VERSION "HNNBNNNYNNNNNNNNNNNNNNNNNNNNNNNNNNNNNNNNNN/4/%%%/4/'%**4NNN///"

NS_ :

BS_:

BU_: BAP_Tester BedienDisp_vo BedienSG_hi CGS DDA Gateway Gateway_PAG GurtMikrofon OTA_FC ZR_High ZR_LIMU ZR_MIB_TOP_ab_Gen3 ZR_Standard

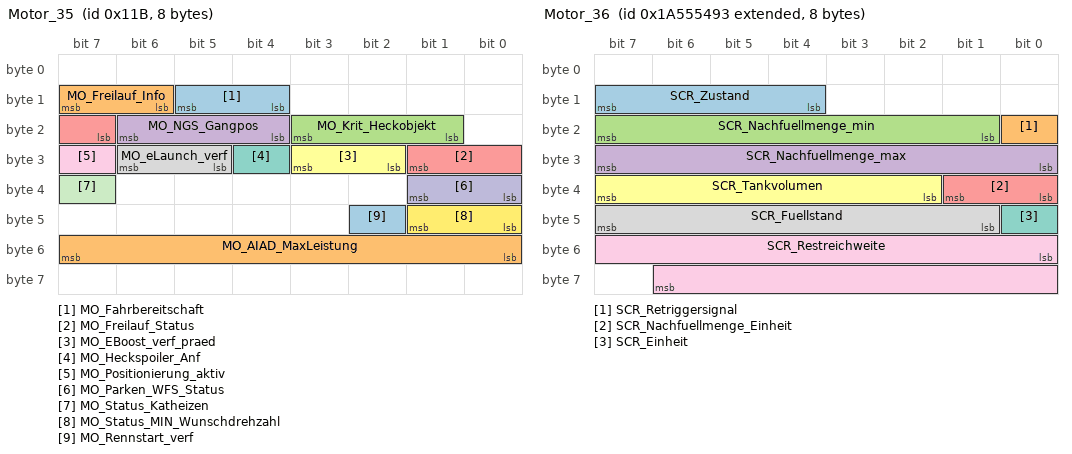
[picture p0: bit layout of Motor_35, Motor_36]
BO_ 283 Motor_35: 8 Gateway
 SG_ MO_Fahrbereitschaft : 12|2@1+ (1.0,0.0) [0.0|3] ""  DDA,OTA_FC
 SG_ MO_Freilauf_Info : 14|2@1+ (1.0,0.0) [0.0|3] ""  Vector__XXX
 SG_ MO_Krit_Heckobjekt : 17|3@1+ (1.0,0.0) [0.0|7] ""  ZR_High,ZR_LIMU,ZR_MIB_TOP_ab_Gen3
 SG_ MO_NGS_Gangpos : 20|3@1+ (1.0,0.0) [0.0|7] ""  Vector__XXX
 SG_ MO_Freilauf_Status : 23|3@1+ (1.0,0.0) [0.0|7] ""  Vector__XXX
 SG_ MO_EBoost_verf_praed : 26|2@1+ (1.0,0.0) [0.0|3] ""  Vector__XXX
 SG_ MO_Heckspoiler_Anf : 28|1@1+ (1.0,0.0) [0.0|1] ""  Vector__XXX
 SG_ MO_eLaunch_verf : 29|2@1+ (1.0,0.0) [0.0|3] ""  Vector__XXX
 SG_ MO_Positionierung_aktiv : 31|1@1+ (1.0,0.0) [0.0|1] ""  Vector__XXX
 SG_ MO_Parken_WFS_Status : 32|2@1+ (1.0,0.0) [0.0|3] ""  Vector__XXX
 SG_ MO_Status_Katheizen : 39|1@1+ (1.0,0.0) [0.0|1] ""  Vector__XXX
 SG_ MO_Status_MIN_Wunschdrehzahl : 40|2@1+ (1.0,0.0) [0.0|3] ""  Vector__XXX
 SG_ MO_Rennstart_verf : 42|1@1+ (1.0,0.0) [0.0|1] ""  Vector__XXX
 SG_ MO_AIAD_MaxLeistung : 48|8@1+ (100,0) [0|25400] "Unit_Watt"  Vector__XXX

BO_ 2589283475 Motor_36: 8 Gateway
 SG_ SCR_Zustand : 12|4@1+ (1.0,0.0) [0.0|15] ""  ZR_High,ZR_Standard
 SG_ SCR_Retriggersignal : 16|1@1+ (1.0,0.0) [0.0|1] ""  ZR_High,ZR_Standard
 SG_ SCR_Nachfuellmenge_min : 17|7@1+ (0.25,0) [0.00|31.50] ""  ZR_High,ZR_Standard
 SG_ SCR_Nachfuellmenge_max : 24|8@1+ (0.25,0) [0.00|63.50] ""  ZR_High,ZR_Standard
 SG_ SCR_Nachfuellmenge_Einheit : 32|2@1+ (1.0,0.0) [0.0|3] ""  ZR_High,ZR_Standard
 SG_ SCR_Tankvolumen : 34|6@1+ (1,0) [0|63] ""  ZR_High,ZR_Standard
 SG_ SCR_Einheit : 40|1@1+ (1.0,0.0) [0.0|1] ""  ZR_High,ZR_Standard
 SG_ SCR_Fuellstand : 41|7@1+ (1,0) [0|100] "Unit_PerCent"  ZR_High,ZR_Standard
 SG_ SCR_Restreichweite : 48|15@1+ (1,0) [0|32767] ""  ZR_High,ZR_Standard

BO_ 706 Motor_41: 8 Gateway
 SG_ MO_Anzeige_StSt_Text : 12|4@1+ (1.0,0.0) [0.0|15] ""  Vector__XXX
 SG_ MO_Anzeige_StSt_Symbol : 16|3@1+ (1.0,0.0) [0.0|7] ""  Vector__XXX
 SG_ MO_ADR_Status : 19|2@1+ (1.0,0.0) [0.0|3] ""  ZR_High
 SG_ MO_AGA_Sound_Texte : 21|2@1+ (1.0,0.0) [0.0|3] ""  Vector__XXX
 SG_ MO_Anzeige_FMAus_Text : 23|1@1+ (1.0,0.0) [0.0|1] ""  Vector__XXX
 SG_ MO_Fehler_MSpG : 24|1@1+ (1.0,0.0) [0.0|1] ""  Vector__XXX
 SG_ PEA_Texte : 25|3@1+ (1.0,0.0) [0.0|7] ""  Vector__XXX
 SG_ TSK_Ueberstimmt_vMax_FahrerInfo : 28|2@1+ (1.0,0.0) [0.0|3] ""  Vector__XXX
 SG_ MO_Avus_Motorschutz : 30|2@1+ (1.0,0.0) [0.0|3] ""  Vector__XXX
 SG_ MO_Rekuperationsstufe : 32|3@1+ (1.0,0.0) [0.0|7] ""  OTA_FC,ZR_MIB_TOP_ab_Gen3
 SG_ TSK_Einheit_vMax_FahrerInfo : 35|1@1+ (1.0,0.0) [0.0|1] ""  Vector__XXX
 SG_ TSK_Status_vMax_FahrerInfo : 36|2@1+ (1.0,0.0) [0.0|3] ""  Vector__XXX
 SG_ MO_Red_Fahrleistung : 38|3@1+ (1.0,0.0) [0.0|7] ""  Vector__XXX
 SG_ MO_Oel_Temp_Radsatz_Warn : 46|1@1+ (1.0,0.0) [0.0|1] ""  Vector__XXX
 SG_ MO_Anz_Kuehlerluefter : 47|3@1+ (1.0,0.0) [0.0|7] ""  Vector__XXX
 SG_ MO_im_Leerlauf : 50|1@1+ (1.0,0.0) [0.0|1] ""  Vector__XXX
 SG_ WIV_Enable_Oeldr_Motor : 51|1@1+ (1.0,0.0) [0.0|1] ""  Vector__XXX
 SG_ MO_OelMessung_Dauer : 52|4@1+ (15,15) [15|225] "Unit_Secon"  Vector__XXX
 SG_ TSK_vMax_FahrerInfo : 56|8@1+ (1,15) [16|270] ""  Vector__XXX

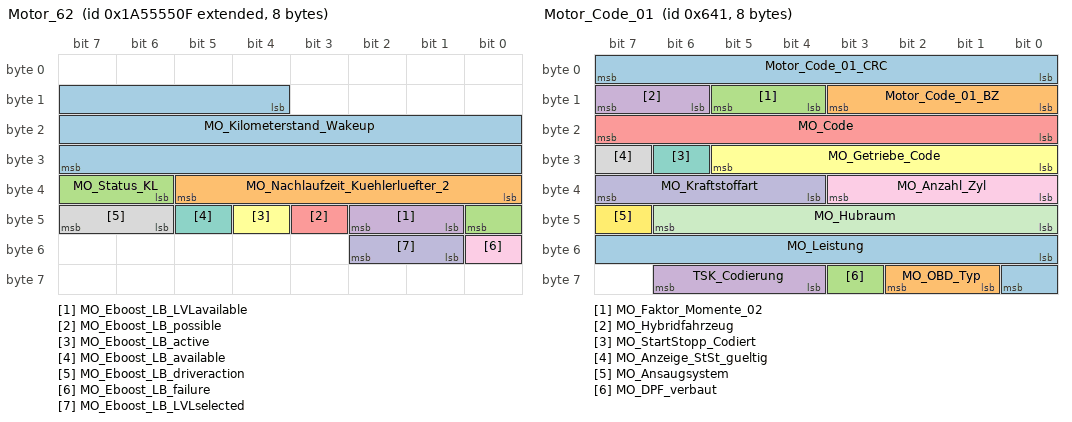
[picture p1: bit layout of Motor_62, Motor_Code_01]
BO_ 2589283599 Motor_62: 8 Gateway
 SG_ MO_Kilometerstand_Wakeup : 12|20@1+ (1,0) [0|1048573] "Unit_KiloMeter"  ZR_LIMU
 SG_ MO_Nachlaufzeit_Kuehlerluefter_2 : 32|6@1+ (15,0) [0|945] "Unit_Secon"  Vector__XXX
 SG_ MO_Status_KL : 38|3@1+ (1.0,0.0) [0.0|7] ""  Vector__XXX
 SG_ MO_Eboost_LB_LVLavailable : 41|2@1+ (1.0,0.0) [0.0|3] ""  Vector__XXX
 SG_ MO_Eboost_LB_possible : 43|1@1+ (1.0,0.0) [0.0|1] ""  Vector__XXX
 SG_ MO_Eboost_LB_active : 44|1@1+ (1.0,0.0) [0.0|1] ""  Vector__XXX
 SG_ MO_Eboost_LB_available : 45|1@1+ (1.0,0.0) [0.0|1] ""  Vector__XXX
 SG_ MO_Eboost_LB_driveraction : 46|2@1+ (1.0,0.0) [0.0|3] ""  Vector__XXX
 SG_ MO_Eboost_LB_failure : 48|1@1+ (1.0,0.0) [0.0|1] ""  Vector__XXX
 SG_ MO_Eboost_LB_LVLselected : 49|2@1+ (1.0,0.0) [0.0|3] ""  Vector__XXX

BO_ 1601 Motor_Code_01: 8 Gateway
 SG_ Motor_Code_01_CRC : 0|8@1+ (1,0) [0|255] ""  Vector__XXX
 SG_ Motor_Code_01_BZ : 8|4@1+ (1,0) [0|15] ""  Vector__XXX
 SG_ MO_Faktor_Momente_02 : 12|2@1+ (1,0) [1|3] "Unit_NewtoMeter"  ZR_High,ZR_LIMU,ZR_MIB_TOP_ab_Gen3,ZR_Standard
 SG_ MO_Hybridfahrzeug : 14|2@1+ (1.0,0.0) [0.0|3] ""  ZR_High
 SG_ MO_Code : 16|8@1+ (1,0) [0|255] ""  Vector__XXX
 SG_ MO_Getriebe_Code : 24|6@1+ (1.0,0.0) [0.0|63] ""  ZR_High,ZR_Standard
 SG_ MO_StartStopp_Codiert : 30|1@1+ (1.0,0.0) [0.0|1] ""  ZR_High
 SG_ MO_Anzeige_StSt_gueltig : 31|1@1+ (1.0,0.0) [0.0|1] ""  Vector__XXX
 SG_ MO_Anzahl_Zyl : 32|4@1+ (1.0,0.0) [0.0|15] ""  ZR_High
 SG_ MO_Kraftstoffart : 36|4@1+ (1.0,0.0) [0.0|15] ""  ZR_High,ZR_Standard
 SG_ MO_Hubraum : 40|7@1+ (0.1,0) [0.0|12.7] "Unit_Liter"  ZR_High
 SG_ MO_Ansaugsystem : 47|1@1+ (1.0,0.0) [0.0|1] ""  ZR_High
 SG_ MO_Leistung : 48|9@1+ (1,0) [0|511] "Unit_KiloWatt"  ZR_High
 SG_ MO_OBD_Typ : 57|2@1+ (1.0,0.0) [0.0|3] ""  ZR_High
 SG_ MO_DPF_verbaut : 59|1@1+ (1.0,0.0) [0.0|1] ""  ZR_High
 SG_ TSK_Codierung : 60|3@1+ (1.0,0.0) [0.0|7] ""  Vector__XXX

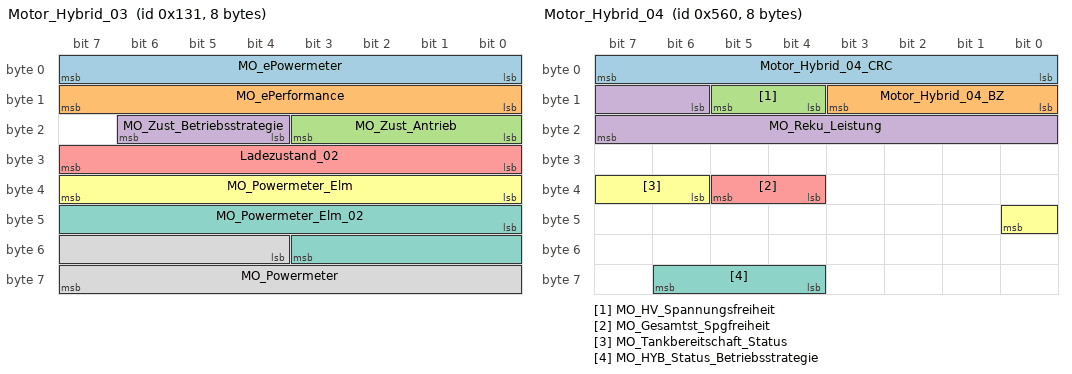
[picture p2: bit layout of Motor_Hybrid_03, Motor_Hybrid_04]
BO_ 305 Motor_Hybrid_03: 8 Gateway
 SG_ MO_ePowermeter : 0|8@1+ (0.4,-0.4) [0.0|100.8] "Unit_PerCent"  ZR_MIB_TOP_ab_Gen3
 SG_ MO_ePerformance : 8|8@1+ (0.4,-0.4) [0.0|100.8] "Unit_PerCent"  Vector__XXX
 SG_ MO_Zust_Antrieb : 16|4@1+ (1.0,0.0) [0.0|15] ""  OTA_FC
 SG_ MO_Zust_Betriebsstrategie : 20|3@1+ (1.0,0.0) [0.0|7] ""  Vector__XXX
 SG_ Ladezustand_02 : 24|8@1+ (0.5,0) [0.0|100.0] "Unit_PerCent"  ZR_High
 SG_ MO_Powermeter_Elm : 32|8@1+ (1,-128) [-100|100] "Unit_PerCent"  Vector__XXX
 SG_ MO_Powermeter_Elm_02 : 40|12@1+ (0.05,-102.4) [-100.00|100.00] "Unit_PerCent"  Vector__XXX
 SG_ MO_Powermeter : 52|12@1+ (1,0) [0|4092] ""  ZR_High,ZR_LIMU,ZR_MIB_TOP_ab_Gen3,ZR_Standard

BO_ 1376 Motor_Hybrid_04: 8 Gateway
 SG_ Motor_Hybrid_04_CRC : 0|8@1+ (1,0) [0|255] ""  Vector__XXX
 SG_ Motor_Hybrid_04_BZ : 8|4@1+ (1,0) [0|15] ""  Vector__XXX
 SG_ MO_HV_Spannungsfreiheit : 12|2@1+ (1.0,0.0) [0.0|3] ""  Vector__XXX
 SG_ MO_Reku_Leistung : 14|10@1+ (10,0) [0|10230] "Unit_Watt"  Vector__XXX
 SG_ MO_Gesamtst_Spgfreiheit : 36|2@1+ (1.0,0.0) [0.0|3] ""  Vector__XXX
 SG_ MO_Tankbereitschaft_Status : 38|3@1+ (1.0,0.0) [0.0|7] ""  ZR_High
 SG_ MO_HYB_Status_Betriebsstrategie : 60|3@1+ (1.0,0.0) [0.0|7] ""  Vector__XXX

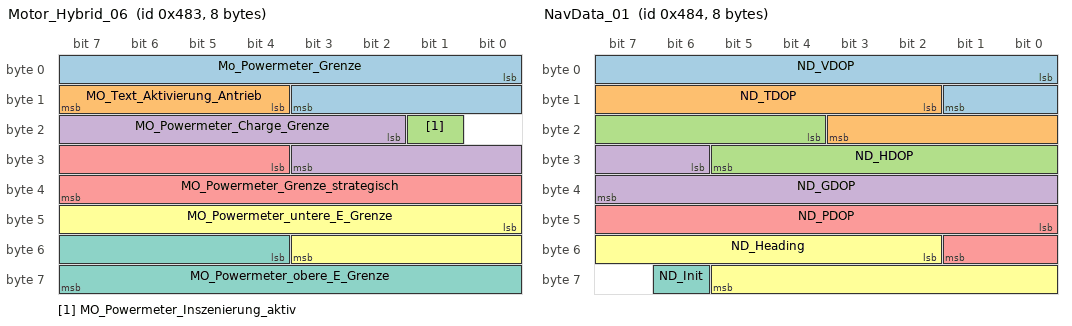
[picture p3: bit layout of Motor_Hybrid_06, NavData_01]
BO_ 1155 Motor_Hybrid_06: 8 Gateway
 SG_ Mo_Powermeter_Grenze : 0|12@1+ (1,0) [0|4092] ""  ZR_High,ZR_LIMU,ZR_MIB_TOP_ab_Gen3
 SG_ MO_Text_Aktivierung_Antrieb : 12|4@1+ (1.0,0.0) [0.0|15] ""  Vector__XXX
 SG_ MO_Powermeter_Inszenierung_aktiv : 17|1@1+ (1.0,0.0) [0.0|1] ""  Vector__XXX
 SG_ MO_Powermeter_Charge_Grenze : 18|10@1+ (1,0) [0|1021] "Unit_None"  ZR_MIB_TOP_ab_Gen3
 SG_ MO_Powermeter_Grenze_strategisch : 28|12@1+ (1,0) [0|4093] "Unit_None"  Vector__XXX
 SG_ MO_Powermeter_untere_E_Grenze : 40|12@1+ (1,0) [0|4093] "Unit_None"  Vector__XXX
 SG_ MO_Powermeter_obere_E_Grenze : 52|12@1+ (1,0) [0|4093] "Unit_None"  Vector__XXX

BO_ 1156 NavData_01: 8 ZR_High
 SG_ ND_VDOP : 0|10@1+ (0.025,0) [0.000|25.000] ""  BedienSG_hi,Gateway,Gateway_PAG
 SG_ ND_TDOP : 10|10@1+ (0.025,0) [0.000|25.000] ""  BedienSG_hi,Gateway,Gateway_PAG
 SG_ ND_HDOP : 20|10@1+ (0.025,0) [0.000|25.000] ""  BedienSG_hi,Gateway,Gateway_PAG,OTA_FC
 SG_ ND_GDOP : 30|10@1+ (0.025,0) [0.000|25.000] ""  BedienSG_hi,Gateway,Gateway_PAG
 SG_ ND_PDOP : 40|10@1+ (0.025,0) [0.000|25.000] ""  BedienSG_hi,Gateway,Gateway_PAG
 SG_ ND_Heading : 50|12@1+ (0.1,0) [0.0|359.9] "Unit_DegreOfArc"  BedienSG_hi,Gateway,Gateway_PAG,OTA_FC
 SG_ ND_Init : 62|1@1+ (1.0,0.0) [0.0|1] ""  Gateway,Gateway_PAG,OTA_FC

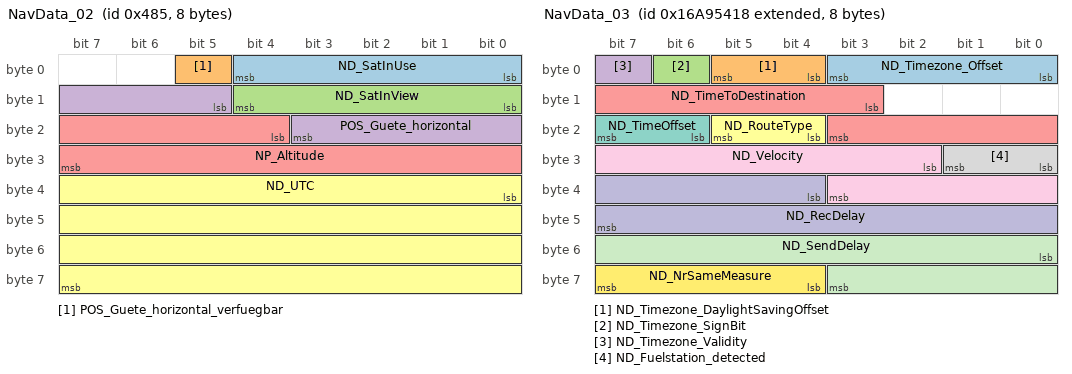
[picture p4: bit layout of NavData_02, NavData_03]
BO_ 1157 NavData_02: 8 ZR_High
 SG_ ND_SatInUse : 0|5@1+ (1,0) [0|29] ""  BedienSG_hi,Gateway,Gateway_PAG
 SG_ POS_Guete_horizontal_verfuegbar : 5|1@1+ (1.0,0.0) [0.0|1] ""  Gateway,Gateway_PAG
 SG_ ND_SatInView : 8|5@1+ (1,0) [0|29] ""  BedienSG_hi,Gateway,Gateway_PAG
 SG_ POS_Guete_horizontal : 13|7@1+ (2,0) [0|246] "Unit_Meter"  Gateway,Gateway_PAG
 SG_ NP_Altitude : 20|12@1+ (2,-500) [-500|7686] "Unit_Meter"  BedienSG_hi,Gateway,Gateway_PAG,OTA_FC
 SG_ ND_UTC : 32|32@1+ (1,0) [0|4294967293] "Unit_Secon"  BedienSG_hi,Gateway,Gateway_PAG

BO_ 2527679512 NavData_03: 8 ZR_High
 SG_ ND_Timezone_Offset : 0|4@1+ (1,0) [0|12] "Unit_Hours"  Gateway,Gateway_PAG
 SG_ ND_Timezone_DaylightSavingOffset : 4|2@1+ (30,0) [0|60] "Unit_Minut"  Gateway,Gateway_PAG
 SG_ ND_Timezone_SignBit : 6|1@1+ (1.0,0.0) [0.0|1] ""  Gateway,Gateway_PAG
 SG_ ND_Timezone_Validity : 7|1@1+ (1.0,0.0) [0.0|1] ""  Gateway,Gateway_PAG
 SG_ ND_TimeToDestination : 11|9@1+ (1,0) [0|509] "Unit_Minut"  Gateway,Gateway_PAG
 SG_ ND_RouteType : 20|2@1+ (1.0,0.0) [0.0|3] ""  Gateway,Gateway_PAG
 SG_ ND_TimeOffset : 22|2@1+ (1.0,0.0) [0.0|3] ""  Gateway,Gateway_PAG
 SG_ ND_Fuelstation_detected : 24|2@1+ (1.0,0.0) [0.0|3] ""  Gateway,Gateway_PAG
 SG_ ND_Velocity : 26|10@1+ (0.1,0) [0.0|102.1] "Unit_MeterPerSecon"  BedienSG_hi,Gateway,Gateway_PAG
 SG_ ND_RecDelay : 36|12@1+ (1,0) [0|4093] "Unit_MilliSecon"  BedienSG_hi,Gateway,Gateway_PAG
 SG_ ND_SendDelay : 48|12@1+ (1,0) [0|4093] "Unit_MilliSecon"  BedienSG_hi,Gateway,Gateway_PAG
 SG_ ND_NrSameMeasure : 60|4@1+ (1,0) [0|8] ""  BedienSG_hi,Gateway,Gateway_PAG

BO_ 2527679665 NavData_04: 8 ZR_High
 SG_ ND_Avrg_Speed_RangeData : 56|8@1+ (1,0) [0|253] "Unit_KiloMeterPerHour"  Gateway,Gateway_PAG

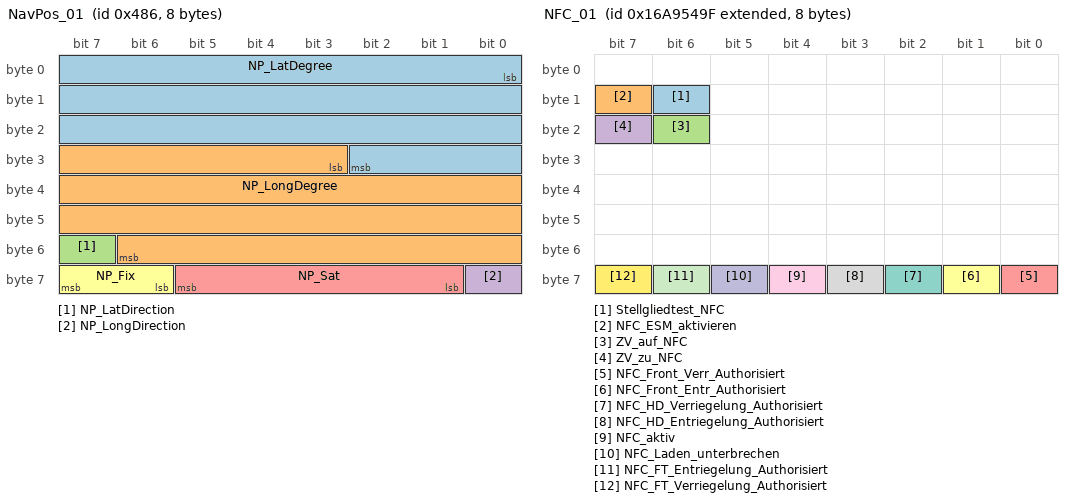
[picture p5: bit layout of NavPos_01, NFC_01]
BO_ 1158 NavPos_01: 8 ZR_High
 SG_ NP_LatDegree : 0|27@1+ (0.000001,0) [0.000000|90.000000] "Unit_DegreOfArc"  BedienSG_hi,Gateway,Gateway_PAG,OTA_FC
 SG_ NP_LongDegree : 27|28@1+ (0.000001,0) [0.000000|180.000000] "Unit_DegreOfArc"  BedienSG_hi,Gateway,Gateway_PAG,OTA_FC
 SG_ NP_LatDirection : 55|1@1+ (1.0,0.0) [0.0|1] ""  BedienSG_hi,Gateway,Gateway_PAG,OTA_FC
 SG_ NP_LongDirection : 56|1@1+ (1.0,0.0) [0.0|1] ""  BedienSG_hi,Gateway,Gateway_PAG,OTA_FC
 SG_ NP_Sat : 57|5@1+ (1,0) [0|29] ""  BedienSG_hi,Gateway,Gateway_PAG,OTA_FC
 SG_ NP_Fix : 62|2@1+ (1.0,0.0) [0.0|3] ""  BedienSG_hi,Gateway,Gateway_PAG,OTA_FC

BO_ 2589283496 NavPos_02_Map_Matched: 8 ZR_High
 SG_ POS_MUX M  : 0|2@1+ (1.0,0.0) [0.0|3] ""  Gateway,Gateway_PAG,OTA_FC
 SG_ POS_ODD_EVEN : 2|1@1+ (1.0,0.0) [0.0|1] ""  Gateway,Gateway_PAG,OTA_FC
 SG_ POS_PosStati m0  : 3|4@1+ (1.0,0.0) [0.0|15] ""  Gateway,Gateway_PAG,OTA_FC
 SG_ POS_Heading m1  : 4|12@1+ (0.1,0) [0.0|409.5] "Unit_DegreOfArc"  Gateway,Gateway_PAG,OTA_FC
 SG_ POS_LatDirection m0  : 7|1@1+ (1.0,0.0) [0.0|1] ""  Gateway,Gateway_PAG,OTA_FC
 SG_ POS_LatDegree m0  : 8|27@1+ (0.000001,0) [0.000000|90.000000] "Unit_DegreOfArc"  Gateway,Gateway_PAG,OTA_FC
 SG_ POS_Last_GPS_Sync m1  : 16|14@1+ (1,0) [0|16383] "Unit_Secon"  Gateway,Gateway_PAG,OTA_FC
 SG_ POS_Heading_Trust m1  : 30|2@1+ (1.0,0.0) [0.0|3] ""  Gateway,Gateway_PAG,OTA_FC
 SG_ POS_UTC_REF m1  : 32|32@1+ (1,0) [0|4294967295] "Unit_Secon"  Gateway,Gateway_PAG,OTA_FC
 SG_ POS_LongDirection m0  : 35|1@1+ (1.0,0.0) [0.0|1] ""  Gateway,Gateway_PAG,OTA_FC
 SG_ POS_LongDegree m0  : 36|28@1+ (0.000001,0) [0.000000|180.000000] "Unit_DegreOfArc"  Gateway,Gateway_PAG,OTA_FC

BO_ 2527679647 NFC_01: 8 Gateway
 SG_ Stellgliedtest_NFC : 14|1@1+ (1.0,0.0) [0.0|1] ""  ZR_High,ZR_LIMU,ZR_MIB_TOP_ab_Gen3,ZR_Standard
 SG_ NFC_ESM_aktivieren : 15|1@1+ (1.0,0.0) [0.0|1] ""  ZR_High,ZR_LIMU,ZR_MIB_TOP_ab_Gen3,ZR_Standard
 SG_ ZV_auf_NFC : 22|1@1+ (1.0,0.0) [0.0|1] ""  ZR_High,ZR_LIMU,ZR_MIB_TOP_ab_Gen3,ZR_Standard
 SG_ ZV_zu_NFC : 23|1@1+ (1.0,0.0) [0.0|1] ""  ZR_High,ZR_LIMU,ZR_MIB_TOP_ab_Gen3,ZR_Standard
 SG_ NFC_Front_Verr_Authorisiert : 56|1@1+ (1.0,0.0) [0.0|1] ""  ZR_High,ZR_LIMU,ZR_MIB_TOP_ab_Gen3,ZR_Standard
 SG_ NFC_Front_Entr_Authorisiert : 57|1@1+ (1.0,0.0) [0.0|1] ""  ZR_High,ZR_LIMU,ZR_MIB_TOP_ab_Gen3,ZR_Standard
 SG_ NFC_HD_Verriegelung_Authorisiert : 58|1@1+ (1.0,0.0) [0.0|1] ""  ZR_High,ZR_LIMU,ZR_MIB_TOP_ab_Gen3,ZR_Standard
 SG_ NFC_HD_Entriegelung_Authorisiert : 59|1@1+ (1.0,0.0) [0.0|1] ""  ZR_High,ZR_LIMU,ZR_MIB_TOP_ab_Gen3,ZR_Standard
 SG_ NFC_aktiv : 60|1@1+ (1.0,0.0) [0.0|1] ""  ZR_High,ZR_LIMU,ZR_MIB_TOP_ab_Gen3,ZR_Standard
 SG_ NFC_Laden_unterbrechen : 61|1@1+ (1.0,0.0) [0.0|1] ""  ZR_High,ZR_LIMU,ZR_MIB_TOP_ab_Gen3,ZR_Standard
 SG_ NFC_FT_Entriegelung_Authorisiert : 62|1@1+ (1.0,0.0) [0.0|1] ""  ZR_High,ZR_LIMU,ZR_MIB_TOP_ab_Gen3,ZR_Standard
 SG_ NFC_FT_Verriegelung_Authorisiert : 63|1@1+ (1.0,0.0) [0.0|1] ""  ZR_High,ZR_LIMU,ZR_MIB_TOP_ab_Gen3,ZR_Standard

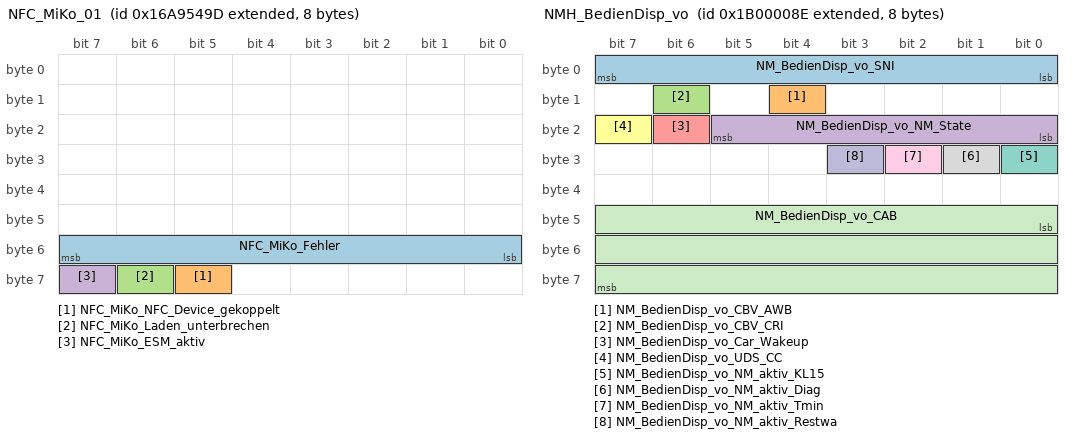
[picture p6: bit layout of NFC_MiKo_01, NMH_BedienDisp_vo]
BO_ 2527679645 NFC_MiKo_01: 8 Gateway
 SG_ NFC_MiKo_Fehler : 48|8@1+ (1.0,0.0) [0.0|255] ""  ZR_LIMU,ZR_MIB_TOP_ab_Gen3
 SG_ NFC_MiKo_NFC_Device_gekoppelt : 61|1@1+ (1.0,0.0) [0.0|1] ""  ZR_LIMU,ZR_MIB_TOP_ab_Gen3
 SG_ NFC_MiKo_Laden_unterbrechen : 62|1@1+ (1.0,0.0) [0.0|1] ""  ZR_LIMU,ZR_MIB_TOP_ab_Gen3
 SG_ NFC_MiKo_ESM_aktiv : 63|1@1+ (1.0,0.0) [0.0|1] ""  ZR_LIMU,ZR_MIB_TOP_ab_Gen3

BO_ 1696 NightVision_01: 8 Gateway
 SG_ NV_aktiv : 12|1@1+ (1.0,0.0) [0.0|1] ""  ZR_High
 SG_ NV_Texte : 13|3@1+ (1.0,0.0) [0.0|7] ""  ZR_High
 SG_ NV_Gong : 16|2@1+ (1.0,0.0) [0.0|3] ""  ZR_High
 SG_ NV_Symbol : 18|1@1+ (1.0,0.0) [0.0|1] ""  ZR_High
 SG_ NV_Hinweise : 19|2@1+ (1.0,0.0) [0.0|3] ""  ZR_High
 SG_ NV_Piktogramm_aktiv : 21|1@1+ (1.0,0.0) [0.0|1] ""  ZR_High
 SG_ NV_Akustik_deaktiviert_Icon : 22|1@1+ (1.0,0.0) [0.0|1] ""  ZR_High
 SG_ NV_FGM_deaktiviert_Icon : 23|1@1+ (1.0,0.0) [0.0|1] ""  ZR_High
 SG_ NV_Markierungslicht_links : 24|1@1+ (1.0,0.0) [0.0|1] ""  ZR_High
 SG_ NV_Markierungslicht_rechts : 25|1@1+ (1.0,0.0) [0.0|1] ""  ZR_High
 SG_ NV_Symbol_Tierwarnung : 26|1@1+ (1.0,0.0) [0.0|1] ""  ZR_High
 SG_ NV_Anf_Prefill : 27|1@1+ (1.0,0.0) [0.0|1] ""  ZR_High
 SG_ NV_HBA_Parameter : 28|2@1+ (1.0,0.0) [0.0|3] ""  Vector__XXX
 SG_ NV_LED_Leiste : 30|2@1+ (1.0,0.0) [0.0|3] ""  ZR_High
 SG_ NV_PreSense_Status : 32|2@1+ (1.0,0.0) [0.0|3] ""  Vector__XXX
 SG_ NV_PreSense_Modus_System : 34|1@1+ (1.0,0.0) [0.0|1] ""  Vector__XXX
 SG_ NV_PreSense_Modus_Warnung : 35|3@1+ (1.0,0.0) [0.0|7] ""  Vector__XXX
 SG_ NV_FAS_Fkt_Status : 38|2@1+ (1.0,0.0) [0.0|3] ""  Vector__XXX
 SG_ NV_Akt_Status_MMI : 40|2@1+ (1.0,0.0) [0.0|3] ""  Vector__XXX
 SG_ NV_AnforderungBildaufschaltung : 42|1@1+ (1.0,0.0) [0.0|1] ""  Vector__XXX

BO_ 2600468622 NMH_BedienDisp_vo: 8 BedienDisp_vo
 SG_ NM_BedienDisp_vo_SNI : 0|8@1+ (1.0,0.0) [0.0|255] ""  BedienDisp_vo,BedienSG_hi,DDA,Gateway,Gateway_PAG,OTA_FC,ZR_High,ZR_LIMU,ZR_MIB_TOP_ab_Gen3,ZR_Standard
 SG_ NM_BedienDisp_vo_CBV_AWB : 12|1@1+ (1.0,0.0) [0.0|1] ""  Gateway,Gateway_PAG
 SG_ NM_BedienDisp_vo_CBV_CRI : 14|1@1+ (1.0,0.0) [0.0|1] ""  BedienDisp_vo,BedienSG_hi,DDA,Gateway,Gateway_PAG,OTA_FC,ZR_High,ZR_LIMU,ZR_MIB_TOP_ab_Gen3,ZR_Standard
 SG_ NM_BedienDisp_vo_NM_State : 16|6@1+ (1.0,0.0) [0.0|63] ""  Vector__XXX
 SG_ NM_BedienDisp_vo_Car_Wakeup : 22|1@1+ (1.0,0.0) [0.0|1] ""  Gateway,Gateway_PAG
 SG_ NM_BedienDisp_vo_UDS_CC : 23|1@1+ (1.0,0.0) [0.0|1] ""  Vector__XXX
 SG_ NM_BedienDisp_vo_NM_aktiv_KL15 : 24|1@1+ (1.0,0.0) [0.0|1] ""  Vector__XXX
 SG_ NM_BedienDisp_vo_NM_aktiv_Diag : 25|1@1+ (1.0,0.0) [0.0|1] ""  Vector__XXX
 SG_ NM_BedienDisp_vo_NM_aktiv_Tmin : 26|1@1+ (1.0,0.0) [0.0|1] ""  Vector__XXX
 SG_ NM_BedienDisp_vo_NM_aktiv_Restwa : 27|1@1+ (1.0,0.0) [0.0|1] ""  Vector__XXX
 SG_ NM_BedienDisp_vo_CAB : 40|24@1+ (1.0,0.0) [0.0|16777215] ""  BedienDisp_vo,BedienSG_hi,DDA,Gateway,Gateway_PAG,OTA_FC,ZR_High,ZR_LIMU,ZR_MIB_TOP_ab_Gen3,ZR_Standard

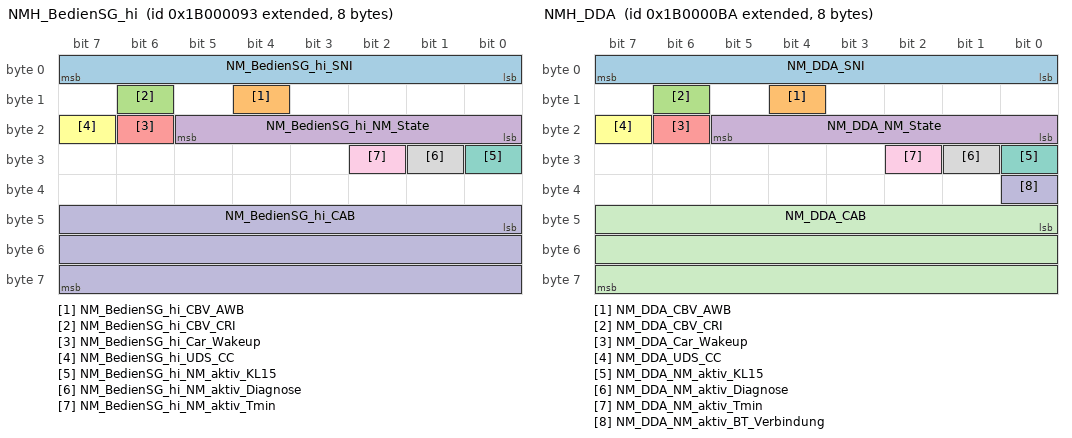
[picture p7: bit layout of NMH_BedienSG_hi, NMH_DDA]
BO_ 2600468627 NMH_BedienSG_hi: 8 BedienSG_hi
 SG_ NM_BedienSG_hi_SNI : 0|8@1+ (1.0,0.0) [0.0|255] ""  BedienDisp_vo,BedienSG_hi,DDA,Gateway,Gateway_PAG,OTA_FC,ZR_High,ZR_LIMU,ZR_MIB_TOP_ab_Gen3,ZR_Standard
 SG_ NM_BedienSG_hi_CBV_AWB : 12|1@1+ (1.0,0.0) [0.0|1] ""  Gateway,Gateway_PAG
 SG_ NM_BedienSG_hi_CBV_CRI : 14|1@1+ (1.0,0.0) [0.0|1] ""  BedienDisp_vo,BedienSG_hi,DDA,Gateway,Gateway_PAG,OTA_FC,ZR_High,ZR_LIMU,ZR_MIB_TOP_ab_Gen3,ZR_Standard
 SG_ NM_BedienSG_hi_NM_State : 16|6@1+ (1.0,0.0) [0.0|63] ""  Vector__XXX
 SG_ NM_BedienSG_hi_Car_Wakeup : 22|1@1+ (1.0,0.0) [0.0|1] ""  Gateway,Gateway_PAG
 SG_ NM_BedienSG_hi_UDS_CC : 23|1@1+ (1.0,0.0) [0.0|1] ""  Vector__XXX
 SG_ NM_BedienSG_hi_NM_aktiv_KL15 : 24|1@1+ (1.0,0.0) [0.0|1] ""  Vector__XXX
 SG_ NM_BedienSG_hi_NM_aktiv_Diagnose : 25|1@1+ (1.0,0.0) [0.0|1] ""  Vector__XXX
 SG_ NM_BedienSG_hi_NM_aktiv_Tmin : 26|1@1+ (1.0,0.0) [0.0|1] ""  Vector__XXX
 SG_ NM_BedienSG_hi_CAB : 40|24@1+ (1.0,0.0) [0.0|16777215] ""  BedienDisp_vo,BedienSG_hi,DDA,Gateway,Gateway_PAG,OTA_FC,ZR_High,ZR_LIMU,ZR_MIB_TOP_ab_Gen3,ZR_Standard

BO_ 2600468666 NMH_DDA: 8 DDA
 SG_ NM_DDA_SNI : 0|8@1+ (1.0,0.0) [0.0|255] ""  BedienDisp_vo,BedienSG_hi,Gateway,Gateway_PAG,OTA_FC,ZR_High,ZR_LIMU,ZR_MIB_TOP_ab_Gen3,ZR_Standard
 SG_ NM_DDA_CBV_AWB : 12|1@1+ (1.0,0.0) [0.0|1] ""  Vector__XXX
 SG_ NM_DDA_CBV_CRI : 14|1@1+ (1.0,0.0) [0.0|1] ""  BedienDisp_vo,BedienSG_hi,Gateway,Gateway_PAG,OTA_FC,ZR_High,ZR_LIMU,ZR_MIB_TOP_ab_Gen3,ZR_Standard
 SG_ NM_DDA_NM_State : 16|6@1+ (1.0,0.0) [0.0|63] ""  Vector__XXX
 SG_ NM_DDA_Car_Wakeup : 22|1@1+ (1.0,0.0) [0.0|1] ""  Gateway,Gateway_PAG
 SG_ NM_DDA_UDS_CC : 23|1@1+ (1.0,0.0) [0.0|1] ""  Vector__XXX
 SG_ NM_DDA_NM_aktiv_KL15 : 24|1@1+ (1.0,0.0) [0.0|1] ""  Vector__XXX
 SG_ NM_DDA_NM_aktiv_Diagnose : 25|1@1+ (1.0,0.0) [0.0|1] ""  Vector__XXX
 SG_ NM_DDA_NM_aktiv_Tmin : 26|1@1+ (1.0,0.0) [0.0|1] ""  Vector__XXX
 SG_ NM_DDA_NM_aktiv_BT_Verbindung : 32|1@1+ (1.0,0.0) [0.0|1] ""  Vector__XXX
 SG_ NM_DDA_CAB : 40|24@1+ (1.0,0.0) [0.0|16777215] ""  BedienDisp_vo,BedienSG_hi,Gateway,Gateway_PAG,OTA_FC,ZR_High,ZR_LIMU,ZR_MIB_TOP_ab_Gen3,ZR_Standard

BO_ 2600468496 NMH_Gateway: 8 Gateway
 SG_ NM_Gateway_SNI : 0|8@1+ (1.0,0.0) [0.0|255] ""  BedienDisp_vo,BedienSG_hi,DDA,OTA_FC,ZR_High,ZR_LIMU,ZR_MIB_TOP_ab_Gen3,ZR_Standard
 SG_ NM_Gateway_CBV_AWB : 12|1@1+ (1.0,0.0) [0.0|1] ""  Vector__XXX
 SG_ NM_Gateway_CBV_CRI : 14|1@1+ (1.0,0.0) [0.0|1] ""  BedienDisp_vo,BedienSG_hi,DDA,OTA_FC,ZR_High,ZR_LIMU,ZR_MIB_TOP_ab_Gen3,ZR_Standard
 SG_ NM_Gateway_NM_State : 16|6@1+ (1.0,0.0) [0.0|63] ""  Vector__XXX
 SG_ NM_Gateway_Car_Wakeup : 22|1@1+ (1.0,0.0) [0.0|1] ""  Vector__XXX
 SG_ NM_Gateway_UDS_CC : 23|1@1+ (1.0,0.0) [0.0|1] ""  Vector__XXX
 SG_ NM_Gateway_NM_aktiv_KL15 : 24|1@1+ (1.0,0.0) [0.0|1] ""  Vector__XXX
 SG_ NM_Gateway_NM_aktiv_Diagnose : 25|1@1+ (1.0,0.0) [0.0|1] ""  Vector__XXX
 SG_ NM_Gateway_NM_aktiv_Tmin : 26|1@1+ (1.0,0.0) [0.0|1] ""  Vector__XXX
 SG_ NM_Gateway_NM_aktiv_CWU : 27|1@1+ (1.0,0.0) [0.0|1] ""  Vector__XXX
 SG_ NM_Gateway_NM_aktiv_FC : 28|1@1+ (1.0,0.0) [0.0|1] ""  Vector__XXX
 SG_ NM_Gateway_NM_aktiv_Connect : 29|1@1+ (1.0,0.0) [0.0|1] ""  Vector__XXX
 SG_ NM_Gateway_NM_aktiv_EM : 30|1@1+ (1.0,0.0) [0.0|1] ""  Vector__XXX
 SG_ NM_Gateway_NM_aktiv_OBDC : 31|1@1+ (1.0,0.0) [0.0|1] ""  Vector__XXX
 SG_ NM_Gateway_NM_aktiv_Buskopplung : 32|1@1+ (1.0,0.0) [0.0|1] ""  Vector__XXX
 SG_ NM_Gateway_NM_aktiv_LIN2 : 33|1@1+ (1.0,0.0) [0.0|1] ""  Vector__XXX
 SG_ NM_Gateway_CAB : 40|24@1+ (1.0,0.0) [0.0|16777215] ""  BedienDisp_vo,BedienSG_hi,DDA,OTA_FC,ZR_High,ZR_LIMU,ZR_MIB_TOP_ab_Gen3,ZR_Standard

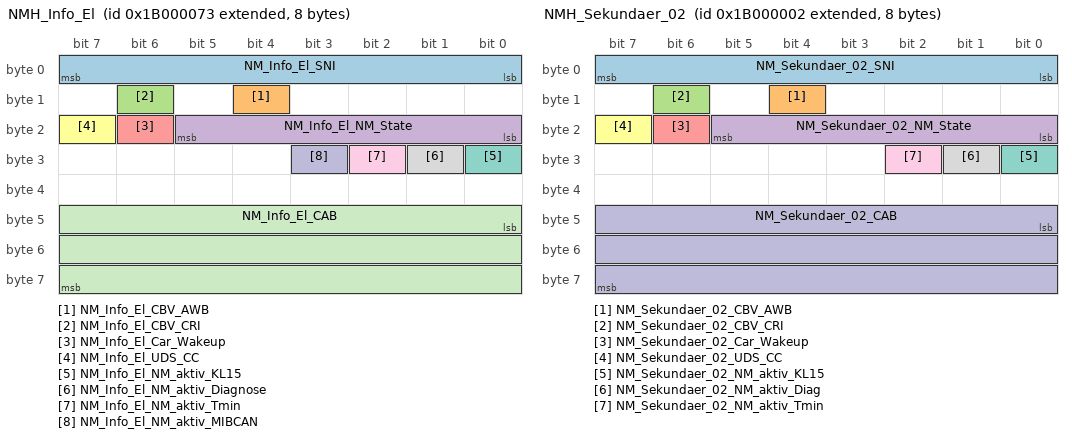
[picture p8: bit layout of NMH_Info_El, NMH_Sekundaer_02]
BO_ 2600468595 NMH_Info_El: 8 ZR_High
 SG_ NM_Info_El_SNI : 0|8@1+ (1.0,0.0) [0.0|255] ""  BedienDisp_vo,BedienSG_hi,DDA,Gateway,Gateway_PAG,OTA_FC,ZR_High,ZR_LIMU,ZR_MIB_TOP_ab_Gen3,ZR_Standard
 SG_ NM_Info_El_CBV_AWB : 12|1@1+ (1.0,0.0) [0.0|1] ""  Gateway,Gateway_PAG
 SG_ NM_Info_El_CBV_CRI : 14|1@1+ (1.0,0.0) [0.0|1] ""  BedienDisp_vo,BedienSG_hi,DDA,Gateway,Gateway_PAG,OTA_FC,ZR_High,ZR_LIMU,ZR_MIB_TOP_ab_Gen3,ZR_Standard
 SG_ NM_Info_El_NM_State : 16|6@1+ (1.0,0.0) [0.0|63] ""  Vector__XXX
 SG_ NM_Info_El_Car_Wakeup : 22|1@1+ (1.0,0.0) [0.0|1] ""  Gateway,Gateway_PAG
 SG_ NM_Info_El_UDS_CC : 23|1@1+ (1.0,0.0) [0.0|1] ""  Vector__XXX
 SG_ NM_Info_El_NM_aktiv_KL15 : 24|1@1+ (1.0,0.0) [0.0|1] ""  Vector__XXX
 SG_ NM_Info_El_NM_aktiv_Diagnose : 25|1@1+ (1.0,0.0) [0.0|1] ""  Vector__XXX
 SG_ NM_Info_El_NM_aktiv_Tmin : 26|1@1+ (1.0,0.0) [0.0|1] ""  Vector__XXX
 SG_ NM_Info_El_NM_aktiv_MIBCAN : 27|1@1+ (1.0,0.0) [0.0|1] ""  Vector__XXX
 SG_ NM_Info_El_CAB : 40|24@1+ (1.0,0.0) [0.0|16777215] ""  BedienDisp_vo,BedienSG_hi,DDA,Gateway,Gateway_PAG,OTA_FC,ZR_High,ZR_LIMU,ZR_MIB_TOP_ab_Gen3,ZR_Standard

BO_ 2600468482 NMH_Sekundaer_02: 8 OTA_FC
 SG_ NM_Sekundaer_02_SNI : 0|8@1+ (1.0,0.0) [0.0|255] ""  Gateway,Gateway_PAG
 SG_ NM_Sekundaer_02_CBV_AWB : 12|1@1+ (1.0,0.0) [0.0|1] ""  Gateway,Gateway_PAG
 SG_ NM_Sekundaer_02_CBV_CRI : 14|1@1+ (1.0,0.0) [0.0|1] ""  Gateway_PAG
 SG_ NM_Sekundaer_02_NM_State : 16|6@1+ (1.0,0.0) [0.0|63] ""  Vector__XXX
 SG_ NM_Sekundaer_02_Car_Wakeup : 22|1@1+ (1.0,0.0) [0.0|1] ""  Gateway,Gateway_PAG
 SG_ NM_Sekundaer_02_UDS_CC : 23|1@1+ (1.0,0.0) [0.0|1] ""  Vector__XXX
 SG_ NM_Sekundaer_02_NM_aktiv_KL15 : 24|1@1+ (1.0,0.0) [0.0|1] ""  Vector__XXX
 SG_ NM_Sekundaer_02_NM_aktiv_Diag : 25|1@1+ (1.0,0.0) [0.0|1] ""  Vector__XXX
 SG_ NM_Sekundaer_02_NM_aktiv_Tmin : 26|1@1+ (1.0,0.0) [0.0|1] ""  Vector__XXX
 SG_ NM_Sekundaer_02_CAB : 40|24@1+ (1.0,0.0) [0.0|16777215] ""  Gateway,Gateway_PAG

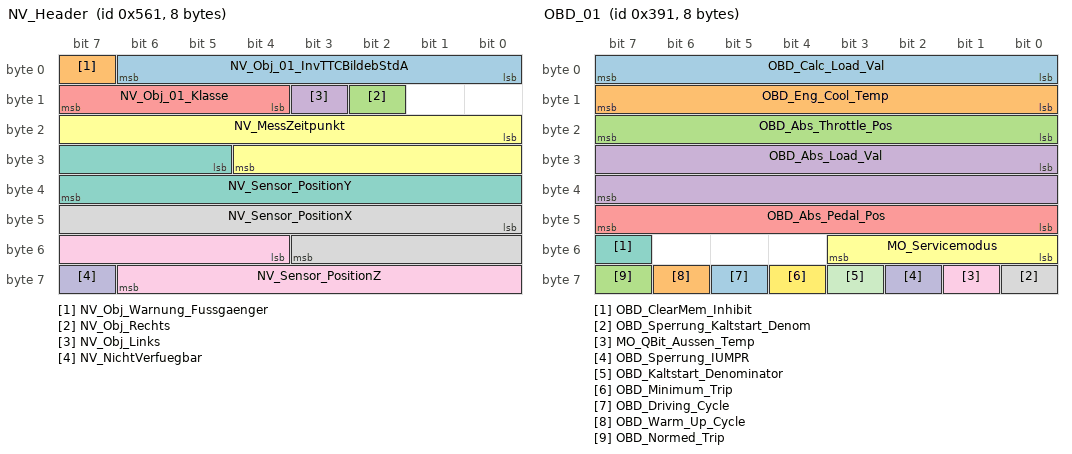
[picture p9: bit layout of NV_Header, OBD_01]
BO_ 1377 NV_Header: 8 Gateway
 SG_ NV_Obj_01_InvTTCBildebStdA : 0|7@1+ (0.0625,0) [0.0000|7.8750] "Unit_Hertz"  Vector__XXX
 SG_ NV_Obj_Warnung_Fussgaenger : 7|1@1+ (1.0,0.0) [0.0|1] ""  ZR_High
 SG_ NV_Obj_Rechts : 10|1@1+ (1.0,0.0) [0.0|1] ""  Vector__XXX
 SG_ NV_Obj_Links : 11|1@1+ (1.0,0.0) [0.0|1] ""  Vector__XXX
 SG_ NV_Obj_01_Klasse : 12|4@1+ (1.0,0.0) [0.0|15] ""  Vector__XXX
 SG_ NV_MessZeitpunkt : 16|13@1+ (0.001,0) [0.000|8.190] "Unit_Secon"  Vector__XXX
 SG_ NV_Sensor_PositionY : 29|11@1+ (0.001,-1) [-1.000|1.046] "Unit_Meter"  Vector__XXX
 SG_ NV_Sensor_PositionX : 40|12@1+ (0.001,1) [1.000|5.094] "Unit_Meter"  Vector__XXX
 SG_ NV_Sensor_PositionZ : 52|11@1+ (0.001,0) [0.000|2.046] "Unit_Meter"  Vector__XXX
 SG_ NV_NichtVerfuegbar : 63|1@1+ (1.0,0.0) [0.0|1] ""  Vector__XXX

BO_ 1635 NVEM_02: 8 Gateway
 SG_ BEM_02_Abschaltstufen : 0|3@1+ (1.0,0.0) [0.0|7] ""  BedienDisp_vo,BedienSG_hi,DDA,OTA_FC,ZR_High,ZR_LIMU,ZR_MIB_TOP_ab_Gen3,ZR_Standard
 SG_ BEM_STH_Zielzeit : 3|4@1+ (5,0) [0|60] "Unit_Minut"  ZR_High,ZR_LIMU,ZR_MIB_TOP_ab_Gen3,ZR_Standard
 SG_ BEM_MMI_Vorwarnung : 7|1@1+ (1.0,0.0) [0.0|1] ""  ZR_High,ZR_LIMU,ZR_MIB_TOP_ab_Gen3,ZR_Standard
 SG_ NVEM_Anf_SD_schalten : 15|1@1+ (1.0,0.0) [0.0|1] ""  ZR_High,ZR_LIMU,ZR_MIB_TOP_ab_Gen3,ZR_Standard
 SG_ BEM_Generatordiagnose : 16|2@1+ (1.0,0.0) [0.0|3] ""  ZR_High,ZR_LIMU,ZR_MIB_TOP_ab_Gen3,ZR_Standard
 SG_ BEM_Red_Innengeblaese : 18|2@1+ (1.0,0.0) [0.0|3] ""  ZR_High,ZR_LIMU,ZR_MIB_TOP_ab_Gen3,ZR_Standard
 SG_ BEM_STH_Einschaltverbot : 20|1@1+ (1.0,0.0) [0.0|1] ""  ZR_High,ZR_LIMU,ZR_MIB_TOP_ab_Gen3,ZR_Standard
 SG_ BEM_HL_Regelung_Status : 21|3@1+ (1.0,0.0) [0.0|7] ""  ZR_High,ZR_LIMU,ZR_MIB_TOP_ab_Gen3,ZR_Standard
 SG_ BEM_Ladezustand : 24|4@1+ (10,0) [0|100] "Unit_PerCent"  OTA_FC,ZR_High,ZR_LIMU,ZR_MIB_TOP_ab_Gen3,ZR_Standard
 SG_ BEM_Batteriediagnose : 28|3@1+ (1.0,0.0) [0.0|7] ""  ZR_High,ZR_LIMU,ZR_MIB_TOP_ab_Gen3,ZR_Standard
 SG_ MIB_Stromsparmodus : 31|1@1+ (1.0,0.0) [0.0|1] ""  ZR_High,ZR_LIMU,ZR_MIB_TOP_ab_Gen3,ZR_Standard
 SG_ BEM_REK_aktiv : 37|1@1+ (1.0,0.0) [0.0|1] ""  ZR_High,ZR_LIMU,ZR_MIB_TOP_ab_Gen3,ZR_Standard
 SG_ NVEM_Last_Anf : 38|2@1+ (1.0,0.0) [0.0|3] ""  ZR_High,ZR_LIMU,ZR_MIB_TOP_ab_Gen3,ZR_Standard
 SG_ BEM_UBDM : 40|8@1+ (0.05,5) [5.05|17.70] "Unit_Volt"  ZR_High,ZR_LIMU,ZR_MIB_TOP_ab_Gen3,ZR_Standard
 SG_ BEM_UGenSoll : 48|6@1+ (0.1,10.6) [10.6|16.0] "Unit_Volt"  ZR_High,ZR_LIMU,ZR_MIB_TOP_ab_Gen3,ZR_Standard
 SG_ BEM_Anf_KL15_schalten : 54|2@1+ (1.0,0.0) [0.0|3] ""  ZR_High,ZR_LIMU,ZR_MIB_TOP_ab_Gen3,ZR_Standard
 SG_ NVEM_Batterie_Service : 56|2@1+ (1.0,0.0) [0.0|3] ""  ZR_High,ZR_LIMU,ZR_MIB_TOP_ab_Gen3,ZR_Standard
 SG_ NVEM_Freigabe_OnlineUpdate : 58|1@1+ (1.0,0.0) [0.0|1] ""  ZR_High,ZR_LIMU,ZR_MIB_TOP_ab_Gen3,ZR_Standard
 SG_ NVEM_Freigabe_ORU4 : 59|2@1+ (1.0,0.0) [0.0|3] ""  OTA_FC,ZR_High,ZR_LIMU,ZR_MIB_TOP_ab_Gen3,ZR_Standard

BO_ 913 OBD_01: 8 Gateway
 SG_ OBD_Calc_Load_Val : 0|8@1+ (0.39215686274509803,0) [0E-17|99.99999999999999765] "Unit_PerCent"  Vector__XXX
 SG_ OBD_Eng_Cool_Temp : 8|8@1+ (1,-40) [-40|215] "Unit_DegreCelsi"  ZR_High
 SG_ OBD_Abs_Throttle_Pos : 16|8@1+ (0.39215686274509803,0) [0E-17|99.99999999999999765] "Unit_PerCent"  ZR_High
 SG_ OBD_Abs_Load_Val : 24|16@1+ (0.39215686274509803,0) [0E-17|25699.99999999999939605] "Unit_PerCent"  Vector__XXX
 SG_ OBD_Abs_Pedal_Pos : 40|8@1+ (0.39215686274509803,0) [0E-17|99.99999999999999765] "Unit_PerCent"  ZR_High
 SG_ MO_Servicemodus : 48|4@1+ (1.0,0.0) [0.0|15] ""  Vector__XXX
 SG_ OBD_ClearMem_Inhibit : 55|1@1+ (1.0,0.0) [0.0|1] ""  Vector__XXX
 SG_ OBD_Sperrung_Kaltstart_Denom : 56|1@1+ (1.0,0.0) [0.0|1] ""  Vector__XXX
 SG_ MO_QBit_Aussen_Temp : 57|1@1+ (1.0,0.0) [0.0|1] ""  ZR_High
 SG_ OBD_Sperrung_IUMPR : 58|1@1+ (1.0,0.0) [0.0|1] ""  Vector__XXX
 SG_ OBD_Kaltstart_Denominator : 59|1@1+ (1.0,0.0) [0.0|1] ""  Vector__XXX
 SG_ OBD_Minimum_Trip : 60|1@1+ (1.0,0.0) [0.0|1] ""  Vector__XXX
 SG_ OBD_Driving_Cycle : 61|1@1+ (1.0,0.0) [0.0|1] ""  ZR_MIB_TOP_ab_Gen3
 SG_ OBD_Warm_Up_Cycle : 62|1@1+ (1.0,0.0) [0.0|1] ""  Vector__XXX
 SG_ OBD_Normed_Trip : 63|1@1+ (1.0,0.0) [0.0|1] ""  Vector__XXX

BO_ 2549875311 OBDC_AMP_Req: 8 Gateway
 SG_ OBDC_AMP_Req_Data : 0|64@1+ (1.0,0.0) [0.0|18446744073709551615] ""  ZR_High,ZR_MIB_TOP_ab_Gen3,ZR_Standard

BO_ 2550006383 OBDC_AMP_Resp: 8 ZR_High
 SG_ OBDC_AMP_Resp_Data : 0|64@1+ (1.0,0.0) [0.0|18446744073709551615] ""  Gateway,Gateway_PAG

BO_ 2549875342 OBDC_BedienDisp_vo_Req: 8 Gateway
 SG_ OBDC_BedienDisp_vo_Req_Data : 0|64@1+ (1.0,0.0) [0.0|18446744073709551615] ""  BedienDisp_vo

BO_ 2550006414 OBDC_BedienDisp_vo_Resp: 8 BedienDisp_vo
 SG_ OBDC_BedienDisp_vo_Resp_Data : 0|64@1+ (1.0,0.0) [0.0|18446744073709551615] ""  Gateway,Gateway_PAG

BO_ 2549875347 OBDC_BedienSG_hi_Req: 8 Gateway
 SG_ OBDC_BedienSG_hi_Req_Data : 0|64@1+ (1.0,0.0) [0.0|18446744073709551615] ""  BedienSG_hi

BO_ 2550006419 OBDC_BedienSG_hi_Resp: 8 BedienSG_hi
 SG_ OBDC_BedienSG_hi_Resp_Data : 0|64@1+ (1.0,0.0) [0.0|18446744073709551615] ""  Gateway,Gateway_PAG

BO_ 2549875386 OBDC_DDA_Req: 8 Gateway
 SG_ OBDC_DDA_Req_Data : 0|64@1+ (1.0,0.0) [0.0|18446744073709551615] ""  DDA

BO_ 2550006458 OBDC_DDA_Resp: 8 DDA
 SG_ OBDC_DDA_Resp_Data : 0|64@1+ (1.0,0.0) [0.0|18446744073709551615] ""  Gateway,Gateway_PAG

BO_ 2549940736 OBDC_Funktionaler_Req_All: 8 Gateway
 SG_ OBDC_Funktionaler_Req_All_Data : 0|64@1+ (1.0,0.0) [0.0|18446744073709551615] ""  BedienDisp_vo,BedienSG_hi,DDA,ZR_High,ZR_MIB_TOP_ab_Gen3,ZR_Standard

BO_ 2549875299 OBDC_Gurtmikro_Req: 8 Gateway
 SG_ OBDC_Gurtmikro_Req_Data : 0|64@1+ (1.0,0.0) [0.0|18446744073709551615] ""  GurtMikrofon

BO_ 2550006371 OBDC_Gurtmikro_Resp: 8 GurtMikrofon
 SG_ OBDC_Gurtmikro_Resp_Data : 0|64@1+ (1.0,0.0) [0.0|18446744073709551615] ""  Gateway

BO_ 2549875315 OBDC_Info_El_Req: 8 Gateway
 SG_ OBDC_Info_El_Req_Data : 0|64@1+ (1.0,0.0) [0.0|18446744073709551615] ""  ZR_High,ZR_LIMU,ZR_MIB_TOP_ab_Gen3,ZR_Standard

BO_ 2550006387 OBDC_Info_El_Resp: 8 ZR_High
 SG_ OBDC_Info_El_Resp_Data : 0|64@1+ (1.0,0.0) [0.0|18446744073709551615] ""  Gateway,Gateway_PAG

BO_ 2549875312 OBDC_Laufwerke_Req: 8 Gateway
 SG_ OBDC_Laufwerke_Req_Data : 0|64@1+ (1.0,0.0) [0.0|18446744073709551615] ""  ZR_High,ZR_MIB_TOP_ab_Gen3,ZR_Standard

BO_ 2550006384 OBDC_Laufwerke_Resp: 8 ZR_High
 SG_ OBDC_Laufwerke_Resp_Data : 0|64@1+ (1.0,0.0) [0.0|18446744073709551615] ""  Gateway,Gateway_PAG

BO_ 2549875370 OBDC_SCC1_Req: 8 Gateway
 SG_ OBDC_SCC1_Req_Data : 0|64@1+ (1.0,0.0) [0.0|18446744073709551615] ""  ZR_High,ZR_MIB_TOP_ab_Gen3

BO_ 2550006442 OBDC_SCC1_Resp: 8 ZR_High
 SG_ OBDC_SCC1_Resp_Data : 0|64@1+ (1.0,0.0) [0.0|18446744073709551615] ""  Gateway,Gateway_PAG

BO_ 2549875371 OBDC_SCC2_Req: 8 Gateway
 SG_ OBDC_SCC2_Req_Data : 0|64@1+ (1.0,0.0) [0.0|18446744073709551615] ""  ZR_High,ZR_MIB_TOP_ab_Gen3

BO_ 2550006443 OBDC_SCC2_Resp: 8 ZR_High
 SG_ OBDC_SCC2_Resp_Data : 0|64@1+ (1.0,0.0) [0.0|18446744073709551615] ""  Gateway,Gateway_PAG

BO_ 2549875367 OBDC_SDC1_Req: 8 Gateway
 SG_ OBDC_SDC1_Req_Data : 0|64@1+ (1,0) [0|18446744073709551615] "Unit_None"  ZR_High,ZR_MIB_TOP_ab_Gen3

BO_ 2550006439 OBDC_SDC1_Resp: 8 ZR_High
 SG_ OBDC_SDC1_Resp_Data : 0|64@1+ (1,0) [0|18446744073709551615] "Unit_None"  Gateway,Gateway_PAG

BO_ 2549875368 OBDC_SDC2_Req: 8 Gateway
 SG_ OBDC_SDC2_Req_Data : 0|64@1+ (1,0) [0|18446744073709551615] "Unit_None"  ZR_High,ZR_MIB_TOP_ab_Gen3

BO_ 2550006440 OBDC_SDC2_Resp: 8 ZR_High
 SG_ OBDC_SDC2_Resp_Data : 0|64@1+ (1,0) [0|18446744073709551615] "Unit_None"  Gateway,Gateway_PAG

BO_ 2549875309 OBDC_TV_Tuner_Req: 8 Gateway
 SG_ OBDC_TV_Tuner_Req_Data : 0|64@1+ (1.0,0.0) [0.0|18446744073709551615] ""  ZR_High,ZR_MIB_TOP_ab_Gen3,ZR_Standard

BO_ 2550006381 OBDC_TV_Tuner_Resp: 8 ZR_High
 SG_ OBDC_TV_Tuner_Resp_Data : 0|64@1+ (1.0,0.0) [0.0|18446744073709551615] ""  Gateway,Gateway_PAG

BO_ 2549875365 OBDC_WLC1_Req: 8 Gateway
 SG_ OBDC_WLC1_Req_Data : 0|64@1+ (1,0) [0|18446744073709551615] "Unit_None"  ZR_High,ZR_MIB_TOP_ab_Gen3

BO_ 2550006437 OBDC_WLC1_Resp: 8 ZR_High
 SG_ OBDC_WLC1_Resp_Data : 0|64@1+ (1,0) [0|18446744073709551615] "Unit_None"  Gateway,Gateway_PAG

BO_ 2549875366 OBDC_WLC2_Req: 8 Gateway
 SG_ OBDC_WLC2_Req_Data : 0|64@1+ (1,0) [0|18446744073709551615] "Unit_None"  ZR_High,ZR_MIB_TOP_ab_Gen3

BO_ 2550006438 OBDC_WLC2_Resp: 8 ZR_High
 SG_ OBDC_WLC2_Resp_Data : 0|64@1+ (1,0) [0|18446744073709551615] "Unit_None"  Gateway,Gateway_PAG

BO_ 2589283656 ORU_01: 8 Gateway
 SG_ ORU_Warnung : 58|2@1+ (1.0,0.0) [0.0|3] ""  Vector__XXX
 SG_ ORU_Status : 61|3@1+ (1.0,0.0) [0.0|7] ""  ZR_High,ZR_LIMU,ZR_MIB_TOP_ab_Gen3

BO_TX_BU_ 283 :Gateway,Gateway_PAG;
BO_TX_BU_ 2589283475 :Gateway,Gateway_PAG;
BO_TX_BU_ 706 :Gateway,Gateway_PAG;
BO_TX_BU_ 1601 :Gateway,Gateway_PAG;
BO_TX_BU_ 305 :Gateway,Gateway_PAG;
BO_TX_BU_ 1376 :Gateway,Gateway_PAG;
BO_TX_BU_ 1155 :Gateway,Gateway_PAG;
BO_TX_BU_ 1156 :ZR_High,ZR_LIMU,ZR_MIB_TOP_ab_Gen3,ZR_Standard;
BO_TX_BU_ 1157 :ZR_High,ZR_LIMU,ZR_MIB_TOP_ab_Gen3,ZR_Standard;
BO_TX_BU_ 2527679512 :ZR_High,ZR_LIMU,ZR_MIB_TOP_ab_Gen3,ZR_Standard;
BO_TX_BU_ 2527679665 :ZR_High,ZR_LIMU,ZR_MIB_TOP_ab_Gen3;
BO_TX_BU_ 1158 :ZR_High,ZR_LIMU,ZR_MIB_TOP_ab_Gen3,ZR_Standard;
BO_TX_BU_ 2589283496 :ZR_High,ZR_LIMU,ZR_MIB_TOP_ab_Gen3,ZR_Standard;
BO_TX_BU_ 2527679647 :Gateway,Gateway_PAG;
BO_TX_BU_ 2527679645 :Gateway,Gateway_PAG;
BO_TX_BU_ 1696 :Gateway,Gateway_PAG;
BO_TX_BU_ 2600468496 :Gateway,Gateway_PAG;
BO_TX_BU_ 2600468595 :ZR_High,ZR_LIMU,ZR_MIB_TOP_ab_Gen3,ZR_Standard;
BO_TX_BU_ 1377 :Gateway,Gateway_PAG;
BO_TX_BU_ 1635 :Gateway,Gateway_PAG;
BO_TX_BU_ 913 :Gateway,Gateway_PAG;
BO_TX_BU_ 2549875311 :Gateway,Gateway_PAG;
BO_TX_BU_ 2550006383 :ZR_High,ZR_MIB_TOP_ab_Gen3,ZR_Standard;
BO_TX_BU_ 2549875342 :Gateway,Gateway_PAG;
BO_TX_BU_ 2549875347 :Gateway,Gateway_PAG;
BO_TX_BU_ 2549875386 :Gateway,Gateway_PAG;
BO_TX_BU_ 2549940736 :Gateway,Gateway_PAG;
BO_TX_BU_ 2549875315 :Gateway,Gateway_PAG;
BO_TX_BU_ 2550006387 :ZR_High,ZR_LIMU,ZR_MIB_TOP_ab_Gen3,ZR_Standard;
BO_TX_BU_ 2549875312 :Gateway,Gateway_PAG;
BO_TX_BU_ 2550006384 :ZR_High,ZR_MIB_TOP_ab_Gen3,ZR_Standard;
BO_TX_BU_ 2549875370 :Gateway,Gateway_PAG;
BO_TX_BU_ 2550006442 :ZR_High,ZR_MIB_TOP_ab_Gen3;
BO_TX_BU_ 2549875371 :Gateway,Gateway_PAG;
BO_TX_BU_ 2550006443 :ZR_High,ZR_MIB_TOP_ab_Gen3;
BO_TX_BU_ 2549875367 :Gateway,Gateway_PAG;
BO_TX_BU_ 2550006439 :ZR_High,ZR_MIB_TOP_ab_Gen3;
BO_TX_BU_ 2549875368 :Gateway,Gateway_PAG;
BO_TX_BU_ 2550006440 :ZR_High,ZR_MIB_TOP_ab_Gen3;
BO_TX_BU_ 2549875309 :Gateway,Gateway_PAG;
BO_TX_BU_ 2550006381 :ZR_High,ZR_MIB_TOP_ab_Gen3,ZR_Standard;
BO_TX_BU_ 2549875365 :Gateway,Gateway_PAG;
BO_TX_BU_ 2550006437 :ZR_High,ZR_MIB_TOP_ab_Gen3;
BO_TX_BU_ 2549875366 :Gateway,Gateway_PAG;
BO_TX_BU_ 2550006438 :ZR_High,ZR_MIB_TOP_ab_Gen3;
BO_TX_BU_ 2589283656 :Gateway,Gateway_PAG;
CM_ BO_ 1601 "ab MQB mit CRC-8";
CM_ BO_ 1696 "MLBevo ohne KD-Bit";
CM_ BO_ 1635 "DLC=8 ab D4 gültig";
CM_ BO_ 2549940736 "VDC funktionaler Request auf CANHS";

CM_ SG_ 283 MO_AIAD_MaxLeistung "Maximal zulässige Leistung, die das PDCC einzustellen hat.";
CM_ SG_ 283 MO_EBoost_verf_praed "Zeigt an, ob für eine im Projekt definierte Zeit (max. 10s) E-Boost in Höhe von EM1_maxPred_Moment verfügbar sein wird.

0 - Init_oder_nicht_verfügbar
1 - EBoost_kurzzeit_verfügbar (~3Sek.)
2 - EBoost_langzeit_verfügbar (~10Sek)";
CM_ SG_ 283 MO_eLaunch_verf "Zeigt an, ob aus Antriebssicht E-Launch verfügbar ist.";
CM_ SG_ 283 MO_Fahrbereitschaft "Das Signal MO_Fahrbereitschaft zeigt in mehreren Stufen an, ob der Motor in einem anfahrbereiten Zustand ist.";
CM_ SG_ 283 MO_Freilauf_Info "Freilauf Informationssignal vom Motorsteuergerät zum Getriebesteuergerät. Das Motorsteuergerät kann über dieses Signal den Freilauf freigeben, verhindern bzw. explizit anfordern.";
CM_ SG_ 283 MO_Freilauf_Status "Freilauf-Status-Signal vom Frailauf-Master an aktive Freilauf-Teilnehmer. In diesem Signal zeigt der Freilauf-Master an, welchen aktuellen Status die Freilauf-Betriebsstrategie hat.";
CM_ SG_ 283 MO_Heckspoiler_Anf "Anforderung den Heckspoiler zur Ladeluft- bzw. Motorraumkühlung auszufahren.";
CM_ SG_ 283 MO_Krit_Heckobjekt "Beschreibt die Kritikalität des hinter einem in der Spur fahrenden Fahrzeuges";
CM_ SG_ 283 MO_NGS_Gangpos "Gang- bzw. Neutralinformation des erweiterten Neutralgangsensors. Bedingt durch den eingeschränkten Erfassungssbereich des Sensors sind die Ganginformationen als eingelegt bzw. fast eingelegt/vorausgewählt zu interpretieren (nur Handschalter)";
CM_ SG_ 283 MO_Parken_WFS_Status "Gesammelte Rückmeldung des Limitierungsstatus aller EM in einem vom ZFAS angeforderten Parkvorgang.";
CM_ SG_ 283 MO_Positionierung_aktiv "Zeigt an, dass die Motorpositionierung mit Hilfe des Riemenstartergenerator momentan aktiv ist.";
CM_ SG_ 283 MO_Rennstart_verf "Zeigt an, ob aus Antriebssicht ein Rennstart verfügbar ist.";
CM_ SG_ 283 MO_Status_Katheizen "Status des Katheizen.

0 = Katheizen nicht aktiv
1 = Katheizen aktiv";
CM_ SG_ 283 MO_Status_MIN_Wunschdrehzahl "In 2.0 TFSI Motorprojekten EA888 Gen3 und EA888 EVO4 im MLBevo (AU536 und AU49x, in allen anderen Projekten ist das Signal nicht zu implementieren) wird das Bus Signal MO_MIN_Wunschdrehzahl verwendet, um durch eine damit angepasste Gangwahl des Getriebes ";

CM_ SG_ 2589283475 SCR_Einheit "Länderspezifische Einheit der Restreichweite (km oder mi)";
CM_ SG_ 2589283475 SCR_Fuellstand "Füllstand des SCR-Tanks in % bezogen auf das tatsächliche Tankvolumen";
CM_ SG_ 2589283475 SCR_Nachfuellmenge_Einheit "Länderspezifische Einheit der min/max Nachfüllmenge (Liter/Gallone US/Gallone UK)";
CM_ SG_ 2589283475 SCR_Nachfuellmenge_max "Maximales Volumen, mit dem der SCR Tank nachbefüllt werden kann.";
CM_ SG_ 2589283475 SCR_Nachfuellmenge_min "Minimal erforderliche Nachfüllmenge, damit eine Betankung erkannt wird";
CM_ SG_ 2589283475 SCR_Restreichweite "Verbleibende Restreichweite mit aktuellem SCR-Tankinhalt (ohne Dimension)";
CM_ SG_ 2589283475 SCR_Retriggersignal "Trigger zur Erneuerung der SCR Kombibotschaft";
CM_ SG_ 2589283475 SCR_Tankvolumen "Volumen des verbauten SCR Tanks. Dimension abhängig von Signal SCR_Nachfüllmenge_Einheit.";
CM_ SG_ 2589283475 SCR_Zustand "Zustand des SCR Systems, der an das Kombi/MMI übermittelt wird";

CM_ SG_ 706 MO_ADR_Status "Status der Arbeitsdrehzahlregelung";
CM_ SG_ 706 MO_AGA_Sound_Texte "Textausgabe des aktuellen Sound-Zustandes der Abgasklappensteuerung";
CM_ SG_ 706 MO_Anz_Kuehlerluefter "Signal bei aktivem Kühlerlüfternachlauf (Motor aus) im Allgemeinen für die Anzeige im Kombi-Instument zur Information des Kunden über diesen Lüfterlauf";
CM_ SG_ 706 MO_Anzeige_FMAus_Text "Fehlerstatus des FMAus-Systems (z.B. Fehler im Zusatzspeicher)";
CM_ SG_ 706 MO_Anzeige_StSt_Symbol "Steuert die Anzeige der StSt-Symbolik im Kombi";
CM_ SG_ 706 MO_Anzeige_StSt_Text "Steuert die Anzeige der StSt-Texte im Kombi";
CM_ SG_ 706 MO_Avus_Motorschutz "Warntexten zum Kombi für den Fall des Avus-Notlauf. Priowarnung, kann parallel mit anderen Warnungen 
im Mitteldisplay angezeigt werden.";
CM_ SG_ 706 MO_Fehler_MSpG "Wenn das Motorraumspülgebläse defekt ist, oder die Motorraumtemperatur zu hoch sendet die DME Info ans Kombiinstrument. Dieses gibt Textmeldung aus. Und blinkende Heissleuchte.";
CM_ SG_ 706 MO_im_Leerlauf "Motor ist im Leerlauf";
CM_ SG_ 706 MO_Oel_Temp_Radsatz_Warn "Öltemperatur im Getriebe Radsatz Warnung";
CM_ SG_ 706 MO_OelMessung_Dauer "Ölstandsmessung deaktiv/ Restdauer der Messung";
CM_ SG_ 706 MO_Red_Fahrleistung "Signal zur Anzeige von den verschiedenen Leistungsreduzierungsstufen.";
CM_ SG_ 706 MO_Rekuperationsstufe "In Projekten mit variablen oder anwählbaren Rekuperationsstufen soll dem Fahrer die aktuell ausgewählte Stufe über ein Icon in den Anzeigeinstrumenten visualisiert werden können. Dies dient der Nachvollziehbarkeit für den Kunden in Bezug auf eine zukünfti";
CM_ SG_ 706 PEA_Texte "Status der Funktion PEA";
CM_ SG_ 706 TSK_Einheit_vMax_FahrerInfo "Einheit zu TSK_vMax_FahrerInfo. Das MSG spiegelt hier KBI_MFA_v_Einheit und stellt den Anzeigewert in dieser Einheit zur Verfügung (kein zyklisches Mux)";
CM_ SG_ 706 TSK_Status_vMax_FahrerInfo "Status der TSK_vMax_FahrerInfo zur Steuerung von PopUps, Fahrzeugstatus und ggf. einer LED. Bei Wert 0 in TSK_vMax_Fahrerinfo soll auf eine unspezifische Begrenzung hingewiesen werden (z.B. wegen Momentenbegrenzung), bei allen anderen Werten soll dieser a";
CM_ SG_ 706 TSK_Ueberstimmt_vMax_FahrerInfo "Information ueber den Zustand wann die vMax-Limitierung vom Fahrer ueberstimmt wird.";
CM_ SG_ 706 TSK_vMax_FahrerInfo "anzuzeigende Begrenzungsgeschwindigkeit bei aktiver HGB";
CM_ SG_ 706 WIV_Enable_Oeldr_Motor "Schaltet die interne Öldruckauswertung im Kombiinstrument ab und aktiviert die Auswertung des Bits 'WIV_Oeldr_Warn_Motor'";

CM_ SG_ 2589283599 MO_Eboost_LB_active "LB eboost activation status";
CM_ SG_ 2589283599 MO_Eboost_LB_available "LB eboost is available in the actual DM/PS";
CM_ SG_ 2589283599 MO_Eboost_LB_driveraction "LB eboost driver advice";
CM_ SG_ 2589283599 MO_Eboost_LB_failure "LB eboost functionality failure";
CM_ SG_ 2589283599 MO_Eboost_LB_LVLavailable "LB eboost levels available";
CM_ SG_ 2589283599 MO_Eboost_LB_LVLselected "LB eboost level selected";
CM_ SG_ 2589283599 MO_Eboost_LB_possible "LB eboost is avaialbe in the actual DM/PS and possible based on system status";
CM_ SG_ 2589283599 MO_Kilometerstand_Wakeup "Odometer value sent at wake-up";
CM_ SG_ 2589283599 MO_Nachlaufzeit_Kuehlerluefter_2 "Nachlaufzeit Kühlerlüfter 2 MSG für Verwendung im TME SG";
CM_ SG_ 2589283599 MO_Status_KL "Diagnose_nicht_durchgefuehrt
Lüfter_iO
Diagnose_laeuft
Lüfter_iO_Diagnose_laeuft
Lüfter_Notlauf
Lüfter_Fehler";

CM_ SG_ 1601 MO_Ansaugsystem "Art des Ansaugsystems des Verbrennungsmotors";
CM_ SG_ 1601 MO_Anzahl_Zyl "Zylinderzahl des Verbrennungsmotors";
CM_ SG_ 1601 MO_Anzeige_StSt_gueltig "Zeigt die Gültigkeit der neuen StSt-Anzeigesignale an, MO_Anzeige_StSt_Text und  MO_Anzeige_Symbol. Mo_Text_Motorstart 1..5 sind zu ignorieren.";
CM_ SG_ 1601 MO_Code "Motorcodierinformation Version 16 (Details siehe Anhang)";
CM_ SG_ 1601 MO_DPF_verbaut "Verbauinformation Diesel-Partikel-Filter
";
CM_ SG_ 1601 MO_Faktor_Momente_02 "Dieses Signal schaltet den Wertebereich aller Momente vom Motor, Getriebe, TSK, Bremse ... um! Die Momente besitzen somit einen variablen Wertebereich, weil sich durch den Faktor die Momente sowohl in Auflösung als auch Maximalwerten ändert.

0x0 nicht ";
CM_ SG_ 1601 MO_Getriebe_Code "Getriebecodierung des Motors";
CM_ SG_ 1601 MO_Hubraum "Hubraum des Verbrennungsmotors";
CM_ SG_ 1601 MO_Hybridfahrzeug "Anhand dieses Signals plausibilisiert die Lenkhilfe das Bit Fahrbereitschaft.

Im Projekt Cayenne PHEV (und ggf. auch VW526 PHEV) ist aus Gründen der Abwärtskompatibilität der Wert '2' zu senden.";
CM_ SG_ 1601 MO_Kraftstoffart "Primärkraftstoff zum Antrieb des Fahrzeugs";
CM_ SG_ 1601 MO_Leistung "Nennleistung des Verbrennungsmotors

Im reinen E-Fahrzeug (BEV): Ausgabe der elektrischen Systemleistung";
CM_ SG_ 1601 MO_OBD_Typ "Abgastyp OBD
Hinweis: In Fahrzeugen mit dem Zielmarkt China und einer Zertifizierung ab China 6 muss auf dem Signal 'MO_OBD_Typ' der Wert 'US_OBD' gesendet werden.";
CM_ SG_ 1601 MO_StartStopp_Codiert "Funktion StartStopp im aktuellen Klemmenzyklus verbaut";
CM_ SG_ 1601 Motor_Code_01_CRC "Für MLB:
'Berechnung siehe Lastenheft 'Kommunikationsabsicherung für FlexRay und CAN''

Ab MQB und MLBevo:
'Berechnung siehe Lastenheft 'End-to-End Kommunikationsabsicherung''

Endwerte siehe Begleitdokument 'S-PDU Kennungsfolgen'";
CM_ SG_ 1601 TSK_Codierung "Information über den plausibilisierten Codierungszustand des Triebstrangskoordinators auf ACC oder GRA.";

CM_ SG_ 305 Ladezustand_02 "Aktueller relativer Ladezustand der HV-Batterie
";
CM_ SG_ 305 MO_ePerformance "Zeigt die elektrische Leistungreserve bei BEV und PHEV Projekten an.
Bei Init und Fehler soll keine Anzeige erfolgen. ";
CM_ SG_ 305 MO_ePowermeter "Anzeige ePowermeter (Fahrreserve elektrisch bis Start Verbrennungsmotor (Verbrenner startet bei 100%))";
CM_ SG_ 305 MO_Powermeter "Anzeigewerte im Kombi
0       = Unteres Ende Bremsen/grau;
340   = Unteres Ende CHARGE;
1020 = READY;
1870 = Oberes Ende EFFICIENCY;
3400 = 100%;
4080 = MAX;";
CM_ SG_ 305 MO_Powermeter_Elm "Die Prozentwerte ergeben sich aus dem momentanen Moment der E-Maschine bezogen auf das im aktuellen Arbeitspunkt maximal mögliche Moment der E-Maschine (generatorisch = negativ / motorisch = positiv )";
CM_ SG_ 305 MO_Powermeter_Elm_02 "relatives Moment / relative Leistung der elektrischen Maschine";
CM_ SG_ 305 MO_Zust_Antrieb "Signalisiert die Zuordnung der Antriebsverbräuche zu den Antriebsmaschinen für die Restreichweitenberechnung, nicht gleichbedeutend mit Motorlauf EM oder VM bzw. Brennstoffzelle";
CM_ SG_ 305 MO_Zust_Betriebsstrategie "Signalisiert den aktuellen Zustand der Betriebsstrategie";

CM_ SG_ 1376 MO_Gesamtst_Spgfreiheit "0x0 (00)   Funktion Init (ohne Funktion)
0x1 (01)   HV-System spannungsfrei 
0x2 (10)   HV-System nicht spannungsfrei 
0x3 (11)   Fehler";
CM_ SG_ 1376 MO_HV_Spannungsfreiheit "Anzeige der Spannungsfreiheit des HV-Systems im Kombi (Service und Produktion). 

Abhängigkeiten zu anderen Signalen:
BMS_Status_Spannungsfreiheit und EM_Status_Spannungsfreiheit und BMS_Status_ServiceDisconnect";
CM_ SG_ 1376 MO_HYB_Status_Betriebsstrategie "Zustände der Betriebsstrategie im MSG";
CM_ SG_ 1376 MO_Reku_Leistung "Durchschnittliche Rekuperationsleistung zur Umrechnung im Kombi";
CM_ SG_ 1376 MO_Tankbereitschaft_Status "Meldung der Tankbereitschaft";
CM_ SG_ 1376 Motor_Hybrid_04_BZ "4bit-Botschaftszaehler, wird in jeder Sendebotschaft inkrementiert";
CM_ SG_ 1376 Motor_Hybrid_04_CRC "'Berechnung siehe Lastenheft 'End-to-End Kommunikationsabsicherung'

Endwerte siehe Begleitdokument 'S-PDU Kennungsfolgen'";

CM_ SG_ 1155 MO_Powermeter_Charge_Grenze "Zeigt eine Einschränkung der Rekuperationsleistung an
";
CM_ SG_ 1155 Mo_Powermeter_Grenze "Anzeige des verfügbaren Powermeterstands im Kombi. Bei EV Unterscheidung zwischen Boost- und Dauerbereich, bei HEV für die Zustartgrenze nutzber";
CM_ SG_ 1155 MO_Powermeter_Grenze_strategisch "Zeigt eine strategische Leistungsbeschränkung des Antriebs, 
zum Beispiel kein Boost im Efficiency Modus";
CM_ SG_ 1155 MO_Powermeter_Inszenierung_aktiv "Mit Hilfe des Signals kann eine Dynamikabfahrt für den Kunden inszeniert werden. Die Inszenierung wird im Powermeter des Kombi-Instruments verortet.";
CM_ SG_ 1155 MO_Powermeter_obere_E_Grenze "Zeigt die obere Grenze für das elektrische Fahren an";
CM_ SG_ 1155 MO_Powermeter_untere_E_Grenze "Zeigt die untere Grenze für das elektrische Fahren an";
CM_ SG_ 1155 MO_Text_Aktivierung_Antrieb "Fahrerinformation zur Antriebsstrangaktivierung.";

CM_ SG_ 1156 ND_GDOP "geometric dilution of precision (Gesamtgenauigkeit, 3D und Zeit) 
";
CM_ SG_ 1156 ND_HDOP "horizontal dilution of precision (Horizontalrichtung, 2D)
";
CM_ SG_ 1156 ND_Heading "Fahrtrichtung";
CM_ SG_ 1156 ND_Init "Initialisierung";
CM_ SG_ 1156 ND_PDOP "positional dilution of precision (Positionsgenauigkeit, 3D) 
";
CM_ SG_ 1156 ND_TDOP "time dilution of precision (Zeitgenauigkeit)
";
CM_ SG_ 1156 ND_VDOP "vertical dilution of precision (Vertikalrichtung, 1D)
";

CM_ SG_ 1157 ND_SatInUse "Anzahl der zur Berechnung verwendeten Satelliten";
CM_ SG_ 1157 ND_SatInView "Anzahl der sichtbaren Satelliten";
CM_ SG_ 1157 ND_UTC "UTC-Zeit, verstrichene Sekunden seit 01.01.1970 00:00
0xFFFFFFFE = Init
0xFFFFFFFF = Fehler bei Berechnung der UTC-Time";
CM_ SG_ 1157 NP_Altitude "Hoehe ueber NN
0xFFF = Fehler bei der Berechnung der Höhe über NN";
CM_ SG_ 1157 POS_Guete_horizontal "Horizontale Genauigkeit der Position in der Botschaft NavPos_02_MapMatched (Signale
POS_LatDegree, POS_LongDegree)

Abhängig vom Signal
POS_Guete_horizontal_verfuegbar";
CM_ SG_ 1157 POS_Guete_horizontal_verfuegbar "Bei gesetztem Bit wird das Signal POS_Guete_horizontal befüllt und ist verfügbar.";

CM_ SG_ 2527679512 ND_Fuelstation_detected "Signal gibt an ob eine Tankstelle erkannt wurde";
CM_ SG_ 2527679512 ND_NrSameMeasure "GPS Anzahl der gleichen Messungen";
CM_ SG_ 2527679512 ND_RecDelay "Für MLBevo:
Zeit in ms zwischen zwei Interruptauslösungen des GPS Receiver.

Für MLBevoGen2:
Zeit in ms zwischen UTC-Sekunde und Messzeitpunkt des GPS Receiver.";
CM_ SG_ 2527679512 ND_RouteType "Routentyp.";
CM_ SG_ 2527679512 ND_SendDelay "Zeit in ms zwischen Interruptauslösung GPS Receiver (Beginn der Messung) und Senden auf den CAN Bus.";
CM_ SG_ 2527679512 ND_TimeOffset "Offset zu ND_TimeToDestination.";
CM_ SG_ 2527679512 ND_TimeToDestination "Zeit in min bis zum Erreichen des Ziel. Wird ausgegeben bei aktiver Routenführung oder bei gelernter Route (MPR).";
CM_ SG_ 2527679512 ND_Timezone_DaylightSavingOffset "Offest der Sommerzeit/Winterzeit
 
0 = kein Offset ; 
1 = 0,5h;  
2 = 1h";
CM_ SG_ 2527679512 ND_Timezone_Offset "Aktuelle Zeitzonen-Offset des Fahrzeugs.
Vorzeichen und Gültigkeit beachten";
CM_ SG_ 2527679512 ND_Timezone_SignBit "Vorzeichen des Zeitzonenoffsets.";
CM_ SG_ 2527679512 ND_Timezone_Validity "Gültigkeit des Zeitzonensignals.";
CM_ SG_ 2527679512 ND_Velocity "GPS Geschwindigkeit";

CM_ SG_ 2527679665 ND_Avrg_Speed_RangeData "Durchschnittsgeschwindigkeit der aktuell befahrenen Strassenkante (Ist-Position Fahrzeug) fuer die Berechnung der routenbasierenden Reichweite.";

CM_ SG_ 1158 NP_LatDegree "Latitude (Nord-Süd Wert)";
CM_ SG_ 1158 NP_LatDirection "Hemisphäre Nord/Süd";
CM_ SG_ 1158 NP_LongDegree "Longitude (Ost-West Wert)";
CM_ SG_ 1158 NP_LongDirection "Hemisphäre Ost/West";
CM_ SG_ 1158 NP_Sat "Nummer der verwendeten Sateliten beim letzten Fix";

CM_ SG_ 2589283496 POS_Heading "Heading of current position
MUX(1)";
CM_ SG_ 2589283496 POS_Heading_Trust "Vertrauenswert Heading 
MUX(1) ";
CM_ SG_ 2589283496 POS_Last_GPS_Sync "Letztes bekannte GPS Sync in [s]
MUX(1)";
CM_ SG_ 2589283496 POS_LatDegree "latitude - position data of navigation
MUX(0)";
CM_ SG_ 2589283496 POS_LatDirection "latitude direction nav position
MUX(0)";
CM_ SG_ 2589283496 POS_LongDegree "long - position data of navigation
MUX(0)";
CM_ SG_ 2589283496 POS_LongDirection "longitude direction nav position
MUX(0)";
CM_ SG_ 2589283496 POS_MUX "Multiplex-Signal zum schalten des Signals der Positionen von der Navigation.
MUX(0/1)";
CM_ SG_ 2589283496 POS_ODD_EVEN "Synchronisation der MUX Pos Signale
MUX(0/1)";
CM_ SG_ 2589283496 POS_PosStati "Aktueller Status der Navgation:
MUX(0)
0   init
1   no nav available (ready_4_nav)
2   no map available (sd_removed, not_enabled)
3   nav booting
4   nav error
5   nav calibrating
6   nav no gps resync since 1h
7   nav offroad  parkgarage ramp of";
CM_ SG_ 2589283496 POS_UTC_REF "Zeitstempel der Nav
MUX(1)

UTC-Zeit, verstrichene Sekunden seit 01.01.1970 00:00
0xFFFFFFFE = Init
0xFFFFFFFF = Fehler bei Berechnung der UTC-Time

Signal wird nur bei aktiver Navigation-Funktion zyklisch gesendet.";

CM_ SG_ 2527679647 NFC_aktiv "NFC-Gerät erkannt";
CM_ SG_ 2527679647 NFC_ESM_aktivieren "Energiesparmodus aktivieren, da z.B. Batterie kritisch";
CM_ SG_ 2527679647 NFC_Front_Entr_Authorisiert "Erkennung / Authorisierung NFC-Handy Front";
CM_ SG_ 2527679647 NFC_Front_Verr_Authorisiert "Erkennung / Authorisierung NFC-Handy Front";
CM_ SG_ 2527679647 NFC_FT_Entriegelung_Authorisiert "Erkennung / Authorisierung NFC-Handy FT";
CM_ SG_ 2527679647 NFC_FT_Verriegelung_Authorisiert "Authorisierung Verriegelungssensor NFC-Handy FT";
CM_ SG_ 2527679647 NFC_HD_Entriegelung_Authorisiert "Erkennung / Authorisierung NFC-Handy Heck";
CM_ SG_ 2527679647 NFC_HD_Verriegelung_Authorisiert "Autorisierung der Schließanforderung über NFC-Handy";
CM_ SG_ 2527679647 NFC_Laden_unterbrechen "Kommunikation zur Phonebox, das Laden zu unterbrechen";
CM_ SG_ 2527679647 Stellgliedtest_NFC "Applikationssignal um NFC Stellgliedtest abzubilden";
CM_ SG_ 2527679647 ZV_auf_NFC "ZV Schliessstelle";
CM_ SG_ 2527679647 ZV_zu_NFC "ZV Schliessstelle";

CM_ SG_ 2527679645 NFC_MiKo_ESM_aktiv "Energiesparmodus ist aktiv, z.B. nach 72h Fahrzeugstillstand";
CM_ SG_ 2527679645 NFC_MiKo_Fehler "Das Steuergeraet hat einen Fehler und ist nicht komplett einsatzfaehig.";
CM_ SG_ 2527679645 NFC_MiKo_Laden_unterbrechen "Anforderung seitens Mittelkonsolen-STG das Laden in der Phonebox zu unterbrechen";
CM_ SG_ 2527679645 NFC_MiKo_NFC_Device_gekoppelt "Ein NFC-Device ist im Empfangsbereich und der NFC-Reader hat eine aktive Verbindung aufgebaut.";

CM_ SG_ 1696 NV_Akt_Status_MMI "Zustand des Nightvison Systems im MMI: Warnalgo & NV-Reiter Ein/Aus

";
CM_ SG_ 1696 NV_aktiv "Nightvision aktiviert (liefert Bild)";
CM_ SG_ 1696 NV_Akustik_deaktiviert_Icon "Ansteuerungssignal für das  Akustik-deaktiviert-Icon";
CM_ SG_ 1696 NV_Anf_Prefill "Anforderung an ESP, dass die Prefill-Funktion aktiviert werden soll.";
CM_ SG_ 1696 NV_AnforderungBildaufschaltung "Automatische Bildaufschaltung im Warnfall";
CM_ SG_ 1696 NV_FAS_Fkt_Status "Signal für FAS Profile-Master";
CM_ SG_ 1696 NV_FGM_deaktiviert_Icon "Ansteuerungssignal für das  Fussgängermarkierung-deaktiviert-Icon";
CM_ SG_ 1696 NV_Gong "Das Signal löst einen Gong des NightVision-Systems im Kombidisplay aus";
CM_ SG_ 1696 NV_HBA_Parameter "Anforderung an ESP, welcher HBA-Parametersatz verwendet werden soll. Die Festlegung der Empfindlichkeitsschwellen der verschiedenen Parametersätze erfolgt mit der Applikation des Gesamtsystems ESP/ACC bzw. des HBA.
Nur Audi B8: Umsetzung der Anforderung ";
CM_ SG_ 1696 NV_Hinweise "Das Signal dient dazu Hinweistexte in das NightVision Bild im Kombiinstrument einzublenden.Die Anzeigedauer der Hinweistexte ist Signalgesteuert. D.h., sie werden angezeigt bis das CAN-Signal s_NV_Texte seinen Wert ändert.";
CM_ SG_ 1696 NV_LED_Leiste "Ansteuerung_LED_Warnleiste";
CM_ SG_ 1696 NV_Markierungslicht_links "Das Signal steuert die Aktivierung des Markierungslicht links bei Fußgängerwarnung";
CM_ SG_ 1696 NV_Markierungslicht_rechts "Das Signal steuert die Aktivierung des Markierungslicht rechts bei Fußgängerwarnung";
CM_ SG_ 1696 NV_Piktogramm_aktiv "Signal sagt, dass das Piktogramm im NightVision-Reiter geändert werden soll";
CM_ SG_ 1696 NV_PreSense_Modus_System "Signal zur Realisierung der BAP-Kommunikation für PreSense";
CM_ SG_ 1696 NV_PreSense_Modus_Warnung "Signal zur Realisierung der BAP-Kommunikation für PreSense";
CM_ SG_ 1696 NV_PreSense_Status "Signal zur Realisierung der BAP-Kommunikation für PreSense";
CM_ SG_ 1696 NV_Symbol "Wenn das NV-System einen Fußgänger findet, fordert es mit dem Signal das HUD auf, ein Symbol zu zeigen";
CM_ SG_ 1696 NV_Symbol_Tierwarnung "Signal zur Anforderung einer Symbolanzeige für Tierwarnung.";
CM_ SG_ 1696 NV_Texte "Angeforderte Textmeldung";

CM_ SG_ 2600468622 NM_BedienDisp_vo_CAB "CAB = Clusteraktivbits";
CM_ SG_ 2600468622 NM_BedienDisp_vo_Car_Wakeup "Car Wakeup (Gateway wertet aus)";
CM_ SG_ 2600468622 NM_BedienDisp_vo_CBV_AWB "Das Signal ist zu setzen, wenn das SG aktiv den Bus geweckt hat";
CM_ SG_ 2600468622 NM_BedienDisp_vo_CBV_CRI "Das Signal ist dauerhaft gesetzt, wenn das NM-Layout dem neuen NM-Layout für Teilnetzbetrieb entspricht";
CM_ SG_ 2600468622 NM_BedienDisp_vo_NM_aktiv_Diag "Diagnose befindet sich nach VW80124 in einer NonDefaultDiagnostic-Session, z.B. ExtendedDiagnostic-Session";
CM_ SG_ 2600468622 NM_BedienDisp_vo_NM_aktiv_KL15 "Steuergerät hat KL15-EIN erkannt";
CM_ SG_ 2600468622 NM_BedienDisp_vo_NM_aktiv_Restwa "Anforderung Restwärme";
CM_ SG_ 2600468622 NM_BedienDisp_vo_NM_aktiv_Tmin "Mindestaktivzeit ist noch nicht abgelaufen (bei jedem Weckereignis wird die Mindestaktivzeit neu gestartet)";
CM_ SG_ 2600468622 NM_BedienDisp_vo_NM_State "1 = Zustand Repeat Message (<-- Bus-Sleep Mode)
2 = Zustand Repeat Message (<-- Prepare Bus-Sleep Mode)
4 = Zustand Normal Operation (<-- Repeat Message)
8 = Zustand Normal Operation (<-- Ready Sleep)";
CM_ SG_ 2600468622 NM_BedienDisp_vo_SNI "Source Node-Identifier (SNI) identifiziert den Sender der NM-Botschaft (Knotenadresse) eindeutig im Fahrzeug";
CM_ SG_ 2600468622 NM_BedienDisp_vo_UDS_CC "Funktionseinschränkung aufgrund aktivem UDS-Communication Control; siehe VW80124";

CM_ SG_ 2600468627 NM_BedienSG_hi_CAB "CAB = Clusteraktivbits";
CM_ SG_ 2600468627 NM_BedienSG_hi_Car_Wakeup "Car Wakeup (Gateway wertet aus)";
CM_ SG_ 2600468627 NM_BedienSG_hi_CBV_AWB "Das Signal ist zu setzen, wenn das SG aktiv den Bus geweckt hat";
CM_ SG_ 2600468627 NM_BedienSG_hi_CBV_CRI "Das Signal ist dauerhaft gesetzt, wenn das NM-Layout dem neuen NM-Layout für Teilnetzbetrieb entspricht";
CM_ SG_ 2600468627 NM_BedienSG_hi_NM_aktiv_Diagnose "Diagnose befindet sich nach VW80124 in einer NonDefaultDiagnostic-Session, z.B. ExtendedDiagnostic-Session";
CM_ SG_ 2600468627 NM_BedienSG_hi_NM_aktiv_KL15 "Steuergerät hat KL15-EIN erkannt";
CM_ SG_ 2600468627 NM_BedienSG_hi_NM_aktiv_Tmin "Mindestaktivzeit ist noch nicht abgelaufen (bei jedem Weckereignis wird die Mindestaktivzeit neu gestartet)";
CM_ SG_ 2600468627 NM_BedienSG_hi_NM_State "1 = Zustand Repeat Message (<-- Bus-Sleep Mode)
2 = Zustand Repeat Message (<-- Prepare Bus-Sleep Mode)
4 = Zustand Normal Operation (<-- Repeat Message)
8 = Zustand Normal Operation (<-- Ready Sleep)";
CM_ SG_ 2600468627 NM_BedienSG_hi_SNI "Source Node-Identifier (SNI) identifiziert den Sender der NM-Botschaft (Knotenadresse) eindeutig im Fahrzeug";
CM_ SG_ 2600468627 NM_BedienSG_hi_UDS_CC "Funktionseinschränkung aufgrund aktivem UDS-Communication Control; siehe VW80124";

CM_ SG_ 2600468666 NM_DDA_CAB "CAB = Clusteraktivbits";
CM_ SG_ 2600468666 NM_DDA_Car_Wakeup "Car Wakeup (Gateway wertet aus)";
CM_ SG_ 2600468666 NM_DDA_CBV_AWB "Das Signal ist zu setzen, wenn das SG aktiv den Bus geweckt hat";
CM_ SG_ 2600468666 NM_DDA_CBV_CRI "Das Signal ist dauerhaft gesetzt, wenn das NM-Layout dem neuen NM-Layout für Teilnetzbetrieb entspricht";
CM_ SG_ 2600468666 NM_DDA_NM_aktiv_BT_Verbindung "Für die Dauer einer aktiven Bluetooth-Verbindung wird der Bus wach gehalten";
CM_ SG_ 2600468666 NM_DDA_NM_aktiv_Diagnose "Diagnose befindet sich nach VW80124 in einer NonDefaultDiagnostic-Session, z.B. ExtendedDiagnostic-Session";
CM_ SG_ 2600468666 NM_DDA_NM_aktiv_KL15 "Steuergerät hat KL15-EIN erkannt";
CM_ SG_ 2600468666 NM_DDA_NM_aktiv_Tmin "Mindestaktivzeit ist noch nicht abgelaufen (bei jedem Weckereignis wird die Mindestaktivzeit neu gestartet)";
CM_ SG_ 2600468666 NM_DDA_NM_State "1 = Zustand Repeat Message (<-- Bus-Sleep Mode)
2 = Zustand Repeat Message (<-- Prepare Bus-Sleep Mode)
4 = Zustand Normal Operation (<-- Repeat Message)
8 = Zustand Normal Operation (<-- Ready Sleep)";
CM_ SG_ 2600468666 NM_DDA_SNI "Source Node-Identifier (SNI) identifiziert den Sender der NM-Botschaft (Knotenadresse) eindeutig im Fahrzeug";
CM_ SG_ 2600468666 NM_DDA_UDS_CC "Funktionseinschränkung aufgrund aktivem UDS-Communication Control; siehe VW80124";

CM_ SG_ 2600468496 NM_Gateway_CAB "CAB = Clusteraktivbits";
CM_ SG_ 2600468496 NM_Gateway_Car_Wakeup "Car Wakeup (Subbusmaster wertet aus)

MQB: 
-Diagnose- oder Komponentenschutzmaster-Funktion weckt den schlafenden Subbus (z.B. MOST)

E3_Volumen:
- Diagnose aktiv -aktive Diagnosekommunikation am OBD-Stecker

MQBw_Baseline:
- Diagnose aktiv -akt";
CM_ SG_ 2600468496 NM_Gateway_CBV_AWB "Das Signal ist zu setzen, wenn das SG aktiv den Bus geweckt hat
0 = Passiver_WakeUp = SG hat das Netzwerk nicht aktiv geweckt
1 = Akitiver_WakeUp = SG hat das Netzwerk aktiv geweckt";
CM_ SG_ 2600468496 NM_Gateway_CBV_CRI "Das Signal ist dauerhaft gesetzt, wenn das NM-Layout Cluster- Anforderungen enthält";
CM_ SG_ 2600468496 NM_Gateway_NM_aktiv_Buskopplung "Nachlauf aufgrund Kopplung zweier Busse. z.B. K-CAN und K2-CAN";
CM_ SG_ 2600468496 NM_Gateway_NM_aktiv_Connect "Nachlauf aufgrund Connect";
CM_ SG_ 2600468496 NM_Gateway_NM_aktiv_CWU "Nachlauf aufgrund CWU Anforderung";
CM_ SG_ 2600468496 NM_Gateway_NM_aktiv_Diagnose "Diagnose befindet sich nach VW80124 in einer NonDefaultDiagnostic-Session, z.B. ExtendedDiagnostic-Session";
CM_ SG_ 2600468496 NM_Gateway_NM_aktiv_EM "Nachlauf aufgrund Energiemanagement";
CM_ SG_ 2600468496 NM_Gateway_NM_aktiv_FC "Nachlauf aufgrund Funktionscluster Anforderung";
CM_ SG_ 2600468496 NM_Gateway_NM_aktiv_KL15 "Steuergerät hat KL15-EIN erkannt";
CM_ SG_ 2600468496 NM_Gateway_NM_aktiv_LIN2 "Bus aktiv aufgrund aktivem LIN2 (Hupe betätigt)";
CM_ SG_ 2600468496 NM_Gateway_NM_aktiv_OBDC "Nachlauf aufgrund OBDC";
CM_ SG_ 2600468496 NM_Gateway_NM_aktiv_Tmin "Mindestaktivzeit ist noch nicht abgelaufen (bei jedem Weckereignis wird die Mindestaktivzeit neu gestartet)";
CM_ SG_ 2600468496 NM_Gateway_NM_State "1 = Zustand Repeat Message (<-- Bus-Sleep Mode)
2 = Zustand Repeat Message (<-- Prepare Bus-Sleep Mode)
4 = Zustand Normal Operation (<-- Repeat Message)
8 = Zustand Normal Operation (<-- Ready Sleep)";
CM_ SG_ 2600468496 NM_Gateway_SNI "Source Node-Identifier (SNI) identifiziert den Sender der NM-Botschaft (Knotenadresse) eindeutig im Fahrzeug";
CM_ SG_ 2600468496 NM_Gateway_UDS_CC "Funktionseinschränkung aufgrund aktivem UDS-Communication Control, siehe VW80124";

CM_ SG_ 2600468595 NM_Info_El_CAB "CAB = Clusteraktivbits";
CM_ SG_ 2600468595 NM_Info_El_Car_Wakeup "Car Wakeup (Gateway wertet aus)

MLBevo:
- Remote Lock/Unlock
- Remote STH

MQB (MIB ab Gen3):
- OCU Download";
CM_ SG_ 2600468595 NM_Info_El_CBV_AWB "Das Signal ist zu setzen, wenn das SG aktiv den Bus geweckt hat
0 = Passiver_WakeUp = SG hat das Netzwerk nicht aktiv geweckt
1 = Akitiver_WakeUp = SG hat das Netzwerk aktiv geweckt";
CM_ SG_ 2600468595 NM_Info_El_CBV_CRI "Das Signal ist dauerhaft gesetzt, wenn das NM-Layout Cluster- Anforderungen enthält";
CM_ SG_ 2600468595 NM_Info_El_NM_aktiv_Diagnose "Diagnose befindet sich nach VW80124 in einer NonDefaultDiagnostic-Session, z.B. ExtendedDiagnostic-Session";
CM_ SG_ 2600468595 NM_Info_El_NM_aktiv_KL15 "Steuergerät hat KL15-EIN erkannt";
CM_ SG_ 2600468595 NM_Info_El_NM_aktiv_MIBCAN "MIB-CAN länger als Mindestaktivzeit aktiv für: SWDL, TEL, Radio_On/Hour_Mode, Mute_Mode
TT3: ICAN länger als Mindestaktivzeit aktiv für MFL-Bedienung";
CM_ SG_ 2600468595 NM_Info_El_NM_aktiv_Tmin "Mindestaktivzeit ist noch nicht abgelaufen (bei jedem Weckereignis wird die Mindestaktivzeit neu gestartet)";
CM_ SG_ 2600468595 NM_Info_El_NM_State "1 = Zustand Repeat Message (<-- Bus-Sleep Mode)
2 = Zustand Repeat Message (<-- Prepare Bus-Sleep Mode)
4 = Zustand Normal Operation (<-- Repeat Message)
8 = Zustand Normal Operation (<-- Ready Sleep)";
CM_ SG_ 2600468595 NM_Info_El_SNI "Source Node-Identifier (SNI) identifiziert den Sender der NM-Botschaft (Knotenadresse) eindeutig im Fahrzeug";
CM_ SG_ 2600468595 NM_Info_El_UDS_CC "Funktionseinschränkung aufgrund aktivem UDS-Communication Control, siehe VW80124";

CM_ SG_ 2600468482 NM_Sekundaer_02_CAB "CAB = Clusteraktivbits";
CM_ SG_ 2600468482 NM_Sekundaer_02_Car_Wakeup "Car Wakeup (Gateway wertet aus)";
CM_ SG_ 2600468482 NM_Sekundaer_02_CBV_AWB "Das Signal ist zu setzen, wenn das SG aktiv den Bus geweckt hat";
CM_ SG_ 2600468482 NM_Sekundaer_02_CBV_CRI "Das Signal ist dauerhaft gesetzt, wenn das NM-Layout dem neuen NM-Layout für Teilnetzbetrieb entspricht";
CM_ SG_ 2600468482 NM_Sekundaer_02_NM_aktiv_Diag "Diagnose befindet sich nach VW80124 in einer NonDefaultDiagnostic-Session, z.B. ExtendedDiagnostic-Session";
CM_ SG_ 2600468482 NM_Sekundaer_02_NM_aktiv_KL15 "Steuergerät hat KL15-EIN erkannt";
CM_ SG_ 2600468482 NM_Sekundaer_02_NM_aktiv_Tmin "Mindestaktivzeit ist noch nicht abgelaufen (bei jedem Weckereignis wird die Mindestaktivzeit neu gestartet)";
CM_ SG_ 2600468482 NM_Sekundaer_02_NM_State "1 = Zustand Repeat Message (<-- Bus-Sleep Mode)
2 = Zustand Repeat Message (<-- Prepare Bus-Sleep Mode)
4 = Zustand Normal Operation (<-- Repeat Message)
8 = Zustand Normal Operation (<-- Ready Sleep)";
CM_ SG_ 2600468482 NM_Sekundaer_02_SNI "Das Signal beinhaltet den Source Node Identifier (Knotenadresse, die auch in der Abbildungsvorschrift zur CAN-ID für die NM-High Botschaft verwendet wird).";
CM_ SG_ 2600468482 NM_Sekundaer_02_UDS_CC "Funktionseinschränkung aufgrund aktivem UDS-Communication Control; siehe VW80124";

CM_ SG_ 1377 NV_MessZeitpunkt "Messzeitpunkt der Objekte und der Ergebnisse anderer Wahrnehmungsmodule
Bei Nightvision: Aufnahmezeitpunkt des zugehörigen Bildes";
CM_ SG_ 1377 NV_NichtVerfuegbar "Verfuegbarkeit Nightvision";
CM_ SG_ 1377 NV_Obj_01_InvTTCBildebStdA "Standardabweichung zu NV_Obj_01_InvTTCBildeb";
CM_ SG_ 1377 NV_Obj_01_Klasse "Klasse des Objekts";
CM_ SG_ 1377 NV_Obj_Links "Objekt für Markierungslicht in Fahrtrichtung links";
CM_ SG_ 1377 NV_Obj_Rechts "Objekt für Markierungslicht in Fahrtrichtung rechts";
CM_ SG_ 1377 NV_Obj_Warnung_Fussgaenger "Warnung auf NV_Obj_01 im Fahrzeug signalisiert";
CM_ SG_ 1377 NV_Sensor_PositionX "Position der Kamera in USK-Koordinaten
x-Koordinate des Fokussierpunktes der Kamera-Optik";
CM_ SG_ 1377 NV_Sensor_PositionY "Position der Kamera in USK-Koordinaten
y-Koordinate des Fokussierpunktes der Kamera-Optik";
CM_ SG_ 1377 NV_Sensor_PositionZ "Position der Kamera in USK-Koordinaten
z-Koordinate des Fokussierpunktes der Kamera-Optik";

CM_ SG_ 1635 BEM_02_Abschaltstufen "Abschaltstufen des Ruhestrommanagements (Initialisierungswert aus EEprom)

Stufe 0 (keine Einschraenkungen)
Stufe 1 (Abschaltung Hochstromverbraucher)
Stufe 2 (Infotainmentabschaltung)
Stufe 3 (Wake-Up-Sperre)

Für den Transport- und Ruhestrommessm";
CM_ SG_ 1635 BEM_Anf_KL15_schalten "Abschaltempfehlung bzw. Verhinderung der automatischen Abschaltung Kl15 durch das BCM";
CM_ SG_ 1635 BEM_Batteriediagnose "Anzeige von Textwarnungen";
CM_ SG_ 1635 BEM_Generatordiagnose "Ansteuerung Generatorwarnleuchte im Kombi
";
CM_ SG_ 1635 BEM_HL_Regelung_Status "Status Regelung Heizleistung
";
CM_ SG_ 1635 BEM_Ladezustand "Ladezustand der Niedervoltbatterie
";
CM_ SG_ 1635 BEM_MMI_Vorwarnung "Anzeige Vorwarnung MMI-Abschaltung (Initialisierungswert aus EEprom)
";
CM_ SG_ 1635 BEM_Red_Innengeblaese "Reduzierung Innengebläse
";
CM_ SG_ 1635 BEM_REK_aktiv "Rekuperationsfreigabe vom Energiemanagement
0x0 = keine Rekuperationsfreigabe
0x1 = Rekuperationsfreigabe";
CM_ SG_ 1635 BEM_STH_Einschaltverbot "Einschränkung Standheizung/-lüftung durch BEM: Setzt der BEM das Bit, dann darf die Standheizung nicht mehr einschalten
(Die Standheizung muss aber nicht abschalten, sondern darf weiterbrennen)
(Initialisierungswert aus EEprom)
";
CM_ SG_ 1635 BEM_STH_Zielzeit "Maximal mögliche Zeit für den Standheizungsbetrieb, um die Startfähigkeit nicht zu gefährden";
CM_ SG_ 1635 BEM_UBDM "Batteriespannung, gemessen vom Batteriedatenmodul";
CM_ SG_ 1635 BEM_UGenSoll "Sollspannungsvorgabe an den Generator, beinhaltet temperaturoptimierte Batterieladung und Rekuperation";
CM_ SG_ 1635 MIB_Stromsparmodus "Signal beschreibt die Aktivierung für den Stromsparmodus beim MIB.
Bei AUS (= 0) gibt es keine weitere Anforderung an die MIB-Komponenten.
Bei EIN (= 1) werden alle MIB Komponenten in einen Stromsparmodus versetzt.";
CM_ SG_ 1635 NVEM_Anf_SD_schalten "Anforderung Nachlauf für den Steckdosenbetrieb
Initialisierungswert aus EEprom";
CM_ SG_ 1635 NVEM_Batterie_Service "Anforderung einer Batterie-Service - Anzeige / Anforderung an die Werkstatt über MOD";
CM_ SG_ 1635 NVEM_Freigabe_OnlineUpdate "Freigabe für Online-Update durch Energiemanagement";
CM_ SG_ 1635 NVEM_Freigabe_ORU4 "Bestätigung oder Ablehnung eines konkreten, angefragten Online Updates durch das Energiemanagements";
CM_ SG_ 1635 NVEM_Last_Anf "Das NVEM fordert für die Batteriediagnose einen Lastimpuls vom Fahrzeug an, der durch kontrollierte Verbraucherzuschaltungen (z. B. Aktivierung Heckscheibenheizung) generiert wird";

CM_ SG_ 913 MO_QBit_Aussen_Temp "QBit der Aussentemperatur. Gesetzt bei Ersatzwert, Init oder Fehler.";
CM_ SG_ 913 MO_Servicemodus "Ausgabe aktiver Service-Mode";
CM_ SG_ 913 OBD_Abs_Load_Val "Absolute Load Value

Übertragung von Meßgrößen an das Getriebesteuergerät für Freeze Frame Abspeicherung bei Getriebefehlern

PID $43 Absolute Load Value; 0 .. 25700%  mit 100/255 %/bit";
CM_ SG_ 913 OBD_Abs_Pedal_Pos "Absolute Pedal Position

Übertragung von Meßgrößen an das Getriebesteuergerät für Freeze Frame Abspeicherung bei Getriebefehlern

PID $49 Accelerator Pedal Position D; 0 .. 100% mit 100/255 %/bit";
CM_ SG_ 913 OBD_Abs_Throttle_Pos "Absolute Throttle Position

Übertragung von Meßgrößen an das Getriebesteuergerät für Freeze Frame Abspeicherung bei Getriebefehlern

PID $11 Absolute Throttle Position; 0 .. 100% mit 100/255 %/bit";
CM_ SG_ 913 OBD_Calc_Load_Val "Calculated Load Value

Übertragung von Meßgrößen an das Getriebesteuergerät für Freeze Frame Abspeicherung bei Getriebefehlern

PID $04 Calculated Load Value; 0 .. 100% mit 100/255 % per bit
";
CM_ SG_ 913 OBD_ClearMem_Inhibit "Bei FSP_Loeschen_zulässig müssen alle OBD-ECUs im Gesamtfahrzeug einen Service 04hex Request (Ereignisspeicher löschen) korrekt ausführen. 

In MLB-, MLBevo-, MQB-Fahrzeugkonzepten muss der MIL-Master/Motorsteuergerät bei Kl.15 ein, projektabhängig, kon";
CM_ SG_ 913 OBD_Eng_Cool_Temp "Engine Coolant Temperature

Übertragung von Meßgrößen an das Getriebesteuergerät für Freeze Frame Abspeicherung bei Getriebefehlern

PID $05 Engine Coolant Temperature; -40 .. +215°C mit 1°C/bit und 40°C Offset";
CM_ SG_ 913 OBD_Kaltstart_Denominator "Bestimmte Diagnosen werden nur unter Kaltstartbedingungen durchgeführt, der entsprechende Denominator bei IUMPR-pflichtigen Systemen wird anhand dieses vom MSG gebildeten Signals inkrementiert. (Entspricht EVAP-Denominator)";
CM_ SG_ 913 OBD_Minimum_Trip "Grundlage OBD-Gesetz CCR 1968.2 (d)(4.3) Denominator Specifications
Bildung des General Denominator 'Normed Trip':
 600 sec. (kumulativ) Zeit nach Motorstart
 300 sec. (kumulativ) mit Fahrzeuggeschwindigkeit > 25 mph (40 km/h)
 30 sec. (kontinuierlich";
CM_ SG_ 913 OBD_Normed_Trip "Gesetzlich definierte 'Normed Condition' erfüllt, 'General Denominator' darf erhöht werden";
CM_ SG_ 913 OBD_Sperrung_IUMPR "Wenn der General Denominator auf Grund eines Fehlers in den Eingangsgrößen gesperrt wird, wird diese Information über Bussystem als OBD-Statusinformation OBD_Sperrung_IUMPR für andere OBD-Steuergeräte bereitgestellt. 

Das MSG (MIL-Master) setzt dieses ";
CM_ SG_ 913 OBD_Sperrung_Kaltstart_Denom "Information vom MIL Master, dass die Bildung des EVAP Denominators  im Motor nicht möglich ist und damit der noECM-Denominator gesperrt werden darf.";
CM_ SG_ 913 OBD_Warm_Up_Cycle "Mit dem Warm-Up-Cycle wird der zentrale Verlernzähler vom Gateway inkrementiert";

CM_ SG_ 2549875386 OBDC_DDA_Req_Data "TP-Kanal für den Onboard Datensammler";

CM_ SG_ 2550006458 OBDC_DDA_Resp_Data "TP-Kanal für den Onboard Datensammler";

CM_ SG_ 2549940736 OBDC_Funktionaler_Req_All_Data "VDC funktionaler Request auf CANHS";

CM_ SG_ 2549875367 OBDC_SDC1_Req_Data "OBDC Strecke für SDC1 - Req Kanal";

CM_ SG_ 2550006439 OBDC_SDC1_Resp_Data "OBDC Kanal SDC1";

CM_ SG_ 2549875368 OBDC_SDC2_Req_Data "OBDC Kanal SDC2";

CM_ SG_ 2550006440 OBDC_SDC2_Resp_Data "OBDC Kanal SD2";

CM_ SG_ 2549875365 OBDC_WLC1_Req_Data "OBDC Strecke für WLC1 - Req Kanal";

CM_ SG_ 2550006437 OBDC_WLC1_Resp_Data "OBDC Strecke für WLC1 - Resp Kanal";

CM_ SG_ 2549875366 OBDC_WLC2_Req_Data "OBDC Strecke für WLC2 - Req Kanal";

CM_ SG_ 2550006438 OBDC_WLC2_Resp_Data "OBDC Strecke für WLC2 - Resp Kanal";

CM_ SG_ 2589283656 ORU_Status "Verteilung des internen ORU Zustandes";
CM_ SG_ 2589283656 ORU_Warnung "Wenn durch Störungen der Funktion Online Remote Update nicht sichergestellt ist, dass vor Kunde keine Funktionseinschränkungen auftreten, muss der Benutzer des Fahrzeugs entsprechend gewarnt werden.";
BA_DEF_REL_ BU_SG_REL_  "GenSigTimeoutTime" INT 0 65535;
BA_DEF_ BO_  "DiagRequest" ENUM "No", "Yes";
BA_DEF_ BO_  "DiagResponse" ENUM "No", "Yes";
BA_DEF_ BO_  "DiagState" ENUM "No", "Yes";
BA_DEF_ BO_  "GenMsgChkConstant" HEX 0 4095;
BA_DEF_ BO_  "GenMsgCycleTime" INT 0 65535;
BA_DEF_ BO_  "GenMsgCycleTimeFast" INT 0 65535;
BA_DEF_ BO_  "GenMsgDelayTime" INT 0 100000;
BA_DEF_ BO_  "GenMsgILSupport" ENUM "No", "Yes";
BA_DEF_ BO_  "GenMsgNrOfRepetition" INT 0 100;
BA_DEF_ BO_  "GenMsgPDUConstants" STRING;
BA_DEF_ BO_  "GenMsgSendType" ENUM "Cyclic", "not_used", "not_used", "not_used", "not_used", "not_used", "not_used", "IfActive", "NoMsgSendType";
BA_DEF_ BO_  "GenMsgStartDelayTime" INT 0 100000;
BA_DEF_ BO_  "NmMessage" ENUM "No", "Yes";
BA_DEF_ BO_  "NmhMessage" ENUM "No", "Yes";
BA_DEF_ BO_  "MsgType" ENUM "Application", "NM ", "NMH", "TP2.0", "ISO-TP ", "BAP", "EID", "KS", "XCP_PRE_CONFIGURED", "XCP_RUNTIME_CONFIGURED";
BA_DEF_ BO_  "VAGTP20_API" HEX 0 255;
BA_DEF_ BO_  "VAGTP20_DynConnection" ENUM "No", "Yes";
BA_DEF_ BO_  "VAGTP20_DynSetup" ENUM "No", "Yes";
BA_DEF_ BO_  "VAGTP20_StatConnection" ENUM "No", "Yes";
BA_DEF_ SG_  "GenSigActiveRepetitions" INT -2147483648 2147483647;
BA_DEF_ SG_  "GenSigInactiveValue" INT -2147483648 2147483647;
BA_DEF_ SG_  "GenSigSendType" ENUM "Cyclic", "OnWrite", "OnWriteWithRepetition", "OnChange", "OnChangeWithRepetition", "IfActive", "IfActiveWithRepetition", "NoSigSendType", "OnChangeAndIfActive", "OnChangeAndIfActiveWithRepetition";
BA_DEF_ SG_  "GenSigStartValue" INT -2147483648 2147483647;
BA_DEF_ SG_  "NWM-WakeupAllowed" ENUM "No", "Yes";
BA_DEF_ SG_  "GenSigFuncType" ENUM "NoFunction", "MsgCounter", "CRC-8", "XOR", "XOR-2", "DatedBit", "SW-Kl15", "CHK", "Constant", "Protocol", "CRC-8-SAE_J1850", "CRC-32", "DataLength", "DataID", "MsgCounter16", "SOK-Signatur", "Cluster";
BA_DEF_ SG_  "GenSigSwitchedByIgnition" ENUM "No", "Yes";
BA_DEF_ SG_  "Fehlerwert" HEX 0 2147483647;
BA_DEF_ SG_  "GenSigMissingSourceValue" HEX 0 2147483647;
BA_DEF_DEF_REL_  "GenSigTimeoutTime" 0;
BA_DEF_DEF_  "DiagRequest" "No";
BA_DEF_DEF_  "DiagResponse" "No";
BA_DEF_DEF_  "DiagState" "No";
BA_DEF_DEF_  "GenMsgChkConstant" 0;
BA_DEF_DEF_  "GenMsgCycleTime" 0;
BA_DEF_DEF_  "GenMsgCycleTimeFast" 0;
BA_DEF_DEF_  "GenMsgDelayTime" 0;
BA_DEF_DEF_  "GenMsgILSupport" "No";
BA_DEF_DEF_  "GenMsgNrOfRepetition" 0;
BA_DEF_DEF_  "GenMsgPDUConstants" "";
BA_DEF_DEF_  "GenMsgSendType" "NoMsgSendType";
BA_DEF_DEF_  "GenMsgStartDelayTime" 0;
BA_DEF_DEF_  "NmMessage" "No";
BA_DEF_DEF_  "NmhMessage" "No";
BA_DEF_DEF_  "MsgType" "Application";
BA_DEF_DEF_  "VAGTP20_API" 0;
BA_DEF_DEF_  "VAGTP20_DynConnection" "No";
BA_DEF_DEF_  "VAGTP20_DynSetup" "No";
BA_DEF_DEF_  "VAGTP20_StatConnection" "No";
BA_DEF_DEF_  "GenSigActiveRepetitions" 0;
BA_DEF_DEF_  "GenSigInactiveValue" 0;
BA_DEF_DEF_  "GenSigSendType" "NoSigSendType";
BA_DEF_DEF_  "GenSigStartValue" 0;
BA_DEF_DEF_  "NWM-WakeupAllowed" "No";
BA_DEF_DEF_  "GenSigFuncType" "NoFunction";
BA_DEF_DEF_  "GenSigSwitchedByIgnition" "Yes";
BA_DEF_DEF_  "Fehlerwert" 0;
BA_DEF_DEF_  "GenSigMissingSourceValue" 0;
BA_ "GenMsgCycleTime" BO_ 283 500;
BA_ "GenMsgDelayTime" BO_ 283 10;
BA_ "GenMsgILSupport" BO_ 283 1;
BA_ "GenMsgSendType" BO_ 283 0;
BA_ "GenMsgCycleTime" BO_ 2589283475 960;
BA_ "GenMsgILSupport" BO_ 2589283475 1;
BA_ "GenMsgSendType" BO_ 2589283475 0;
BA_ "GenMsgCycleTime" BO_ 706 400;
BA_ "GenMsgDelayTime" BO_ 706 80;
BA_ "GenMsgILSupport" BO_ 706 1;
BA_ "GenMsgSendType" BO_ 706 0;
BA_ "GenMsgStartDelayTime" BO_ 706 80;
BA_ "GenMsgCycleTime" BO_ 2589283599 960;
BA_ "GenMsgDelayTime" BO_ 2589283599 160;
BA_ "GenMsgILSupport" BO_ 2589283599 1;
BA_ "GenMsgSendType" BO_ 2589283599 0;
BA_ "GenMsgChkConstant" BO_ 1601 71;
BA_ "GenMsgCycleTime" BO_ 1601 960;
BA_ "GenMsgILSupport" BO_ 1601 1;
BA_ "GenMsgPDUConstants" BO_ 1601 "0x47,0x47,0x47,0x47,0x47,0x47,0x47,0x47,0x47,0x47,0x47,0x47,0x47,0x47,0x47,0x47";
BA_ "GenMsgSendType" BO_ 1601 0;
BA_ "GenMsgCycleTime" BO_ 305 100;
BA_ "GenMsgILSupport" BO_ 305 1;
BA_ "GenMsgSendType" BO_ 305 0;
BA_ "GenMsgChkConstant" BO_ 1376 101;
BA_ "GenMsgCycleTime" BO_ 1376 160;
BA_ "GenMsgILSupport" BO_ 1376 1;
BA_ "GenMsgPDUConstants" BO_ 1376 "0x65,0x65,0x65,0x65,0x65,0x65,0x65,0x65,0x65,0x65,0x65,0x65,0x65,0x65,0x65,0x65";
BA_ "GenMsgSendType" BO_ 1376 0;
BA_ "GenMsgCycleTime" BO_ 1155 320;
BA_ "GenMsgDelayTime" BO_ 1155 40;
BA_ "GenMsgILSupport" BO_ 1155 1;
BA_ "GenMsgSendType" BO_ 1155 0;
BA_ "GenMsgCycleTime" BO_ 1156 200;
BA_ "GenMsgILSupport" BO_ 1156 1;
BA_ "GenMsgSendType" BO_ 1156 0;
BA_ "GenMsgStartDelayTime" BO_ 1156 20;
BA_ "GenMsgCycleTime" BO_ 1157 200;
BA_ "GenMsgILSupport" BO_ 1157 1;
BA_ "GenMsgSendType" BO_ 1157 0;
BA_ "GenMsgStartDelayTime" BO_ 1157 30;
BA_ "GenMsgCycleTime" BO_ 2527679512 200;
BA_ "GenMsgILSupport" BO_ 2527679512 1;
BA_ "GenMsgSendType" BO_ 2527679512 0;
BA_ "GenMsgStartDelayTime" BO_ 2527679512 60;
BA_ "GenMsgCycleTime" BO_ 2527679665 200;
BA_ "GenMsgILSupport" BO_ 2527679665 1;
BA_ "GenMsgSendType" BO_ 2527679665 0;
BA_ "GenMsgCycleTime" BO_ 1158 200;
BA_ "GenMsgILSupport" BO_ 1158 1;
BA_ "GenMsgSendType" BO_ 1158 0;
BA_ "GenMsgStartDelayTime" BO_ 1158 40;
BA_ "GenMsgCycleTime" BO_ 2589283496 500;
BA_ "GenMsgILSupport" BO_ 2589283496 1;
BA_ "GenMsgSendType" BO_ 2589283496 0;
BA_ "GenMsgCycleTime" BO_ 2527679647 200;
BA_ "GenMsgILSupport" BO_ 2527679647 1;
BA_ "GenMsgSendType" BO_ 2527679647 0;
BA_ "GenMsgCycleTime" BO_ 2527679645 200;
BA_ "GenMsgILSupport" BO_ 2527679645 1;
BA_ "GenMsgSendType" BO_ 2527679645 0;
BA_ "GenMsgCycleTime" BO_ 1696 200;
BA_ "GenMsgDelayTime" BO_ 1696 20;
BA_ "GenMsgILSupport" BO_ 1696 1;
BA_ "GenMsgSendType" BO_ 1696 0;
BA_ "GenMsgCycleTime" BO_ 2600468622 200;
BA_ "GenMsgCycleTimeFast" BO_ 2600468622 10;
BA_ "GenMsgNrOfRepetition" BO_ 2600468622 3;
BA_ "GenMsgSendType" BO_ 2600468622 7;
BA_ "NmhMessage" BO_ 2600468622 1;
BA_ "MsgType" BO_ 2600468622 2;
BA_ "GenMsgCycleTime" BO_ 2600468627 200;
BA_ "GenMsgCycleTimeFast" BO_ 2600468627 10;
BA_ "GenMsgNrOfRepetition" BO_ 2600468627 3;
BA_ "GenMsgSendType" BO_ 2600468627 7;
BA_ "NmhMessage" BO_ 2600468627 1;
BA_ "MsgType" BO_ 2600468627 2;
BA_ "GenMsgCycleTime" BO_ 2600468666 200;
BA_ "GenMsgCycleTimeFast" BO_ 2600468666 10;
BA_ "GenMsgNrOfRepetition" BO_ 2600468666 3;
BA_ "GenMsgSendType" BO_ 2600468666 7;
BA_ "NmhMessage" BO_ 2600468666 1;
BA_ "MsgType" BO_ 2600468666 2;
BA_ "GenMsgCycleTime" BO_ 2600468496 200;
BA_ "GenMsgCycleTimeFast" BO_ 2600468496 10;
BA_ "GenMsgNrOfRepetition" BO_ 2600468496 3;
BA_ "GenMsgSendType" BO_ 2600468496 7;
BA_ "NmhMessage" BO_ 2600468496 1;
BA_ "MsgType" BO_ 2600468496 2;
BA_ "GenMsgCycleTime" BO_ 2600468595 200;
BA_ "GenMsgCycleTimeFast" BO_ 2600468595 10;
BA_ "GenMsgNrOfRepetition" BO_ 2600468595 3;
BA_ "GenMsgSendType" BO_ 2600468595 7;
BA_ "NmhMessage" BO_ 2600468595 1;
BA_ "MsgType" BO_ 2600468595 2;
BA_ "GenMsgCycleTime" BO_ 2600468482 200;
BA_ "GenMsgCycleTimeFast" BO_ 2600468482 10;
BA_ "GenMsgNrOfRepetition" BO_ 2600468482 3;
BA_ "GenMsgSendType" BO_ 2600468482 7;
BA_ "NmhMessage" BO_ 2600468482 1;
BA_ "MsgType" BO_ 2600468482 2;
BA_ "GenMsgCycleTime" BO_ 1377 200;
BA_ "GenMsgDelayTime" BO_ 1377 40;
BA_ "GenMsgILSupport" BO_ 1377 1;
BA_ "GenMsgSendType" BO_ 1377 0;
BA_ "GenMsgStartDelayTime" BO_ 1377 180;
BA_ "GenMsgCycleTime" BO_ 1635 100;
BA_ "GenMsgILSupport" BO_ 1635 1;
BA_ "GenMsgPDUConstants" BO_ 1635 "0x7d,0xba,0x97,0x94,0x5a,0x4a,0xeb,0xd4,0x6c,0x28,0x54,0x81,0xc7,0x1c,0x25,0x2a";
BA_ "GenMsgSendType" BO_ 1635 0;
BA_ "GenMsgStartDelayTime" BO_ 1635 10;
BA_ "GenMsgCycleTime" BO_ 913 500;
BA_ "GenMsgILSupport" BO_ 913 1;
BA_ "GenMsgSendType" BO_ 913 0;
BA_ "DiagRequest" BO_ 2549875311 1;
BA_ "MsgType" BO_ 2549875311 4;
BA_ "DiagResponse" BO_ 2550006383 1;
BA_ "MsgType" BO_ 2550006383 4;
BA_ "DiagRequest" BO_ 2549875342 1;
BA_ "MsgType" BO_ 2549875342 4;
BA_ "DiagResponse" BO_ 2550006414 1;
BA_ "MsgType" BO_ 2550006414 4;
BA_ "DiagRequest" BO_ 2549875347 1;
BA_ "MsgType" BO_ 2549875347 4;
BA_ "DiagResponse" BO_ 2550006419 1;
BA_ "MsgType" BO_ 2550006419 4;
BA_ "DiagRequest" BO_ 2549875386 1;
BA_ "MsgType" BO_ 2549875386 4;
BA_ "DiagResponse" BO_ 2550006458 1;
BA_ "MsgType" BO_ 2550006458 4;
BA_ "DiagState" BO_ 2549940736 1;
BA_ "MsgType" BO_ 2549940736 4;
BA_ "DiagRequest" BO_ 2549875299 1;
BA_ "MsgType" BO_ 2549875299 4;
BA_ "DiagResponse" BO_ 2550006371 1;
BA_ "MsgType" BO_ 2550006371 4;
BA_ "DiagRequest" BO_ 2549875315 1;
BA_ "MsgType" BO_ 2549875315 4;
BA_ "DiagResponse" BO_ 2550006387 1;
BA_ "MsgType" BO_ 2550006387 4;
BA_ "DiagRequest" BO_ 2549875312 1;
BA_ "MsgType" BO_ 2549875312 4;
BA_ "DiagResponse" BO_ 2550006384 1;
BA_ "MsgType" BO_ 2550006384 4;
BA_ "DiagRequest" BO_ 2549875370 1;
BA_ "MsgType" BO_ 2549875370 4;
BA_ "DiagResponse" BO_ 2550006442 1;
BA_ "MsgType" BO_ 2550006442 4;
BA_ "DiagRequest" BO_ 2549875371 1;
BA_ "MsgType" BO_ 2549875371 4;
BA_ "DiagResponse" BO_ 2550006443 1;
BA_ "MsgType" BO_ 2550006443 4;
BA_ "DiagRequest" BO_ 2549875367 1;
BA_ "MsgType" BO_ 2549875367 4;
BA_ "DiagResponse" BO_ 2550006439 1;
BA_ "MsgType" BO_ 2550006439 4;
BA_ "DiagRequest" BO_ 2549875368 1;
BA_ "MsgType" BO_ 2549875368 4;
BA_ "DiagResponse" BO_ 2550006440 1;
BA_ "MsgType" BO_ 2550006440 4;
BA_ "DiagRequest" BO_ 2549875309 1;
BA_ "MsgType" BO_ 2549875309 4;
BA_ "DiagResponse" BO_ 2550006381 1;
BA_ "MsgType" BO_ 2550006381 4;
BA_ "DiagRequest" BO_ 2549875365 1;
BA_ "MsgType" BO_ 2549875365 4;
BA_ "DiagResponse" BO_ 2550006437 1;
BA_ "MsgType" BO_ 2550006437 4;
BA_ "DiagRequest" BO_ 2549875366 1;
BA_ "MsgType" BO_ 2549875366 4;
BA_ "DiagResponse" BO_ 2550006438 1;
BA_ "MsgType" BO_ 2550006438 4;
BA_ "GenMsgCycleTime" BO_ 2589283656 960;
BA_ "GenMsgDelayTime" BO_ 2589283656 160;
BA_ "GenMsgILSupport" BO_ 2589283656 1;
BA_ "GenMsgPDUConstants" BO_ 2589283656 "0xee,0xcc,0x2f,0x27,0x93,0x0c,0x45,0x97,0x87,0x2e,0xec,0x3b,0xd3,0x35,0xcb,0x4a";
BA_ "GenMsgSendType" BO_ 2589283656 0;
BA_ "GenMsgStartDelayTime" BO_ 2589283656 160;
BA_ "GenSigSendType" SG_ 283 MO_AIAD_MaxLeistung 0;
BA_ "GenSigStartValue" SG_ 283 MO_AIAD_MaxLeistung 255;
BA_ "GenSigSwitchedByIgnition" SG_ 283 MO_AIAD_MaxLeistung 0;
BA_ "GenSigSendType" SG_ 283 MO_EBoost_verf_praed 0;
BA_ "GenSigSwitchedByIgnition" SG_ 283 MO_EBoost_verf_praed 0;
BA_ "GenSigSendType" SG_ 283 MO_eLaunch_verf 0;
BA_ "GenSigSwitchedByIgnition" SG_ 283 MO_eLaunch_verf 0;
BA_ "GenSigSendType" SG_ 283 MO_Fahrbereitschaft 3;
BA_ "GenSigSwitchedByIgnition" SG_ 283 MO_Fahrbereitschaft 0;
BA_ "GenSigSendType" SG_ 283 MO_Freilauf_Info 0;
BA_ "GenSigSwitchedByIgnition" SG_ 283 MO_Freilauf_Info 0;
BA_ "GenSigSendType" SG_ 283 MO_Freilauf_Status 3;
BA_ "GenSigSwitchedByIgnition" SG_ 283 MO_Freilauf_Status 0;
BA_ "Fehlerwert" SG_ 283 MO_Freilauf_Status 7;
BA_ "GenSigSendType" SG_ 283 MO_Heckspoiler_Anf 3;
BA_ "GenSigSwitchedByIgnition" SG_ 283 MO_Heckspoiler_Anf 0;
BA_ "GenSigSendType" SG_ 283 MO_Krit_Heckobjekt 0;
BA_ "GenSigSwitchedByIgnition" SG_ 283 MO_Krit_Heckobjekt 0;
BA_ "Fehlerwert" SG_ 283 MO_Krit_Heckobjekt 7;
BA_ "GenSigSendType" SG_ 283 MO_NGS_Gangpos 0;
BA_ "GenSigSwitchedByIgnition" SG_ 283 MO_NGS_Gangpos 0;
BA_ "Fehlerwert" SG_ 283 MO_NGS_Gangpos 7;
BA_ "GenSigSendType" SG_ 283 MO_Parken_WFS_Status 0;
BA_ "GenSigSwitchedByIgnition" SG_ 283 MO_Parken_WFS_Status 0;
BA_ "GenSigSendType" SG_ 283 MO_Positionierung_aktiv 0;
BA_ "GenSigSwitchedByIgnition" SG_ 283 MO_Positionierung_aktiv 0;
BA_ "GenSigSendType" SG_ 283 MO_Rennstart_verf 3;
BA_ "GenSigSwitchedByIgnition" SG_ 283 MO_Rennstart_verf 0;
BA_ "GenSigSendType" SG_ 283 MO_Status_Katheizen 0;
BA_ "GenSigSwitchedByIgnition" SG_ 283 MO_Status_Katheizen 0;
BA_ "GenSigSendType" SG_ 283 MO_Status_MIN_Wunschdrehzahl 3;
BA_ "GenSigSwitchedByIgnition" SG_ 283 MO_Status_MIN_Wunschdrehzahl 0;
BA_ "GenSigSendType" SG_ 2589283475 SCR_Einheit 0;
BA_ "GenSigSwitchedByIgnition" SG_ 2589283475 SCR_Einheit 0;
BA_ "GenSigSendType" SG_ 2589283475 SCR_Fuellstand 0;
BA_ "GenSigStartValue" SG_ 2589283475 SCR_Fuellstand 127;
BA_ "GenSigSwitchedByIgnition" SG_ 2589283475 SCR_Fuellstand 0;
BA_ "GenSigSendType" SG_ 2589283475 SCR_Nachfuellmenge_Einheit 0;
BA_ "GenSigSwitchedByIgnition" SG_ 2589283475 SCR_Nachfuellmenge_Einheit 0;
BA_ "GenSigSendType" SG_ 2589283475 SCR_Nachfuellmenge_max 0;
BA_ "GenSigStartValue" SG_ 2589283475 SCR_Nachfuellmenge_max 255;
BA_ "GenSigSwitchedByIgnition" SG_ 2589283475 SCR_Nachfuellmenge_max 0;
BA_ "GenSigSendType" SG_ 2589283475 SCR_Nachfuellmenge_min 0;
BA_ "GenSigStartValue" SG_ 2589283475 SCR_Nachfuellmenge_min 127;
BA_ "GenSigSwitchedByIgnition" SG_ 2589283475 SCR_Nachfuellmenge_min 0;
BA_ "GenSigSendType" SG_ 2589283475 SCR_Restreichweite 0;
BA_ "GenSigStartValue" SG_ 2589283475 SCR_Restreichweite 32767;
BA_ "GenSigSwitchedByIgnition" SG_ 2589283475 SCR_Restreichweite 0;
BA_ "GenSigSendType" SG_ 2589283475 SCR_Retriggersignal 0;
BA_ "GenSigSwitchedByIgnition" SG_ 2589283475 SCR_Retriggersignal 0;
BA_ "GenSigSendType" SG_ 2589283475 SCR_Tankvolumen 0;
BA_ "GenSigStartValue" SG_ 2589283475 SCR_Tankvolumen 63;
BA_ "GenSigSwitchedByIgnition" SG_ 2589283475 SCR_Tankvolumen 0;
BA_ "GenSigSendType" SG_ 2589283475 SCR_Zustand 0;
BA_ "GenSigSwitchedByIgnition" SG_ 2589283475 SCR_Zustand 0;
BA_ "GenSigSendType" SG_ 706 MO_ADR_Status 3;
BA_ "GenSigSwitchedByIgnition" SG_ 706 MO_ADR_Status 0;
BA_ "GenSigSendType" SG_ 706 MO_AGA_Sound_Texte 3;
BA_ "GenSigSwitchedByIgnition" SG_ 706 MO_AGA_Sound_Texte 0;
BA_ "GenSigSendType" SG_ 706 MO_Anz_Kuehlerluefter 3;
BA_ "GenSigSwitchedByIgnition" SG_ 706 MO_Anz_Kuehlerluefter 0;
BA_ "GenSigSendType" SG_ 706 MO_Anzeige_FMAus_Text 3;
BA_ "GenSigSwitchedByIgnition" SG_ 706 MO_Anzeige_FMAus_Text 0;
BA_ "GenSigSendType" SG_ 706 MO_Anzeige_StSt_Symbol 3;
BA_ "GenSigSwitchedByIgnition" SG_ 706 MO_Anzeige_StSt_Symbol 0;
BA_ "GenSigSendType" SG_ 706 MO_Anzeige_StSt_Text 3;
BA_ "GenSigSwitchedByIgnition" SG_ 706 MO_Anzeige_StSt_Text 0;
BA_ "GenSigSendType" SG_ 706 MO_Avus_Motorschutz 3;
BA_ "GenSigSwitchedByIgnition" SG_ 706 MO_Avus_Motorschutz 0;
BA_ "GenSigSendType" SG_ 706 MO_Fehler_MSpG 3;
BA_ "GenSigSwitchedByIgnition" SG_ 706 MO_Fehler_MSpG 0;
BA_ "GenSigSendType" SG_ 706 MO_im_Leerlauf 3;
BA_ "GenSigSwitchedByIgnition" SG_ 706 MO_im_Leerlauf 0;
BA_ "GenSigSendType" SG_ 706 MO_Oel_Temp_Radsatz_Warn 3;
BA_ "GenSigSwitchedByIgnition" SG_ 706 MO_Oel_Temp_Radsatz_Warn 0;
BA_ "GenSigSendType" SG_ 706 MO_OelMessung_Dauer 3;
BA_ "GenSigStartValue" SG_ 706 MO_OelMessung_Dauer 15;
BA_ "GenSigSwitchedByIgnition" SG_ 706 MO_OelMessung_Dauer 0;
BA_ "GenSigSendType" SG_ 706 MO_Red_Fahrleistung 3;
BA_ "GenSigSwitchedByIgnition" SG_ 706 MO_Red_Fahrleistung 0;
BA_ "GenSigSendType" SG_ 706 MO_Rekuperationsstufe 3;
BA_ "GenSigStartValue" SG_ 706 MO_Rekuperationsstufe 7;
BA_ "GenSigSwitchedByIgnition" SG_ 706 MO_Rekuperationsstufe 0;
BA_ "GenSigSendType" SG_ 706 PEA_Texte 3;
BA_ "GenSigSwitchedByIgnition" SG_ 706 PEA_Texte 0;
BA_ "GenSigSendType" SG_ 706 TSK_Einheit_vMax_FahrerInfo 3;
BA_ "GenSigSwitchedByIgnition" SG_ 706 TSK_Einheit_vMax_FahrerInfo 0;
BA_ "GenSigSendType" SG_ 706 TSK_Status_vMax_FahrerInfo 3;
BA_ "GenSigSwitchedByIgnition" SG_ 706 TSK_Status_vMax_FahrerInfo 0;
BA_ "GenSigSendType" SG_ 706 TSK_Ueberstimmt_vMax_FahrerInfo 3;
BA_ "GenSigSwitchedByIgnition" SG_ 706 TSK_Ueberstimmt_vMax_FahrerInfo 0;
BA_ "GenSigSendType" SG_ 706 TSK_vMax_FahrerInfo 3;
BA_ "GenSigSwitchedByIgnition" SG_ 706 TSK_vMax_FahrerInfo 0;
BA_ "GenSigSendType" SG_ 706 WIV_Enable_Oeldr_Motor 3;
BA_ "GenSigSwitchedByIgnition" SG_ 706 WIV_Enable_Oeldr_Motor 0;
BA_ "GenSigSendType" SG_ 2589283599 MO_Eboost_LB_active 3;
BA_ "GenSigSwitchedByIgnition" SG_ 2589283599 MO_Eboost_LB_active 0;
BA_ "GenSigSendType" SG_ 2589283599 MO_Eboost_LB_available 3;
BA_ "GenSigSwitchedByIgnition" SG_ 2589283599 MO_Eboost_LB_available 0;
BA_ "GenSigSendType" SG_ 2589283599 MO_Eboost_LB_driveraction 3;
BA_ "GenSigSwitchedByIgnition" SG_ 2589283599 MO_Eboost_LB_driveraction 0;
BA_ "GenSigSendType" SG_ 2589283599 MO_Eboost_LB_failure 3;
BA_ "GenSigSwitchedByIgnition" SG_ 2589283599 MO_Eboost_LB_failure 0;
BA_ "GenSigSendType" SG_ 2589283599 MO_Eboost_LB_LVLavailable 3;
BA_ "GenSigSwitchedByIgnition" SG_ 2589283599 MO_Eboost_LB_LVLavailable 0;
BA_ "GenSigSendType" SG_ 2589283599 MO_Eboost_LB_LVLselected 3;
BA_ "GenSigSwitchedByIgnition" SG_ 2589283599 MO_Eboost_LB_LVLselected 0;
BA_ "GenSigSendType" SG_ 2589283599 MO_Eboost_LB_possible 3;
BA_ "GenSigSwitchedByIgnition" SG_ 2589283599 MO_Eboost_LB_possible 0;
BA_ "GenSigSendType" SG_ 2589283599 MO_Kilometerstand_Wakeup 3;
BA_ "GenSigStartValue" SG_ 2589283599 MO_Kilometerstand_Wakeup 1048574;
BA_ "GenSigSwitchedByIgnition" SG_ 2589283599 MO_Kilometerstand_Wakeup 0;
BA_ "Fehlerwert" SG_ 2589283599 MO_Kilometerstand_Wakeup 1048575;
BA_ "GenSigSendType" SG_ 2589283599 MO_Nachlaufzeit_Kuehlerluefter_2 3;
BA_ "GenSigSwitchedByIgnition" SG_ 2589283599 MO_Nachlaufzeit_Kuehlerluefter_2 0;
BA_ "GenSigSendType" SG_ 2589283599 MO_Status_KL 3;
BA_ "GenSigSwitchedByIgnition" SG_ 2589283599 MO_Status_KL 0;
BA_ "GenSigSendType" SG_ 1601 MO_Ansaugsystem 0;
BA_ "GenSigFuncType" SG_ 1601 MO_Ansaugsystem 8;
BA_ "GenSigSwitchedByIgnition" SG_ 1601 MO_Ansaugsystem 0;
BA_ "GenSigSendType" SG_ 1601 MO_Anzahl_Zyl 0;
BA_ "GenSigFuncType" SG_ 1601 MO_Anzahl_Zyl 8;
BA_ "GenSigSwitchedByIgnition" SG_ 1601 MO_Anzahl_Zyl 0;
BA_ "GenSigSendType" SG_ 1601 MO_Anzeige_StSt_gueltig 0;
BA_ "GenSigSwitchedByIgnition" SG_ 1601 MO_Anzeige_StSt_gueltig 0;
BA_ "GenSigSendType" SG_ 1601 MO_Code 0;
BA_ "GenSigSwitchedByIgnition" SG_ 1601 MO_Code 0;
BA_ "GenSigSendType" SG_ 1601 MO_DPF_verbaut 0;
BA_ "GenSigFuncType" SG_ 1601 MO_DPF_verbaut 8;
BA_ "GenSigSwitchedByIgnition" SG_ 1601 MO_DPF_verbaut 0;
BA_ "GenSigSendType" SG_ 1601 MO_Faktor_Momente_02 0;
BA_ "GenSigFuncType" SG_ 1601 MO_Faktor_Momente_02 8;
BA_ "GenSigSwitchedByIgnition" SG_ 1601 MO_Faktor_Momente_02 0;
BA_ "GenSigSendType" SG_ 1601 MO_Getriebe_Code 0;
BA_ "GenSigSwitchedByIgnition" SG_ 1601 MO_Getriebe_Code 0;
BA_ "GenSigSendType" SG_ 1601 MO_Hubraum 0;
BA_ "GenSigFuncType" SG_ 1601 MO_Hubraum 8;
BA_ "GenSigSwitchedByIgnition" SG_ 1601 MO_Hubraum 0;
BA_ "GenSigSendType" SG_ 1601 MO_Hybridfahrzeug 0;
BA_ "GenSigFuncType" SG_ 1601 MO_Hybridfahrzeug 8;
BA_ "GenSigSwitchedByIgnition" SG_ 1601 MO_Hybridfahrzeug 0;
BA_ "GenSigSendType" SG_ 1601 MO_Kraftstoffart 0;
BA_ "GenSigFuncType" SG_ 1601 MO_Kraftstoffart 8;
BA_ "GenSigSwitchedByIgnition" SG_ 1601 MO_Kraftstoffart 0;
BA_ "GenSigSendType" SG_ 1601 MO_Leistung 0;
BA_ "GenSigSwitchedByIgnition" SG_ 1601 MO_Leistung 0;
BA_ "GenSigSendType" SG_ 1601 MO_OBD_Typ 0;
BA_ "GenSigSwitchedByIgnition" SG_ 1601 MO_OBD_Typ 0;
BA_ "GenSigSendType" SG_ 1601 MO_StartStopp_Codiert 0;
BA_ "GenSigFuncType" SG_ 1601 MO_StartStopp_Codiert 8;
BA_ "GenSigSwitchedByIgnition" SG_ 1601 MO_StartStopp_Codiert 0;
BA_ "GenSigSendType" SG_ 1601 Motor_Code_01_BZ 0;
BA_ "GenSigFuncType" SG_ 1601 Motor_Code_01_BZ 1;
BA_ "GenSigSwitchedByIgnition" SG_ 1601 Motor_Code_01_BZ 0;
BA_ "GenSigSendType" SG_ 1601 Motor_Code_01_CRC 0;
BA_ "GenSigFuncType" SG_ 1601 Motor_Code_01_CRC 2;
BA_ "GenSigSwitchedByIgnition" SG_ 1601 Motor_Code_01_CRC 0;
BA_ "GenSigSendType" SG_ 1601 TSK_Codierung 0;
BA_ "GenSigStartValue" SG_ 1601 TSK_Codierung 7;
BA_ "GenSigSwitchedByIgnition" SG_ 1601 TSK_Codierung 0;
BA_ "GenSigSendType" SG_ 305 Ladezustand_02 0;
BA_ "GenSigStartValue" SG_ 305 Ladezustand_02 254;
BA_ "GenSigSwitchedByIgnition" SG_ 305 Ladezustand_02 0;
BA_ "Fehlerwert" SG_ 305 Ladezustand_02 255;
BA_ "GenSigSendType" SG_ 305 MO_ePerformance 0;
BA_ "GenSigSwitchedByIgnition" SG_ 305 MO_ePerformance 0;
BA_ "Fehlerwert" SG_ 305 MO_ePerformance 255;
BA_ "GenSigSendType" SG_ 305 MO_ePowermeter 0;
BA_ "GenSigSwitchedByIgnition" SG_ 305 MO_ePowermeter 0;
BA_ "GenSigSendType" SG_ 305 MO_Powermeter 0;
BA_ "GenSigStartValue" SG_ 305 MO_Powermeter 4093;
BA_ "GenSigSwitchedByIgnition" SG_ 305 MO_Powermeter 0;
BA_ "GenSigSendType" SG_ 305 MO_Powermeter_Elm 0;
BA_ "GenSigStartValue" SG_ 305 MO_Powermeter_Elm 128;
BA_ "GenSigSwitchedByIgnition" SG_ 305 MO_Powermeter_Elm 0;
BA_ "GenSigSendType" SG_ 305 MO_Powermeter_Elm_02 0;
BA_ "GenSigStartValue" SG_ 305 MO_Powermeter_Elm_02 4094;
BA_ "GenSigSwitchedByIgnition" SG_ 305 MO_Powermeter_Elm_02 0;
BA_ "GenSigSendType" SG_ 305 MO_Zust_Antrieb 0;
BA_ "GenSigSwitchedByIgnition" SG_ 305 MO_Zust_Antrieb 0;
BA_ "GenSigSendType" SG_ 305 MO_Zust_Betriebsstrategie 0;
BA_ "GenSigSwitchedByIgnition" SG_ 305 MO_Zust_Betriebsstrategie 0;
BA_ "GenSigSendType" SG_ 1376 MO_Gesamtst_Spgfreiheit 0;
BA_ "GenSigSwitchedByIgnition" SG_ 1376 MO_Gesamtst_Spgfreiheit 0;
BA_ "GenSigSendType" SG_ 1376 MO_HV_Spannungsfreiheit 0;
BA_ "GenSigSwitchedByIgnition" SG_ 1376 MO_HV_Spannungsfreiheit 0;
BA_ "GenSigSendType" SG_ 1376 MO_HYB_Status_Betriebsstrategie 0;
BA_ "GenSigSwitchedByIgnition" SG_ 1376 MO_HYB_Status_Betriebsstrategie 0;
BA_ "GenSigSendType" SG_ 1376 MO_Reku_Leistung 0;
BA_ "GenSigSwitchedByIgnition" SG_ 1376 MO_Reku_Leistung 0;
BA_ "GenSigSendType" SG_ 1376 MO_Tankbereitschaft_Status 0;
BA_ "GenSigSwitchedByIgnition" SG_ 1376 MO_Tankbereitschaft_Status 0;
BA_ "GenSigSendType" SG_ 1376 Motor_Hybrid_04_BZ 0;
BA_ "GenSigFuncType" SG_ 1376 Motor_Hybrid_04_BZ 1;
BA_ "GenSigSwitchedByIgnition" SG_ 1376 Motor_Hybrid_04_BZ 0;
BA_ "GenSigSendType" SG_ 1376 Motor_Hybrid_04_CRC 0;
BA_ "GenSigFuncType" SG_ 1376 Motor_Hybrid_04_CRC 2;
BA_ "GenSigSwitchedByIgnition" SG_ 1376 Motor_Hybrid_04_CRC 0;
BA_ "GenSigSendType" SG_ 1155 MO_Powermeter_Charge_Grenze 3;
BA_ "GenSigStartValue" SG_ 1155 MO_Powermeter_Charge_Grenze 1022;
BA_ "GenSigSwitchedByIgnition" SG_ 1155 MO_Powermeter_Charge_Grenze 0;
BA_ "Fehlerwert" SG_ 1155 MO_Powermeter_Charge_Grenze 1023;
BA_ "GenSigSendType" SG_ 1155 Mo_Powermeter_Grenze 3;
BA_ "GenSigStartValue" SG_ 1155 Mo_Powermeter_Grenze 4093;
BA_ "GenSigSwitchedByIgnition" SG_ 1155 Mo_Powermeter_Grenze 0;
BA_ "GenSigSendType" SG_ 1155 MO_Powermeter_Grenze_strategisch 3;
BA_ "GenSigStartValue" SG_ 1155 MO_Powermeter_Grenze_strategisch 4094;
BA_ "GenSigSwitchedByIgnition" SG_ 1155 MO_Powermeter_Grenze_strategisch 0;
BA_ "Fehlerwert" SG_ 1155 MO_Powermeter_Grenze_strategisch 4095;
BA_ "GenSigSendType" SG_ 1155 MO_Powermeter_Inszenierung_aktiv 3;
BA_ "GenSigSwitchedByIgnition" SG_ 1155 MO_Powermeter_Inszenierung_aktiv 0;
BA_ "GenSigSendType" SG_ 1155 MO_Powermeter_obere_E_Grenze 3;
BA_ "GenSigStartValue" SG_ 1155 MO_Powermeter_obere_E_Grenze 4094;
BA_ "GenSigSwitchedByIgnition" SG_ 1155 MO_Powermeter_obere_E_Grenze 0;
BA_ "Fehlerwert" SG_ 1155 MO_Powermeter_obere_E_Grenze 4095;
BA_ "GenSigSendType" SG_ 1155 MO_Powermeter_untere_E_Grenze 3;
BA_ "GenSigStartValue" SG_ 1155 MO_Powermeter_untere_E_Grenze 4094;
BA_ "GenSigSwitchedByIgnition" SG_ 1155 MO_Powermeter_untere_E_Grenze 0;
BA_ "Fehlerwert" SG_ 1155 MO_Powermeter_untere_E_Grenze 4095;
BA_ "GenSigSendType" SG_ 1155 MO_Text_Aktivierung_Antrieb 3;
BA_ "GenSigStartValue" SG_ 1155 MO_Text_Aktivierung_Antrieb 15;
BA_ "GenSigSwitchedByIgnition" SG_ 1155 MO_Text_Aktivierung_Antrieb 0;
BA_ "GenSigSendType" SG_ 1156 ND_GDOP 0;
BA_ "GenSigStartValue" SG_ 1156 ND_GDOP 1022;
BA_ "GenSigSwitchedByIgnition" SG_ 1156 ND_GDOP 0;
BA_ "Fehlerwert" SG_ 1156 ND_GDOP 1023;
BA_ "GenSigSendType" SG_ 1156 ND_HDOP 0;
BA_ "GenSigStartValue" SG_ 1156 ND_HDOP 1022;
BA_ "GenSigSwitchedByIgnition" SG_ 1156 ND_HDOP 0;
BA_ "Fehlerwert" SG_ 1156 ND_HDOP 1023;
BA_ "GenSigSendType" SG_ 1156 ND_Heading 0;
BA_ "GenSigStartValue" SG_ 1156 ND_Heading 4094;
BA_ "GenSigSwitchedByIgnition" SG_ 1156 ND_Heading 0;
BA_ "Fehlerwert" SG_ 1156 ND_Heading 4095;
BA_ "GenSigSendType" SG_ 1156 ND_Init 0;
BA_ "GenSigSwitchedByIgnition" SG_ 1156 ND_Init 0;
BA_ "GenSigSendType" SG_ 1156 ND_PDOP 0;
BA_ "GenSigStartValue" SG_ 1156 ND_PDOP 1022;
BA_ "GenSigSwitchedByIgnition" SG_ 1156 ND_PDOP 0;
BA_ "Fehlerwert" SG_ 1156 ND_PDOP 1023;
BA_ "GenSigSendType" SG_ 1156 ND_TDOP 0;
BA_ "GenSigStartValue" SG_ 1156 ND_TDOP 1022;
BA_ "GenSigSwitchedByIgnition" SG_ 1156 ND_TDOP 0;
BA_ "Fehlerwert" SG_ 1156 ND_TDOP 1023;
BA_ "GenSigSendType" SG_ 1156 ND_VDOP 0;
BA_ "GenSigStartValue" SG_ 1156 ND_VDOP 1022;
BA_ "GenSigSwitchedByIgnition" SG_ 1156 ND_VDOP 0;
BA_ "Fehlerwert" SG_ 1156 ND_VDOP 1023;
BA_ "GenSigSendType" SG_ 1157 ND_SatInUse 0;
BA_ "GenSigStartValue" SG_ 1157 ND_SatInUse 30;
BA_ "GenSigSwitchedByIgnition" SG_ 1157 ND_SatInUse 0;
BA_ "Fehlerwert" SG_ 1157 ND_SatInUse 31;
BA_ "GenSigSendType" SG_ 1157 ND_SatInView 0;
BA_ "GenSigStartValue" SG_ 1157 ND_SatInView 30;
BA_ "GenSigSwitchedByIgnition" SG_ 1157 ND_SatInView 0;
BA_ "Fehlerwert" SG_ 1157 ND_SatInView 31;
BA_ "GenSigSendType" SG_ 1157 ND_UTC 0;
BA_ "GenSigSwitchedByIgnition" SG_ 1157 ND_UTC 0;
BA_ "GenSigSendType" SG_ 1157 NP_Altitude 0;
BA_ "GenSigStartValue" SG_ 1157 NP_Altitude 4094;
BA_ "GenSigSwitchedByIgnition" SG_ 1157 NP_Altitude 0;
BA_ "Fehlerwert" SG_ 1157 NP_Altitude 4095;
BA_ "GenSigSendType" SG_ 1157 POS_Guete_horizontal 0;
BA_ "GenSigStartValue" SG_ 1157 POS_Guete_horizontal 126;
BA_ "GenSigSwitchedByIgnition" SG_ 1157 POS_Guete_horizontal 0;
BA_ "Fehlerwert" SG_ 1157 POS_Guete_horizontal 127;
BA_ "GenSigSendType" SG_ 1157 POS_Guete_horizontal_verfuegbar 0;
BA_ "GenSigSwitchedByIgnition" SG_ 1157 POS_Guete_horizontal_verfuegbar 0;
BA_ "GenSigSendType" SG_ 2527679512 ND_Fuelstation_detected 0;
BA_ "GenSigStartValue" SG_ 2527679512 ND_Fuelstation_detected 3;
BA_ "GenSigSwitchedByIgnition" SG_ 2527679512 ND_Fuelstation_detected 0;
BA_ "GenSigSendType" SG_ 2527679512 ND_NrSameMeasure 0;
BA_ "GenSigSwitchedByIgnition" SG_ 2527679512 ND_NrSameMeasure 0;
BA_ "GenSigSendType" SG_ 2527679512 ND_RecDelay 0;
BA_ "GenSigStartValue" SG_ 2527679512 ND_RecDelay 4094;
BA_ "GenSigSwitchedByIgnition" SG_ 2527679512 ND_RecDelay 0;
BA_ "Fehlerwert" SG_ 2527679512 ND_RecDelay 4095;
BA_ "GenSigSendType" SG_ 2527679512 ND_RouteType 0;
BA_ "GenSigSwitchedByIgnition" SG_ 2527679512 ND_RouteType 0;
BA_ "GenSigSendType" SG_ 2527679512 ND_SendDelay 0;
BA_ "GenSigStartValue" SG_ 2527679512 ND_SendDelay 4094;
BA_ "GenSigSwitchedByIgnition" SG_ 2527679512 ND_SendDelay 0;
BA_ "Fehlerwert" SG_ 2527679512 ND_SendDelay 4095;
BA_ "GenSigSendType" SG_ 2527679512 ND_TimeOffset 0;
BA_ "GenSigSwitchedByIgnition" SG_ 2527679512 ND_TimeOffset 0;
BA_ "GenSigSendType" SG_ 2527679512 ND_TimeToDestination 0;
BA_ "GenSigStartValue" SG_ 2527679512 ND_TimeToDestination 511;
BA_ "GenSigSwitchedByIgnition" SG_ 2527679512 ND_TimeToDestination 0;
BA_ "Fehlerwert" SG_ 2527679512 ND_TimeToDestination 510;
BA_ "GenSigSendType" SG_ 2527679512 ND_Timezone_DaylightSavingOffset 0;
BA_ "GenSigSwitchedByIgnition" SG_ 2527679512 ND_Timezone_DaylightSavingOffset 0;
BA_ "GenSigSendType" SG_ 2527679512 ND_Timezone_Offset 0;
BA_ "GenSigStartValue" SG_ 2527679512 ND_Timezone_Offset 14;
BA_ "GenSigSwitchedByIgnition" SG_ 2527679512 ND_Timezone_Offset 0;
BA_ "Fehlerwert" SG_ 2527679512 ND_Timezone_Offset 15;
BA_ "GenSigSendType" SG_ 2527679512 ND_Timezone_SignBit 0;
BA_ "GenSigSwitchedByIgnition" SG_ 2527679512 ND_Timezone_SignBit 0;
BA_ "GenSigSendType" SG_ 2527679512 ND_Timezone_Validity 0;
BA_ "GenSigSwitchedByIgnition" SG_ 2527679512 ND_Timezone_Validity 0;
BA_ "GenSigSendType" SG_ 2527679512 ND_Velocity 0;
BA_ "GenSigStartValue" SG_ 2527679512 ND_Velocity 1022;
BA_ "GenSigSwitchedByIgnition" SG_ 2527679512 ND_Velocity 0;
BA_ "Fehlerwert" SG_ 2527679512 ND_Velocity 1023;
BA_ "GenSigSendType" SG_ 2527679665 ND_Avrg_Speed_RangeData 0;
BA_ "GenSigStartValue" SG_ 2527679665 ND_Avrg_Speed_RangeData 254;
BA_ "GenSigSwitchedByIgnition" SG_ 2527679665 ND_Avrg_Speed_RangeData 0;
BA_ "Fehlerwert" SG_ 2527679665 ND_Avrg_Speed_RangeData 255;
BA_ "GenSigSendType" SG_ 1158 NP_Fix 0;
BA_ "GenSigSwitchedByIgnition" SG_ 1158 NP_Fix 0;
BA_ "GenSigSendType" SG_ 1158 NP_LatDegree 0;
BA_ "GenSigStartValue" SG_ 1158 NP_LatDegree 134217726;
BA_ "GenSigSwitchedByIgnition" SG_ 1158 NP_LatDegree 0;
BA_ "Fehlerwert" SG_ 1158 NP_LatDegree 134217727;
BA_ "GenSigSendType" SG_ 1158 NP_LatDirection 0;
BA_ "GenSigStartValue" SG_ 1158 NP_LatDirection 1;
BA_ "GenSigSwitchedByIgnition" SG_ 1158 NP_LatDirection 0;
BA_ "GenSigSendType" SG_ 1158 NP_LongDegree 0;
BA_ "GenSigStartValue" SG_ 1158 NP_LongDegree 268435454;
BA_ "GenSigSwitchedByIgnition" SG_ 1158 NP_LongDegree 0;
BA_ "Fehlerwert" SG_ 1158 NP_LongDegree 268435455;
BA_ "GenSigSendType" SG_ 1158 NP_LongDirection 0;
BA_ "GenSigStartValue" SG_ 1158 NP_LongDirection 1;
BA_ "GenSigSwitchedByIgnition" SG_ 1158 NP_LongDirection 0;
BA_ "GenSigSendType" SG_ 1158 NP_Sat 0;
BA_ "GenSigStartValue" SG_ 1158 NP_Sat 30;
BA_ "GenSigSwitchedByIgnition" SG_ 1158 NP_Sat 0;
BA_ "Fehlerwert" SG_ 1158 NP_Sat 31;
BA_ "GenSigSwitchedByIgnition" SG_ 2589283496 POS_Heading 0;
BA_ "GenSigSwitchedByIgnition" SG_ 2589283496 POS_Heading_Trust 0;
BA_ "Fehlerwert" SG_ 2589283496 POS_Heading_Trust 3;
BA_ "GenSigSwitchedByIgnition" SG_ 2589283496 POS_Last_GPS_Sync 0;
BA_ "GenSigStartValue" SG_ 2589283496 POS_LatDegree 134217726;
BA_ "GenSigSwitchedByIgnition" SG_ 2589283496 POS_LatDegree 0;
BA_ "Fehlerwert" SG_ 2589283496 POS_LatDegree 134217727;
BA_ "GenSigSwitchedByIgnition" SG_ 2589283496 POS_LatDirection 0;
BA_ "GenSigStartValue" SG_ 2589283496 POS_LongDegree 268435454;
BA_ "GenSigSwitchedByIgnition" SG_ 2589283496 POS_LongDegree 0;
BA_ "Fehlerwert" SG_ 2589283496 POS_LongDegree 268435455;
BA_ "GenSigSwitchedByIgnition" SG_ 2589283496 POS_LongDirection 0;
BA_ "GenSigSendType" SG_ 2589283496 POS_MUX 0;
BA_ "GenSigStartValue" SG_ 2589283496 POS_MUX 3;
BA_ "GenSigSwitchedByIgnition" SG_ 2589283496 POS_MUX 0;
BA_ "GenSigSendType" SG_ 2589283496 POS_ODD_EVEN 0;
BA_ "GenSigSwitchedByIgnition" SG_ 2589283496 POS_ODD_EVEN 0;
BA_ "GenSigSwitchedByIgnition" SG_ 2589283496 POS_PosStati 0;
BA_ "GenSigSwitchedByIgnition" SG_ 2589283496 POS_UTC_REF 0;
BA_ "GenSigSendType" SG_ 2527679647 NFC_aktiv 0;
BA_ "GenSigSwitchedByIgnition" SG_ 2527679647 NFC_aktiv 0;
BA_ "GenSigSendType" SG_ 2527679647 NFC_ESM_aktivieren 0;
BA_ "GenSigSwitchedByIgnition" SG_ 2527679647 NFC_ESM_aktivieren 0;
BA_ "GenSigSendType" SG_ 2527679647 NFC_Front_Entr_Authorisiert 0;
BA_ "GenSigSwitchedByIgnition" SG_ 2527679647 NFC_Front_Entr_Authorisiert 0;
BA_ "GenSigSendType" SG_ 2527679647 NFC_Front_Verr_Authorisiert 0;
BA_ "GenSigSwitchedByIgnition" SG_ 2527679647 NFC_Front_Verr_Authorisiert 0;
BA_ "GenSigSendType" SG_ 2527679647 NFC_FT_Entriegelung_Authorisiert 0;
BA_ "GenSigSwitchedByIgnition" SG_ 2527679647 NFC_FT_Entriegelung_Authorisiert 0;
BA_ "GenSigSendType" SG_ 2527679647 NFC_FT_Verriegelung_Authorisiert 0;
BA_ "GenSigSwitchedByIgnition" SG_ 2527679647 NFC_FT_Verriegelung_Authorisiert 0;
BA_ "GenSigSendType" SG_ 2527679647 NFC_HD_Entriegelung_Authorisiert 0;
BA_ "GenSigSwitchedByIgnition" SG_ 2527679647 NFC_HD_Entriegelung_Authorisiert 0;
BA_ "GenSigSendType" SG_ 2527679647 NFC_HD_Verriegelung_Authorisiert 0;
BA_ "GenSigSwitchedByIgnition" SG_ 2527679647 NFC_HD_Verriegelung_Authorisiert 0;
BA_ "GenSigSendType" SG_ 2527679647 NFC_Laden_unterbrechen 0;
BA_ "GenSigSwitchedByIgnition" SG_ 2527679647 NFC_Laden_unterbrechen 0;
BA_ "GenSigSendType" SG_ 2527679647 Stellgliedtest_NFC 0;
BA_ "GenSigSwitchedByIgnition" SG_ 2527679647 Stellgliedtest_NFC 0;
BA_ "GenSigSendType" SG_ 2527679647 ZV_auf_NFC 0;
BA_ "GenSigSwitchedByIgnition" SG_ 2527679647 ZV_auf_NFC 0;
BA_ "GenSigSendType" SG_ 2527679647 ZV_zu_NFC 0;
BA_ "GenSigSwitchedByIgnition" SG_ 2527679647 ZV_zu_NFC 0;
BA_ "GenSigSendType" SG_ 2527679645 NFC_MiKo_ESM_aktiv 0;
BA_ "GenSigSwitchedByIgnition" SG_ 2527679645 NFC_MiKo_ESM_aktiv 0;
BA_ "GenSigSendType" SG_ 2527679645 NFC_MiKo_Fehler 0;
BA_ "GenSigSwitchedByIgnition" SG_ 2527679645 NFC_MiKo_Fehler 0;
BA_ "GenSigSendType" SG_ 2527679645 NFC_MiKo_Laden_unterbrechen 0;
BA_ "GenSigSwitchedByIgnition" SG_ 2527679645 NFC_MiKo_Laden_unterbrechen 0;
BA_ "GenSigSendType" SG_ 2527679645 NFC_MiKo_NFC_Device_gekoppelt 0;
BA_ "GenSigSwitchedByIgnition" SG_ 2527679645 NFC_MiKo_NFC_Device_gekoppelt 0;
BA_ "GenSigSendType" SG_ 1696 NV_Akt_Status_MMI 3;
BA_ "GenSigStartValue" SG_ 1696 NV_Akt_Status_MMI 3;
BA_ "GenSigSendType" SG_ 1696 NV_aktiv 3;
BA_ "GenSigSendType" SG_ 1696 NV_Akustik_deaktiviert_Icon 3;
BA_ "GenSigSendType" SG_ 1696 NV_Anf_Prefill 3;
BA_ "GenSigSendType" SG_ 1696 NV_AnforderungBildaufschaltung 3;
BA_ "GenSigSendType" SG_ 1696 NV_FAS_Fkt_Status 0;
BA_ "Fehlerwert" SG_ 1696 NV_FAS_Fkt_Status 3;
BA_ "GenSigSendType" SG_ 1696 NV_FGM_deaktiviert_Icon 3;
BA_ "GenSigSendType" SG_ 1696 NV_Gong 3;
BA_ "GenSigSendType" SG_ 1696 NV_HBA_Parameter 3;
BA_ "GenSigSendType" SG_ 1696 NV_Hinweise 3;
BA_ "GenSigSendType" SG_ 1696 NV_LED_Leiste 3;
BA_ "GenSigSendType" SG_ 1696 NV_Markierungslicht_links 3;
BA_ "GenSigSendType" SG_ 1696 NV_Markierungslicht_rechts 3;
BA_ "GenSigSendType" SG_ 1696 NV_Piktogramm_aktiv 3;
BA_ "GenSigSendType" SG_ 1696 NV_PreSense_Modus_System 3;
BA_ "GenSigSendType" SG_ 1696 NV_PreSense_Modus_Warnung 3;
BA_ "GenSigSendType" SG_ 1696 NV_PreSense_Status 3;
BA_ "GenSigSendType" SG_ 1696 NV_Symbol 3;
BA_ "GenSigSendType" SG_ 1696 NV_Symbol_Tierwarnung 3;
BA_ "GenSigSendType" SG_ 1696 NV_Texte 3;
BA_ "GenSigActiveRepetitions" SG_ 2600468622 NM_BedienDisp_vo_CAB 3;
BA_ "GenSigSendType" SG_ 2600468622 NM_BedienDisp_vo_CAB 4;
BA_ "GenSigSwitchedByIgnition" SG_ 2600468622 NM_BedienDisp_vo_CAB 0;
BA_ "GenSigSendType" SG_ 2600468622 NM_BedienDisp_vo_Car_Wakeup 3;
BA_ "GenSigSwitchedByIgnition" SG_ 2600468622 NM_BedienDisp_vo_Car_Wakeup 0;
BA_ "GenSigSwitchedByIgnition" SG_ 2600468622 NM_BedienDisp_vo_CBV_AWB 0;
BA_ "GenSigFuncType" SG_ 2600468622 NM_BedienDisp_vo_CBV_CRI 8;
BA_ "GenSigSwitchedByIgnition" SG_ 2600468622 NM_BedienDisp_vo_CBV_CRI 0;
BA_ "GenSigSwitchedByIgnition" SG_ 2600468622 NM_BedienDisp_vo_NM_aktiv_Diag 0;
BA_ "GenSigSwitchedByIgnition" SG_ 2600468622 NM_BedienDisp_vo_NM_aktiv_KL15 0;
BA_ "GenSigSwitchedByIgnition" SG_ 2600468622 NM_BedienDisp_vo_NM_aktiv_Restwa 0;
BA_ "GenSigSwitchedByIgnition" SG_ 2600468622 NM_BedienDisp_vo_NM_aktiv_Tmin 0;
BA_ "GenSigSwitchedByIgnition" SG_ 2600468622 NM_BedienDisp_vo_NM_State 0;
BA_ "GenSigStartValue" SG_ 2600468622 NM_BedienDisp_vo_SNI 142;
BA_ "GenSigSwitchedByIgnition" SG_ 2600468622 NM_BedienDisp_vo_SNI 0;
BA_ "GenSigSwitchedByIgnition" SG_ 2600468622 NM_BedienDisp_vo_UDS_CC 0;
BA_ "GenSigActiveRepetitions" SG_ 2600468627 NM_BedienSG_hi_CAB 3;
BA_ "GenSigSendType" SG_ 2600468627 NM_BedienSG_hi_CAB 4;
BA_ "GenSigSwitchedByIgnition" SG_ 2600468627 NM_BedienSG_hi_CAB 0;
BA_ "GenSigSendType" SG_ 2600468627 NM_BedienSG_hi_Car_Wakeup 3;
BA_ "GenSigSwitchedByIgnition" SG_ 2600468627 NM_BedienSG_hi_Car_Wakeup 0;
BA_ "GenSigSwitchedByIgnition" SG_ 2600468627 NM_BedienSG_hi_CBV_AWB 0;
BA_ "GenSigFuncType" SG_ 2600468627 NM_BedienSG_hi_CBV_CRI 8;
BA_ "GenSigSwitchedByIgnition" SG_ 2600468627 NM_BedienSG_hi_CBV_CRI 0;
BA_ "GenSigSwitchedByIgnition" SG_ 2600468627 NM_BedienSG_hi_NM_aktiv_Diagnose 0;
BA_ "GenSigSwitchedByIgnition" SG_ 2600468627 NM_BedienSG_hi_NM_aktiv_KL15 0;
BA_ "GenSigSwitchedByIgnition" SG_ 2600468627 NM_BedienSG_hi_NM_aktiv_Tmin 0;
BA_ "GenSigSwitchedByIgnition" SG_ 2600468627 NM_BedienSG_hi_NM_State 0;
BA_ "GenSigStartValue" SG_ 2600468627 NM_BedienSG_hi_SNI 147;
BA_ "GenSigSwitchedByIgnition" SG_ 2600468627 NM_BedienSG_hi_SNI 0;
BA_ "GenSigSwitchedByIgnition" SG_ 2600468627 NM_BedienSG_hi_UDS_CC 0;
BA_ "GenSigActiveRepetitions" SG_ 2600468666 NM_DDA_CAB 3;
BA_ "GenSigSendType" SG_ 2600468666 NM_DDA_CAB 4;
BA_ "GenSigSwitchedByIgnition" SG_ 2600468666 NM_DDA_CAB 0;
BA_ "GenSigSendType" SG_ 2600468666 NM_DDA_Car_Wakeup 3;
BA_ "GenSigSwitchedByIgnition" SG_ 2600468666 NM_DDA_Car_Wakeup 0;
BA_ "GenSigSwitchedByIgnition" SG_ 2600468666 NM_DDA_CBV_AWB 0;
BA_ "GenSigFuncType" SG_ 2600468666 NM_DDA_CBV_CRI 8;
BA_ "GenSigSwitchedByIgnition" SG_ 2600468666 NM_DDA_CBV_CRI 0;
BA_ "GenSigSwitchedByIgnition" SG_ 2600468666 NM_DDA_NM_aktiv_BT_Verbindung 0;
BA_ "GenSigSwitchedByIgnition" SG_ 2600468666 NM_DDA_NM_aktiv_Diagnose 0;
BA_ "GenSigSwitchedByIgnition" SG_ 2600468666 NM_DDA_NM_aktiv_KL15 0;
BA_ "GenSigSwitchedByIgnition" SG_ 2600468666 NM_DDA_NM_aktiv_Tmin 0;
BA_ "GenSigSwitchedByIgnition" SG_ 2600468666 NM_DDA_NM_State 0;
BA_ "GenSigStartValue" SG_ 2600468666 NM_DDA_SNI 186;
BA_ "GenSigSwitchedByIgnition" SG_ 2600468666 NM_DDA_SNI 0;
BA_ "GenSigSwitchedByIgnition" SG_ 2600468666 NM_DDA_UDS_CC 0;
BA_ "GenSigActiveRepetitions" SG_ 2600468496 NM_Gateway_CAB 3;
BA_ "GenSigSendType" SG_ 2600468496 NM_Gateway_CAB 4;
BA_ "GenSigFuncType" SG_ 2600468496 NM_Gateway_CAB 16;
BA_ "GenSigSwitchedByIgnition" SG_ 2600468496 NM_Gateway_CAB 0;
BA_ "GenSigSendType" SG_ 2600468496 NM_Gateway_Car_Wakeup 3;
BA_ "GenSigSwitchedByIgnition" SG_ 2600468496 NM_Gateway_Car_Wakeup 0;
BA_ "GenSigSwitchedByIgnition" SG_ 2600468496 NM_Gateway_CBV_AWB 0;
BA_ "GenSigSwitchedByIgnition" SG_ 2600468496 NM_Gateway_CBV_CRI 0;
BA_ "GenSigSwitchedByIgnition" SG_ 2600468496 NM_Gateway_NM_aktiv_Buskopplung 0;
BA_ "GenSigSwitchedByIgnition" SG_ 2600468496 NM_Gateway_NM_aktiv_Connect 0;
BA_ "GenSigSwitchedByIgnition" SG_ 2600468496 NM_Gateway_NM_aktiv_CWU 0;
BA_ "GenSigSwitchedByIgnition" SG_ 2600468496 NM_Gateway_NM_aktiv_Diagnose 0;
BA_ "GenSigSwitchedByIgnition" SG_ 2600468496 NM_Gateway_NM_aktiv_EM 0;
BA_ "GenSigSwitchedByIgnition" SG_ 2600468496 NM_Gateway_NM_aktiv_FC 0;
BA_ "GenSigSwitchedByIgnition" SG_ 2600468496 NM_Gateway_NM_aktiv_KL15 0;
BA_ "GenSigSwitchedByIgnition" SG_ 2600468496 NM_Gateway_NM_aktiv_LIN2 0;
BA_ "GenSigSwitchedByIgnition" SG_ 2600468496 NM_Gateway_NM_aktiv_OBDC 0;
BA_ "GenSigSwitchedByIgnition" SG_ 2600468496 NM_Gateway_NM_aktiv_Tmin 0;
BA_ "GenSigSwitchedByIgnition" SG_ 2600468496 NM_Gateway_NM_State 0;
BA_ "GenSigStartValue" SG_ 2600468496 NM_Gateway_SNI 16;
BA_ "GenSigSwitchedByIgnition" SG_ 2600468496 NM_Gateway_SNI 0;
BA_ "GenSigSwitchedByIgnition" SG_ 2600468496 NM_Gateway_UDS_CC 0;
BA_ "GenSigActiveRepetitions" SG_ 2600468595 NM_Info_El_CAB 3;
BA_ "GenSigSendType" SG_ 2600468595 NM_Info_El_CAB 4;
BA_ "GenSigSwitchedByIgnition" SG_ 2600468595 NM_Info_El_CAB 0;
BA_ "GenSigSendType" SG_ 2600468595 NM_Info_El_Car_Wakeup 3;
BA_ "GenSigSwitchedByIgnition" SG_ 2600468595 NM_Info_El_Car_Wakeup 0;
BA_ "GenSigSwitchedByIgnition" SG_ 2600468595 NM_Info_El_CBV_AWB 0;
BA_ "GenSigStartValue" SG_ 2600468595 NM_Info_El_CBV_CRI 1;
BA_ "GenSigSwitchedByIgnition" SG_ 2600468595 NM_Info_El_CBV_CRI 0;
BA_ "GenSigSwitchedByIgnition" SG_ 2600468595 NM_Info_El_NM_aktiv_Diagnose 0;
BA_ "GenSigSwitchedByIgnition" SG_ 2600468595 NM_Info_El_NM_aktiv_KL15 0;
BA_ "GenSigSwitchedByIgnition" SG_ 2600468595 NM_Info_El_NM_aktiv_MIBCAN 0;
BA_ "GenSigSwitchedByIgnition" SG_ 2600468595 NM_Info_El_NM_aktiv_Tmin 0;
BA_ "GenSigSwitchedByIgnition" SG_ 2600468595 NM_Info_El_NM_State 0;
BA_ "GenSigStartValue" SG_ 2600468595 NM_Info_El_SNI 115;
BA_ "GenSigSwitchedByIgnition" SG_ 2600468595 NM_Info_El_SNI 0;
BA_ "GenSigSwitchedByIgnition" SG_ 2600468595 NM_Info_El_UDS_CC 0;
BA_ "GenSigActiveRepetitions" SG_ 2600468482 NM_Sekundaer_02_CAB 3;
BA_ "GenSigSendType" SG_ 2600468482 NM_Sekundaer_02_CAB 4;
BA_ "GenSigFuncType" SG_ 2600468482 NM_Sekundaer_02_CAB 16;
BA_ "GenSigSwitchedByIgnition" SG_ 2600468482 NM_Sekundaer_02_CAB 0;
BA_ "GenSigSendType" SG_ 2600468482 NM_Sekundaer_02_Car_Wakeup 3;
BA_ "GenSigSwitchedByIgnition" SG_ 2600468482 NM_Sekundaer_02_Car_Wakeup 0;
BA_ "GenSigSwitchedByIgnition" SG_ 2600468482 NM_Sekundaer_02_CBV_AWB 0;
BA_ "GenSigSwitchedByIgnition" SG_ 2600468482 NM_Sekundaer_02_CBV_CRI 0;
BA_ "GenSigSwitchedByIgnition" SG_ 2600468482 NM_Sekundaer_02_NM_aktiv_Diag 0;
BA_ "GenSigSwitchedByIgnition" SG_ 2600468482 NM_Sekundaer_02_NM_aktiv_KL15 0;
BA_ "GenSigSwitchedByIgnition" SG_ 2600468482 NM_Sekundaer_02_NM_aktiv_Tmin 0;
BA_ "GenSigSwitchedByIgnition" SG_ 2600468482 NM_Sekundaer_02_NM_State 0;
BA_ "GenSigStartValue" SG_ 2600468482 NM_Sekundaer_02_SNI 2;
BA_ "GenSigSwitchedByIgnition" SG_ 2600468482 NM_Sekundaer_02_SNI 0;
BA_ "GenSigSwitchedByIgnition" SG_ 2600468482 NM_Sekundaer_02_UDS_CC 0;
BA_ "GenSigSendType" SG_ 1377 NV_MessZeitpunkt 0;
BA_ "GenSigStartValue" SG_ 1377 NV_MessZeitpunkt 8191;
BA_ "GenSigSendType" SG_ 1377 NV_NichtVerfuegbar 0;
BA_ "GenSigStartValue" SG_ 1377 NV_NichtVerfuegbar 1;
BA_ "GenSigSendType" SG_ 1377 NV_Obj_01_InvTTCBildebStdA 0;
BA_ "GenSigStartValue" SG_ 1377 NV_Obj_01_InvTTCBildebStdA 127;
BA_ "GenSigSendType" SG_ 1377 NV_Obj_01_Klasse 3;
BA_ "GenSigStartValue" SG_ 1377 NV_Obj_01_Klasse 15;
BA_ "GenSigSendType" SG_ 1377 NV_Obj_Links 3;
BA_ "GenSigSendType" SG_ 1377 NV_Obj_Rechts 3;
BA_ "GenSigSendType" SG_ 1377 NV_Obj_Warnung_Fussgaenger 3;
BA_ "GenSigSendType" SG_ 1377 NV_Sensor_PositionX 0;
BA_ "GenSigStartValue" SG_ 1377 NV_Sensor_PositionX 4095;
BA_ "GenSigSendType" SG_ 1377 NV_Sensor_PositionY 0;
BA_ "GenSigStartValue" SG_ 1377 NV_Sensor_PositionY 2047;
BA_ "GenSigSendType" SG_ 1377 NV_Sensor_PositionZ 0;
BA_ "GenSigStartValue" SG_ 1377 NV_Sensor_PositionZ 2047;
BA_ "GenSigSendType" SG_ 1635 BEM_02_Abschaltstufen 0;
BA_ "GenSigSwitchedByIgnition" SG_ 1635 BEM_02_Abschaltstufen 0;
BA_ "GenSigSendType" SG_ 1635 BEM_Anf_KL15_schalten 0;
BA_ "GenSigSwitchedByIgnition" SG_ 1635 BEM_Anf_KL15_schalten 0;
BA_ "GenSigSendType" SG_ 1635 BEM_Batteriediagnose 0;
BA_ "GenSigSwitchedByIgnition" SG_ 1635 BEM_Batteriediagnose 0;
BA_ "Fehlerwert" SG_ 1635 BEM_Batteriediagnose 7;
BA_ "GenSigSendType" SG_ 1635 BEM_Generatordiagnose 0;
BA_ "GenSigSwitchedByIgnition" SG_ 1635 BEM_Generatordiagnose 0;
BA_ "GenSigSendType" SG_ 1635 BEM_HL_Regelung_Status 0;
BA_ "GenSigSwitchedByIgnition" SG_ 1635 BEM_HL_Regelung_Status 0;
BA_ "GenSigSendType" SG_ 1635 BEM_Ladezustand 0;
BA_ "GenSigStartValue" SG_ 1635 BEM_Ladezustand 14;
BA_ "GenSigSwitchedByIgnition" SG_ 1635 BEM_Ladezustand 0;
BA_ "Fehlerwert" SG_ 1635 BEM_Ladezustand 15;
BA_ "GenSigSendType" SG_ 1635 BEM_MMI_Vorwarnung 0;
BA_ "GenSigSwitchedByIgnition" SG_ 1635 BEM_MMI_Vorwarnung 0;
BA_ "GenSigSendType" SG_ 1635 BEM_Red_Innengeblaese 0;
BA_ "GenSigSwitchedByIgnition" SG_ 1635 BEM_Red_Innengeblaese 0;
BA_ "GenSigSendType" SG_ 1635 BEM_REK_aktiv 0;
BA_ "GenSigSwitchedByIgnition" SG_ 1635 BEM_REK_aktiv 0;
BA_ "GenSigSendType" SG_ 1635 BEM_STH_Einschaltverbot 0;
BA_ "GenSigSwitchedByIgnition" SG_ 1635 BEM_STH_Einschaltverbot 0;
BA_ "GenSigSendType" SG_ 1635 BEM_STH_Zielzeit 0;
BA_ "GenSigStartValue" SG_ 1635 BEM_STH_Zielzeit 14;
BA_ "GenSigSwitchedByIgnition" SG_ 1635 BEM_STH_Zielzeit 0;
BA_ "Fehlerwert" SG_ 1635 BEM_STH_Zielzeit 15;
BA_ "GenSigSendType" SG_ 1635 BEM_UBDM 0;
BA_ "GenSigSwitchedByIgnition" SG_ 1635 BEM_UBDM 0;
BA_ "Fehlerwert" SG_ 1635 BEM_UBDM 255;
BA_ "GenSigSendType" SG_ 1635 BEM_UGenSoll 0;
BA_ "GenSigSwitchedByIgnition" SG_ 1635 BEM_UGenSoll 0;
BA_ "GenSigSendType" SG_ 1635 MIB_Stromsparmodus 0;
BA_ "GenSigSwitchedByIgnition" SG_ 1635 MIB_Stromsparmodus 0;
BA_ "GenSigSendType" SG_ 1635 NVEM_Anf_SD_schalten 0;
BA_ "GenSigSwitchedByIgnition" SG_ 1635 NVEM_Anf_SD_schalten 0;
BA_ "GenSigSendType" SG_ 1635 NVEM_Batterie_Service 0;
BA_ "GenSigSwitchedByIgnition" SG_ 1635 NVEM_Batterie_Service 0;
BA_ "GenSigSendType" SG_ 1635 NVEM_Freigabe_OnlineUpdate 0;
BA_ "GenSigSwitchedByIgnition" SG_ 1635 NVEM_Freigabe_OnlineUpdate 0;
BA_ "GenSigSendType" SG_ 1635 NVEM_Freigabe_ORU4 0;
BA_ "GenSigSwitchedByIgnition" SG_ 1635 NVEM_Freigabe_ORU4 0;
BA_ "GenSigSendType" SG_ 1635 NVEM_Last_Anf 0;
BA_ "GenSigSwitchedByIgnition" SG_ 1635 NVEM_Last_Anf 0;
BA_ "GenSigSendType" SG_ 913 MO_QBit_Aussen_Temp 0;
BA_ "GenSigStartValue" SG_ 913 MO_QBit_Aussen_Temp 1;
BA_ "GenSigSwitchedByIgnition" SG_ 913 MO_QBit_Aussen_Temp 0;
BA_ "GenSigSendType" SG_ 913 MO_Servicemodus 0;
BA_ "GenSigSwitchedByIgnition" SG_ 913 MO_Servicemodus 0;
BA_ "GenSigSendType" SG_ 913 OBD_Abs_Load_Val 0;
BA_ "GenSigStartValue" SG_ 913 OBD_Abs_Load_Val 65535;
BA_ "GenSigSwitchedByIgnition" SG_ 913 OBD_Abs_Load_Val 0;
BA_ "GenSigSendType" SG_ 913 OBD_Abs_Pedal_Pos 0;
BA_ "GenSigStartValue" SG_ 913 OBD_Abs_Pedal_Pos 255;
BA_ "GenSigSwitchedByIgnition" SG_ 913 OBD_Abs_Pedal_Pos 0;
BA_ "GenSigSendType" SG_ 913 OBD_Abs_Throttle_Pos 0;
BA_ "GenSigStartValue" SG_ 913 OBD_Abs_Throttle_Pos 255;
BA_ "GenSigSwitchedByIgnition" SG_ 913 OBD_Abs_Throttle_Pos 0;
BA_ "GenSigSendType" SG_ 913 OBD_Calc_Load_Val 0;
BA_ "GenSigStartValue" SG_ 913 OBD_Calc_Load_Val 255;
BA_ "GenSigSwitchedByIgnition" SG_ 913 OBD_Calc_Load_Val 0;
BA_ "GenSigSendType" SG_ 913 OBD_ClearMem_Inhibit 0;
BA_ "GenSigSwitchedByIgnition" SG_ 913 OBD_ClearMem_Inhibit 0;
BA_ "GenSigSendType" SG_ 913 OBD_Driving_Cycle 0;
BA_ "GenSigSwitchedByIgnition" SG_ 913 OBD_Driving_Cycle 0;
BA_ "GenSigSendType" SG_ 913 OBD_Eng_Cool_Temp 0;
BA_ "GenSigStartValue" SG_ 913 OBD_Eng_Cool_Temp 255;
BA_ "GenSigSwitchedByIgnition" SG_ 913 OBD_Eng_Cool_Temp 0;
BA_ "GenSigSendType" SG_ 913 OBD_Kaltstart_Denominator 0;
BA_ "GenSigSwitchedByIgnition" SG_ 913 OBD_Kaltstart_Denominator 0;
BA_ "GenSigSendType" SG_ 913 OBD_Minimum_Trip 0;
BA_ "GenSigSwitchedByIgnition" SG_ 913 OBD_Minimum_Trip 0;
BA_ "GenSigSendType" SG_ 913 OBD_Normed_Trip 0;
BA_ "GenSigSwitchedByIgnition" SG_ 913 OBD_Normed_Trip 0;
BA_ "GenSigSendType" SG_ 913 OBD_Sperrung_IUMPR 0;
BA_ "GenSigSwitchedByIgnition" SG_ 913 OBD_Sperrung_IUMPR 0;
BA_ "GenSigSendType" SG_ 913 OBD_Sperrung_Kaltstart_Denom 0;
BA_ "GenSigSwitchedByIgnition" SG_ 913 OBD_Sperrung_Kaltstart_Denom 0;
BA_ "GenSigSendType" SG_ 913 OBD_Warm_Up_Cycle 0;
BA_ "GenSigSwitchedByIgnition" SG_ 913 OBD_Warm_Up_Cycle 0;
BA_ "GenSigSendType" SG_ 2549875311 OBDC_AMP_Req_Data 3;
BA_ "GenSigFuncType" SG_ 2549875311 OBDC_AMP_Req_Data 9;
BA_ "GenSigSwitchedByIgnition" SG_ 2549875311 OBDC_AMP_Req_Data 0;
BA_ "GenSigSendType" SG_ 2550006383 OBDC_AMP_Resp_Data 3;
BA_ "GenSigFuncType" SG_ 2550006383 OBDC_AMP_Resp_Data 9;
BA_ "GenSigSwitchedByIgnition" SG_ 2550006383 OBDC_AMP_Resp_Data 0;
BA_ "GenSigSendType" SG_ 2549875342 OBDC_BedienDisp_vo_Req_Data 3;
BA_ "GenSigFuncType" SG_ 2549875342 OBDC_BedienDisp_vo_Req_Data 9;
BA_ "GenSigSwitchedByIgnition" SG_ 2549875342 OBDC_BedienDisp_vo_Req_Data 0;
BA_ "GenSigSendType" SG_ 2550006414 OBDC_BedienDisp_vo_Resp_Data 3;
BA_ "GenSigFuncType" SG_ 2550006414 OBDC_BedienDisp_vo_Resp_Data 9;
BA_ "GenSigSwitchedByIgnition" SG_ 2550006414 OBDC_BedienDisp_vo_Resp_Data 0;
BA_ "GenSigSendType" SG_ 2549875347 OBDC_BedienSG_hi_Req_Data 3;
BA_ "GenSigFuncType" SG_ 2549875347 OBDC_BedienSG_hi_Req_Data 9;
BA_ "GenSigSwitchedByIgnition" SG_ 2549875347 OBDC_BedienSG_hi_Req_Data 0;
BA_ "GenSigSendType" SG_ 2550006419 OBDC_BedienSG_hi_Resp_Data 3;
BA_ "GenSigFuncType" SG_ 2550006419 OBDC_BedienSG_hi_Resp_Data 9;
BA_ "GenSigSwitchedByIgnition" SG_ 2550006419 OBDC_BedienSG_hi_Resp_Data 0;
BA_ "GenSigSendType" SG_ 2549875386 OBDC_DDA_Req_Data 3;
BA_ "GenSigFuncType" SG_ 2549875386 OBDC_DDA_Req_Data 9;
BA_ "GenSigSwitchedByIgnition" SG_ 2549875386 OBDC_DDA_Req_Data 0;
BA_ "GenSigSendType" SG_ 2550006458 OBDC_DDA_Resp_Data 3;
BA_ "GenSigFuncType" SG_ 2550006458 OBDC_DDA_Resp_Data 9;
BA_ "GenSigSwitchedByIgnition" SG_ 2550006458 OBDC_DDA_Resp_Data 0;
BA_ "GenSigSendType" SG_ 2549940736 OBDC_Funktionaler_Req_All_Data 3;
BA_ "GenSigFuncType" SG_ 2549940736 OBDC_Funktionaler_Req_All_Data 9;
BA_ "GenSigSwitchedByIgnition" SG_ 2549940736 OBDC_Funktionaler_Req_All_Data 0;
BA_ "GenSigSendType" SG_ 2549875299 OBDC_Gurtmikro_Req_Data 3;
BA_ "GenSigFuncType" SG_ 2549875299 OBDC_Gurtmikro_Req_Data 9;
BA_ "GenSigSwitchedByIgnition" SG_ 2549875299 OBDC_Gurtmikro_Req_Data 0;
BA_ "GenSigSendType" SG_ 2550006371 OBDC_Gurtmikro_Resp_Data 3;
BA_ "GenSigFuncType" SG_ 2550006371 OBDC_Gurtmikro_Resp_Data 9;
BA_ "GenSigSendType" SG_ 2549875315 OBDC_Info_El_Req_Data 3;
BA_ "GenSigFuncType" SG_ 2549875315 OBDC_Info_El_Req_Data 9;
BA_ "GenSigSwitchedByIgnition" SG_ 2549875315 OBDC_Info_El_Req_Data 0;
BA_ "GenSigSendType" SG_ 2550006387 OBDC_Info_El_Resp_Data 3;
BA_ "GenSigFuncType" SG_ 2550006387 OBDC_Info_El_Resp_Data 9;
BA_ "GenSigSwitchedByIgnition" SG_ 2550006387 OBDC_Info_El_Resp_Data 0;
BA_ "GenSigSendType" SG_ 2549875312 OBDC_Laufwerke_Req_Data 3;
BA_ "GenSigFuncType" SG_ 2549875312 OBDC_Laufwerke_Req_Data 9;
BA_ "GenSigSwitchedByIgnition" SG_ 2549875312 OBDC_Laufwerke_Req_Data 0;
BA_ "GenSigSendType" SG_ 2550006384 OBDC_Laufwerke_Resp_Data 3;
BA_ "GenSigFuncType" SG_ 2550006384 OBDC_Laufwerke_Resp_Data 9;
BA_ "GenSigSwitchedByIgnition" SG_ 2550006384 OBDC_Laufwerke_Resp_Data 0;
BA_ "GenSigSendType" SG_ 2549875370 OBDC_SCC1_Req_Data 3;
BA_ "GenSigFuncType" SG_ 2549875370 OBDC_SCC1_Req_Data 9;
BA_ "GenSigSwitchedByIgnition" SG_ 2549875370 OBDC_SCC1_Req_Data 0;
BA_ "GenSigSendType" SG_ 2550006442 OBDC_SCC1_Resp_Data 3;
BA_ "GenSigFuncType" SG_ 2550006442 OBDC_SCC1_Resp_Data 9;
BA_ "GenSigSwitchedByIgnition" SG_ 2550006442 OBDC_SCC1_Resp_Data 0;
BA_ "GenSigSendType" SG_ 2549875371 OBDC_SCC2_Req_Data 3;
BA_ "GenSigFuncType" SG_ 2549875371 OBDC_SCC2_Req_Data 9;
BA_ "GenSigSwitchedByIgnition" SG_ 2549875371 OBDC_SCC2_Req_Data 0;
BA_ "GenSigSendType" SG_ 2550006443 OBDC_SCC2_Resp_Data 3;
BA_ "GenSigFuncType" SG_ 2550006443 OBDC_SCC2_Resp_Data 9;
BA_ "GenSigSwitchedByIgnition" SG_ 2550006443 OBDC_SCC2_Resp_Data 0;
BA_ "GenSigSendType" SG_ 2549875367 OBDC_SDC1_Req_Data 3;
BA_ "GenSigFuncType" SG_ 2549875367 OBDC_SDC1_Req_Data 9;
BA_ "GenSigSwitchedByIgnition" SG_ 2549875367 OBDC_SDC1_Req_Data 0;
BA_ "GenSigSendType" SG_ 2550006439 OBDC_SDC1_Resp_Data 3;
BA_ "GenSigFuncType" SG_ 2550006439 OBDC_SDC1_Resp_Data 9;
BA_ "GenSigSwitchedByIgnition" SG_ 2550006439 OBDC_SDC1_Resp_Data 0;
BA_ "GenSigSendType" SG_ 2549875368 OBDC_SDC2_Req_Data 3;
BA_ "GenSigFuncType" SG_ 2549875368 OBDC_SDC2_Req_Data 9;
BA_ "GenSigSwitchedByIgnition" SG_ 2549875368 OBDC_SDC2_Req_Data 0;
BA_ "GenSigSendType" SG_ 2550006440 OBDC_SDC2_Resp_Data 3;
BA_ "GenSigFuncType" SG_ 2550006440 OBDC_SDC2_Resp_Data 9;
BA_ "GenSigSwitchedByIgnition" SG_ 2550006440 OBDC_SDC2_Resp_Data 0;
BA_ "GenSigSendType" SG_ 2549875309 OBDC_TV_Tuner_Req_Data 3;
BA_ "GenSigFuncType" SG_ 2549875309 OBDC_TV_Tuner_Req_Data 9;
BA_ "GenSigSwitchedByIgnition" SG_ 2549875309 OBDC_TV_Tuner_Req_Data 0;
BA_ "GenSigSendType" SG_ 2550006381 OBDC_TV_Tuner_Resp_Data 3;
BA_ "GenSigFuncType" SG_ 2550006381 OBDC_TV_Tuner_Resp_Data 9;
BA_ "GenSigSwitchedByIgnition" SG_ 2550006381 OBDC_TV_Tuner_Resp_Data 0;
BA_ "GenSigSendType" SG_ 2549875365 OBDC_WLC1_Req_Data 3;
BA_ "GenSigFuncType" SG_ 2549875365 OBDC_WLC1_Req_Data 9;
BA_ "GenSigSwitchedByIgnition" SG_ 2549875365 OBDC_WLC1_Req_Data 0;
BA_ "GenSigSendType" SG_ 2550006437 OBDC_WLC1_Resp_Data 3;
BA_ "GenSigFuncType" SG_ 2550006437 OBDC_WLC1_Resp_Data 9;
BA_ "GenSigSwitchedByIgnition" SG_ 2550006437 OBDC_WLC1_Resp_Data 0;
BA_ "GenSigSendType" SG_ 2549875366 OBDC_WLC2_Req_Data 3;
BA_ "GenSigFuncType" SG_ 2549875366 OBDC_WLC2_Req_Data 9;
BA_ "GenSigSwitchedByIgnition" SG_ 2549875366 OBDC_WLC2_Req_Data 0;
BA_ "GenSigSendType" SG_ 2550006438 OBDC_WLC2_Resp_Data 3;
BA_ "GenSigFuncType" SG_ 2550006438 OBDC_WLC2_Resp_Data 9;
BA_ "GenSigSwitchedByIgnition" SG_ 2550006438 OBDC_WLC2_Resp_Data 0;
BA_ "GenSigSendType" SG_ 2589283656 ORU_Status 3;
BA_ "GenSigSwitchedByIgnition" SG_ 2589283656 ORU_Status 0;
BA_ "GenSigSendType" SG_ 2589283656 ORU_Warnung 3;
BA_ "GenSigSwitchedByIgnition" SG_ 2589283656 ORU_Warnung 0;
BA_REL_ "GenSigTimeoutTime" BU_SG_REL_ BedienDisp_vo SG_ 1635 BEM_02_Abschaltstufen 1000;
BA_REL_ "GenSigTimeoutTime" BU_SG_REL_ BedienDisp_vo SG_ 2600468622 NM_BedienDisp_vo_SNI 2000;
BA_REL_ "GenSigTimeoutTime" BU_SG_REL_ BedienDisp_vo SG_ 2600468622 NM_BedienDisp_vo_CBV_CRI 2000;
BA_REL_ "GenSigTimeoutTime" BU_SG_REL_ BedienDisp_vo SG_ 2600468622 NM_BedienDisp_vo_CAB 2000;
BA_REL_ "GenSigTimeoutTime" BU_SG_REL_ BedienDisp_vo SG_ 2600468627 NM_BedienSG_hi_SNI 2000;
BA_REL_ "GenSigTimeoutTime" BU_SG_REL_ BedienDisp_vo SG_ 2600468627 NM_BedienSG_hi_CBV_CRI 2000;
BA_REL_ "GenSigTimeoutTime" BU_SG_REL_ BedienDisp_vo SG_ 2600468627 NM_BedienSG_hi_CAB 2000;
BA_REL_ "GenSigTimeoutTime" BU_SG_REL_ BedienDisp_vo SG_ 2600468666 NM_DDA_SNI 2000;
BA_REL_ "GenSigTimeoutTime" BU_SG_REL_ BedienDisp_vo SG_ 2600468666 NM_DDA_CBV_CRI 2000;
BA_REL_ "GenSigTimeoutTime" BU_SG_REL_ BedienDisp_vo SG_ 2600468666 NM_DDA_CAB 2000;
BA_REL_ "GenSigTimeoutTime" BU_SG_REL_ BedienDisp_vo SG_ 2600468496 NM_Gateway_SNI 2000;
BA_REL_ "GenSigTimeoutTime" BU_SG_REL_ BedienDisp_vo SG_ 2600468496 NM_Gateway_CBV_CRI 2000;
BA_REL_ "GenSigTimeoutTime" BU_SG_REL_ BedienDisp_vo SG_ 2600468496 NM_Gateway_CAB 2000;
BA_REL_ "GenSigTimeoutTime" BU_SG_REL_ BedienDisp_vo SG_ 2600468595 NM_Info_El_SNI 2000;
BA_REL_ "GenSigTimeoutTime" BU_SG_REL_ BedienDisp_vo SG_ 2600468595 NM_Info_El_CBV_CRI 2000;
BA_REL_ "GenSigTimeoutTime" BU_SG_REL_ BedienDisp_vo SG_ 2600468595 NM_Info_El_CAB 2000;
BA_REL_ "GenSigTimeoutTime" BU_SG_REL_ BedienSG_hi SG_ 1635 BEM_02_Abschaltstufen 1000;
BA_REL_ "GenSigTimeoutTime" BU_SG_REL_ BedienSG_hi SG_ 1156 ND_VDOP 2000;
BA_REL_ "GenSigTimeoutTime" BU_SG_REL_ BedienSG_hi SG_ 1156 ND_TDOP 2000;
BA_REL_ "GenSigTimeoutTime" BU_SG_REL_ BedienSG_hi SG_ 1156 ND_HDOP 2000;
BA_REL_ "GenSigTimeoutTime" BU_SG_REL_ BedienSG_hi SG_ 1156 ND_GDOP 2000;
BA_REL_ "GenSigTimeoutTime" BU_SG_REL_ BedienSG_hi SG_ 1156 ND_PDOP 2000;
BA_REL_ "GenSigTimeoutTime" BU_SG_REL_ BedienSG_hi SG_ 1156 ND_Heading 2000;
BA_REL_ "GenSigTimeoutTime" BU_SG_REL_ BedienSG_hi SG_ 1157 ND_SatInUse 2000;
BA_REL_ "GenSigTimeoutTime" BU_SG_REL_ BedienSG_hi SG_ 1157 ND_SatInView 2000;
BA_REL_ "GenSigTimeoutTime" BU_SG_REL_ BedienSG_hi SG_ 1157 NP_Altitude 2000;
BA_REL_ "GenSigTimeoutTime" BU_SG_REL_ BedienSG_hi SG_ 1157 ND_UTC 2000;
BA_REL_ "GenSigTimeoutTime" BU_SG_REL_ BedienSG_hi SG_ 2527679512 ND_Velocity 2000;
BA_REL_ "GenSigTimeoutTime" BU_SG_REL_ BedienSG_hi SG_ 2527679512 ND_RecDelay 2000;
BA_REL_ "GenSigTimeoutTime" BU_SG_REL_ BedienSG_hi SG_ 2527679512 ND_SendDelay 2000;
BA_REL_ "GenSigTimeoutTime" BU_SG_REL_ BedienSG_hi SG_ 2527679512 ND_NrSameMeasure 2000;
BA_REL_ "GenSigTimeoutTime" BU_SG_REL_ BedienSG_hi SG_ 1158 NP_LatDegree 2000;
BA_REL_ "GenSigTimeoutTime" BU_SG_REL_ BedienSG_hi SG_ 1158 NP_LongDegree 2000;
BA_REL_ "GenSigTimeoutTime" BU_SG_REL_ BedienSG_hi SG_ 1158 NP_LatDirection 2000;
BA_REL_ "GenSigTimeoutTime" BU_SG_REL_ BedienSG_hi SG_ 1158 NP_LongDirection 2000;
BA_REL_ "GenSigTimeoutTime" BU_SG_REL_ BedienSG_hi SG_ 1158 NP_Sat 2000;
BA_REL_ "GenSigTimeoutTime" BU_SG_REL_ BedienSG_hi SG_ 1158 NP_Fix 2000;
BA_REL_ "GenSigTimeoutTime" BU_SG_REL_ BedienSG_hi SG_ 2600468622 NM_BedienDisp_vo_SNI 2000;
BA_REL_ "GenSigTimeoutTime" BU_SG_REL_ BedienSG_hi SG_ 2600468622 NM_BedienDisp_vo_CBV_CRI 2000;
BA_REL_ "GenSigTimeoutTime" BU_SG_REL_ BedienSG_hi SG_ 2600468622 NM_BedienDisp_vo_CAB 2000;
BA_REL_ "GenSigTimeoutTime" BU_SG_REL_ BedienSG_hi SG_ 2600468627 NM_BedienSG_hi_SNI 2000;
BA_REL_ "GenSigTimeoutTime" BU_SG_REL_ BedienSG_hi SG_ 2600468627 NM_BedienSG_hi_CBV_CRI 2000;
BA_REL_ "GenSigTimeoutTime" BU_SG_REL_ BedienSG_hi SG_ 2600468627 NM_BedienSG_hi_CAB 2000;
BA_REL_ "GenSigTimeoutTime" BU_SG_REL_ BedienSG_hi SG_ 2600468666 NM_DDA_SNI 2000;
BA_REL_ "GenSigTimeoutTime" BU_SG_REL_ BedienSG_hi SG_ 2600468666 NM_DDA_CBV_CRI 2000;
BA_REL_ "GenSigTimeoutTime" BU_SG_REL_ BedienSG_hi SG_ 2600468666 NM_DDA_CAB 2000;
BA_REL_ "GenSigTimeoutTime" BU_SG_REL_ BedienSG_hi SG_ 2600468496 NM_Gateway_SNI 2000;
BA_REL_ "GenSigTimeoutTime" BU_SG_REL_ BedienSG_hi SG_ 2600468496 NM_Gateway_CBV_CRI 2000;
BA_REL_ "GenSigTimeoutTime" BU_SG_REL_ BedienSG_hi SG_ 2600468496 NM_Gateway_CAB 2000;
BA_REL_ "GenSigTimeoutTime" BU_SG_REL_ BedienSG_hi SG_ 2600468595 NM_Info_El_SNI 2000;
BA_REL_ "GenSigTimeoutTime" BU_SG_REL_ BedienSG_hi SG_ 2600468595 NM_Info_El_CBV_CRI 2000;
BA_REL_ "GenSigTimeoutTime" BU_SG_REL_ BedienSG_hi SG_ 2600468595 NM_Info_El_CAB 2000;
BA_REL_ "GenSigTimeoutTime" BU_SG_REL_ DDA SG_ 1635 BEM_02_Abschaltstufen 1000;
BA_REL_ "GenSigTimeoutTime" BU_SG_REL_ DDA SG_ 283 MO_Fahrbereitschaft 5000;
BA_REL_ "GenSigTimeoutTime" BU_SG_REL_ DDA SG_ 2600468622 NM_BedienDisp_vo_SNI 2000;
BA_REL_ "GenSigTimeoutTime" BU_SG_REL_ DDA SG_ 2600468622 NM_BedienDisp_vo_CBV_CRI 2000;
BA_REL_ "GenSigTimeoutTime" BU_SG_REL_ DDA SG_ 2600468622 NM_BedienDisp_vo_CAB 2000;
BA_REL_ "GenSigTimeoutTime" BU_SG_REL_ DDA SG_ 2600468627 NM_BedienSG_hi_SNI 2000;
BA_REL_ "GenSigTimeoutTime" BU_SG_REL_ DDA SG_ 2600468627 NM_BedienSG_hi_CBV_CRI 2000;
BA_REL_ "GenSigTimeoutTime" BU_SG_REL_ DDA SG_ 2600468627 NM_BedienSG_hi_CAB 2000;
BA_REL_ "GenSigTimeoutTime" BU_SG_REL_ DDA SG_ 2600468496 NM_Gateway_SNI 2000;
BA_REL_ "GenSigTimeoutTime" BU_SG_REL_ DDA SG_ 2600468496 NM_Gateway_CBV_CRI 2000;
BA_REL_ "GenSigTimeoutTime" BU_SG_REL_ DDA SG_ 2600468496 NM_Gateway_CAB 2000;
BA_REL_ "GenSigTimeoutTime" BU_SG_REL_ DDA SG_ 2600468595 NM_Info_El_SNI 2000;
BA_REL_ "GenSigTimeoutTime" BU_SG_REL_ DDA SG_ 2600468595 NM_Info_El_CBV_CRI 2000;
BA_REL_ "GenSigTimeoutTime" BU_SG_REL_ DDA SG_ 2600468595 NM_Info_El_CAB 2000;
BA_REL_ "GenSigTimeoutTime" BU_SG_REL_ Gateway SG_ 1156 ND_VDOP 2000;
BA_REL_ "GenSigTimeoutTime" BU_SG_REL_ Gateway SG_ 1156 ND_TDOP 2000;
BA_REL_ "GenSigTimeoutTime" BU_SG_REL_ Gateway SG_ 1156 ND_HDOP 2000;
BA_REL_ "GenSigTimeoutTime" BU_SG_REL_ Gateway SG_ 1156 ND_GDOP 2000;
BA_REL_ "GenSigTimeoutTime" BU_SG_REL_ Gateway SG_ 1156 ND_PDOP 2000;
BA_REL_ "GenSigTimeoutTime" BU_SG_REL_ Gateway SG_ 1156 ND_Heading 2000;
BA_REL_ "GenSigTimeoutTime" BU_SG_REL_ Gateway SG_ 1156 ND_Init 2000;
BA_REL_ "GenSigTimeoutTime" BU_SG_REL_ Gateway SG_ 1157 ND_SatInUse 2000;
BA_REL_ "GenSigTimeoutTime" BU_SG_REL_ Gateway SG_ 1157 NP_Altitude 2000;
BA_REL_ "GenSigTimeoutTime" BU_SG_REL_ Gateway SG_ 1157 ND_UTC 2000;
BA_REL_ "GenSigTimeoutTime" BU_SG_REL_ Gateway SG_ 2527679512 ND_Timezone_Offset 2000;
BA_REL_ "GenSigTimeoutTime" BU_SG_REL_ Gateway SG_ 2527679512 ND_Timezone_DaylightSavingOffset 2000;
BA_REL_ "GenSigTimeoutTime" BU_SG_REL_ Gateway SG_ 2527679512 ND_Timezone_SignBit 2000;
BA_REL_ "GenSigTimeoutTime" BU_SG_REL_ Gateway SG_ 2527679512 ND_Timezone_Validity 2000;
BA_REL_ "GenSigTimeoutTime" BU_SG_REL_ Gateway SG_ 2527679512 ND_TimeToDestination 2000;
BA_REL_ "GenSigTimeoutTime" BU_SG_REL_ Gateway SG_ 2527679512 ND_RouteType 2000;
BA_REL_ "GenSigTimeoutTime" BU_SG_REL_ Gateway SG_ 2527679512 ND_TimeOffset 2000;
BA_REL_ "GenSigTimeoutTime" BU_SG_REL_ Gateway SG_ 2527679665 ND_Avrg_Speed_RangeData 2000;
BA_REL_ "GenSigTimeoutTime" BU_SG_REL_ Gateway SG_ 1158 NP_LatDegree 2000;
BA_REL_ "GenSigTimeoutTime" BU_SG_REL_ Gateway SG_ 1158 NP_LongDegree 2000;
BA_REL_ "GenSigTimeoutTime" BU_SG_REL_ Gateway SG_ 1158 NP_LatDirection 2000;
BA_REL_ "GenSigTimeoutTime" BU_SG_REL_ Gateway SG_ 1158 NP_LongDirection 2000;
BA_REL_ "GenSigTimeoutTime" BU_SG_REL_ Gateway SG_ 1158 NP_Sat 2000;
BA_REL_ "GenSigTimeoutTime" BU_SG_REL_ Gateway SG_ 1158 NP_Fix 2000;
BA_REL_ "GenSigTimeoutTime" BU_SG_REL_ Gateway SG_ 2589283496 POS_MUX 5000;
BA_REL_ "GenSigTimeoutTime" BU_SG_REL_ Gateway SG_ 2589283496 POS_ODD_EVEN 5000;
BA_REL_ "GenSigTimeoutTime" BU_SG_REL_ Gateway SG_ 2589283496 POS_PosStati 5000;
BA_REL_ "GenSigTimeoutTime" BU_SG_REL_ Gateway SG_ 2589283496 POS_Heading 5000;
BA_REL_ "GenSigTimeoutTime" BU_SG_REL_ Gateway SG_ 2589283496 POS_LatDirection 5000;
BA_REL_ "GenSigTimeoutTime" BU_SG_REL_ Gateway SG_ 2589283496 POS_LatDegree 5000;
BA_REL_ "GenSigTimeoutTime" BU_SG_REL_ Gateway SG_ 2589283496 POS_Last_GPS_Sync 5000;
BA_REL_ "GenSigTimeoutTime" BU_SG_REL_ Gateway SG_ 2589283496 POS_Heading_Trust 5000;
BA_REL_ "GenSigTimeoutTime" BU_SG_REL_ Gateway SG_ 2589283496 POS_UTC_REF 5000;
BA_REL_ "GenSigTimeoutTime" BU_SG_REL_ Gateway SG_ 2589283496 POS_LongDirection 5000;
BA_REL_ "GenSigTimeoutTime" BU_SG_REL_ Gateway SG_ 2589283496 POS_LongDegree 5000;
BA_REL_ "GenSigTimeoutTime" BU_SG_REL_ Gateway SG_ 2600468622 NM_BedienDisp_vo_SNI 2000;
BA_REL_ "GenSigTimeoutTime" BU_SG_REL_ Gateway SG_ 2600468622 NM_BedienDisp_vo_CBV_AWB 2000;
BA_REL_ "GenSigTimeoutTime" BU_SG_REL_ Gateway SG_ 2600468622 NM_BedienDisp_vo_CBV_CRI 2000;
BA_REL_ "GenSigTimeoutTime" BU_SG_REL_ Gateway SG_ 2600468622 NM_BedienDisp_vo_Car_Wakeup 2000;
BA_REL_ "GenSigTimeoutTime" BU_SG_REL_ Gateway SG_ 2600468622 NM_BedienDisp_vo_CAB 2000;
BA_REL_ "GenSigTimeoutTime" BU_SG_REL_ Gateway SG_ 2600468627 NM_BedienSG_hi_SNI 2000;
BA_REL_ "GenSigTimeoutTime" BU_SG_REL_ Gateway SG_ 2600468627 NM_BedienSG_hi_CBV_AWB 2000;
BA_REL_ "GenSigTimeoutTime" BU_SG_REL_ Gateway SG_ 2600468627 NM_BedienSG_hi_CBV_CRI 2000;
BA_REL_ "GenSigTimeoutTime" BU_SG_REL_ Gateway SG_ 2600468627 NM_BedienSG_hi_Car_Wakeup 2000;
BA_REL_ "GenSigTimeoutTime" BU_SG_REL_ Gateway SG_ 2600468627 NM_BedienSG_hi_CAB 2000;
BA_REL_ "GenSigTimeoutTime" BU_SG_REL_ Gateway SG_ 2600468666 NM_DDA_SNI 2000;
BA_REL_ "GenSigTimeoutTime" BU_SG_REL_ Gateway SG_ 2600468666 NM_DDA_CBV_CRI 2000;
BA_REL_ "GenSigTimeoutTime" BU_SG_REL_ Gateway SG_ 2600468666 NM_DDA_Car_Wakeup 2000;
BA_REL_ "GenSigTimeoutTime" BU_SG_REL_ Gateway SG_ 2600468666 NM_DDA_CAB 2000;
BA_REL_ "GenSigTimeoutTime" BU_SG_REL_ Gateway SG_ 2600468595 NM_Info_El_SNI 2000;
BA_REL_ "GenSigTimeoutTime" BU_SG_REL_ Gateway SG_ 2600468595 NM_Info_El_CBV_AWB 2000;
BA_REL_ "GenSigTimeoutTime" BU_SG_REL_ Gateway SG_ 2600468595 NM_Info_El_CBV_CRI 2000;
BA_REL_ "GenSigTimeoutTime" BU_SG_REL_ Gateway SG_ 2600468595 NM_Info_El_Car_Wakeup 2000;
BA_REL_ "GenSigTimeoutTime" BU_SG_REL_ Gateway SG_ 2600468595 NM_Info_El_CAB 2000;
BA_REL_ "GenSigTimeoutTime" BU_SG_REL_ Gateway SG_ 2600468482 NM_Sekundaer_02_SNI 2000;
BA_REL_ "GenSigTimeoutTime" BU_SG_REL_ Gateway SG_ 2600468482 NM_Sekundaer_02_CBV_AWB 2000;
BA_REL_ "GenSigTimeoutTime" BU_SG_REL_ Gateway SG_ 2600468482 NM_Sekundaer_02_Car_Wakeup 2000;
BA_REL_ "GenSigTimeoutTime" BU_SG_REL_ Gateway SG_ 2600468482 NM_Sekundaer_02_CAB 2000;
BA_REL_ "GenSigTimeoutTime" BU_SG_REL_ Gateway_PAG SG_ 1156 ND_VDOP 2000;
BA_REL_ "GenSigTimeoutTime" BU_SG_REL_ Gateway_PAG SG_ 1156 ND_TDOP 2000;
BA_REL_ "GenSigTimeoutTime" BU_SG_REL_ Gateway_PAG SG_ 1156 ND_HDOP 2000;
BA_REL_ "GenSigTimeoutTime" BU_SG_REL_ Gateway_PAG SG_ 1156 ND_GDOP 2000;
BA_REL_ "GenSigTimeoutTime" BU_SG_REL_ Gateway_PAG SG_ 1156 ND_PDOP 2000;
BA_REL_ "GenSigTimeoutTime" BU_SG_REL_ Gateway_PAG SG_ 1156 ND_Heading 2000;
BA_REL_ "GenSigTimeoutTime" BU_SG_REL_ Gateway_PAG SG_ 1156 ND_Init 2000;
BA_REL_ "GenSigTimeoutTime" BU_SG_REL_ Gateway_PAG SG_ 1157 ND_SatInUse 2000;
BA_REL_ "GenSigTimeoutTime" BU_SG_REL_ Gateway_PAG SG_ 1157 NP_Altitude 2000;
BA_REL_ "GenSigTimeoutTime" BU_SG_REL_ Gateway_PAG SG_ 1157 ND_UTC 2000;
BA_REL_ "GenSigTimeoutTime" BU_SG_REL_ Gateway_PAG SG_ 2527679512 ND_Timezone_Offset 2000;
BA_REL_ "GenSigTimeoutTime" BU_SG_REL_ Gateway_PAG SG_ 2527679512 ND_Timezone_DaylightSavingOffset 2000;
BA_REL_ "GenSigTimeoutTime" BU_SG_REL_ Gateway_PAG SG_ 2527679512 ND_Timezone_SignBit 2000;
BA_REL_ "GenSigTimeoutTime" BU_SG_REL_ Gateway_PAG SG_ 2527679512 ND_Timezone_Validity 2000;
BA_REL_ "GenSigTimeoutTime" BU_SG_REL_ Gateway_PAG SG_ 2527679512 ND_TimeToDestination 2000;
BA_REL_ "GenSigTimeoutTime" BU_SG_REL_ Gateway_PAG SG_ 2527679512 ND_RouteType 2000;
BA_REL_ "GenSigTimeoutTime" BU_SG_REL_ Gateway_PAG SG_ 2527679512 ND_TimeOffset 2000;
BA_REL_ "GenSigTimeoutTime" BU_SG_REL_ Gateway_PAG SG_ 2527679665 ND_Avrg_Speed_RangeData 2000;
BA_REL_ "GenSigTimeoutTime" BU_SG_REL_ Gateway_PAG SG_ 1158 NP_LatDegree 2000;
BA_REL_ "GenSigTimeoutTime" BU_SG_REL_ Gateway_PAG SG_ 1158 NP_LongDegree 2000;
BA_REL_ "GenSigTimeoutTime" BU_SG_REL_ Gateway_PAG SG_ 1158 NP_LatDirection 2000;
BA_REL_ "GenSigTimeoutTime" BU_SG_REL_ Gateway_PAG SG_ 1158 NP_LongDirection 2000;
BA_REL_ "GenSigTimeoutTime" BU_SG_REL_ Gateway_PAG SG_ 1158 NP_Sat 2000;
BA_REL_ "GenSigTimeoutTime" BU_SG_REL_ Gateway_PAG SG_ 1158 NP_Fix 2000;
BA_REL_ "GenSigTimeoutTime" BU_SG_REL_ Gateway_PAG SG_ 2589283496 POS_MUX 5000;
BA_REL_ "GenSigTimeoutTime" BU_SG_REL_ Gateway_PAG SG_ 2589283496 POS_ODD_EVEN 5000;
BA_REL_ "GenSigTimeoutTime" BU_SG_REL_ Gateway_PAG SG_ 2589283496 POS_PosStati 5000;
BA_REL_ "GenSigTimeoutTime" BU_SG_REL_ Gateway_PAG SG_ 2589283496 POS_Heading 5000;
BA_REL_ "GenSigTimeoutTime" BU_SG_REL_ Gateway_PAG SG_ 2589283496 POS_LatDirection 5000;
BA_REL_ "GenSigTimeoutTime" BU_SG_REL_ Gateway_PAG SG_ 2589283496 POS_LatDegree 5000;
BA_REL_ "GenSigTimeoutTime" BU_SG_REL_ Gateway_PAG SG_ 2589283496 POS_Last_GPS_Sync 5000;
BA_REL_ "GenSigTimeoutTime" BU_SG_REL_ Gateway_PAG SG_ 2589283496 POS_Heading_Trust 5000;
BA_REL_ "GenSigTimeoutTime" BU_SG_REL_ Gateway_PAG SG_ 2589283496 POS_UTC_REF 5000;
BA_REL_ "GenSigTimeoutTime" BU_SG_REL_ Gateway_PAG SG_ 2589283496 POS_LongDirection 5000;
BA_REL_ "GenSigTimeoutTime" BU_SG_REL_ Gateway_PAG SG_ 2589283496 POS_LongDegree 5000;
BA_REL_ "GenSigTimeoutTime" BU_SG_REL_ Gateway_PAG SG_ 2600468622 NM_BedienDisp_vo_SNI 2000;
BA_REL_ "GenSigTimeoutTime" BU_SG_REL_ Gateway_PAG SG_ 2600468622 NM_BedienDisp_vo_CBV_AWB 2000;
BA_REL_ "GenSigTimeoutTime" BU_SG_REL_ Gateway_PAG SG_ 2600468622 NM_BedienDisp_vo_CBV_CRI 2000;
BA_REL_ "GenSigTimeoutTime" BU_SG_REL_ Gateway_PAG SG_ 2600468622 NM_BedienDisp_vo_Car_Wakeup 2000;
BA_REL_ "GenSigTimeoutTime" BU_SG_REL_ Gateway_PAG SG_ 2600468622 NM_BedienDisp_vo_CAB 2000;
BA_REL_ "GenSigTimeoutTime" BU_SG_REL_ Gateway_PAG SG_ 2600468627 NM_BedienSG_hi_SNI 2000;
BA_REL_ "GenSigTimeoutTime" BU_SG_REL_ Gateway_PAG SG_ 2600468627 NM_BedienSG_hi_CBV_AWB 2000;
BA_REL_ "GenSigTimeoutTime" BU_SG_REL_ Gateway_PAG SG_ 2600468627 NM_BedienSG_hi_CBV_CRI 2000;
BA_REL_ "GenSigTimeoutTime" BU_SG_REL_ Gateway_PAG SG_ 2600468627 NM_BedienSG_hi_Car_Wakeup 2000;
BA_REL_ "GenSigTimeoutTime" BU_SG_REL_ Gateway_PAG SG_ 2600468627 NM_BedienSG_hi_CAB 2000;
BA_REL_ "GenSigTimeoutTime" BU_SG_REL_ Gateway_PAG SG_ 2600468666 NM_DDA_SNI 2000;
BA_REL_ "GenSigTimeoutTime" BU_SG_REL_ Gateway_PAG SG_ 2600468666 NM_DDA_CBV_CRI 2000;
BA_REL_ "GenSigTimeoutTime" BU_SG_REL_ Gateway_PAG SG_ 2600468666 NM_DDA_Car_Wakeup 2000;
BA_REL_ "GenSigTimeoutTime" BU_SG_REL_ Gateway_PAG SG_ 2600468666 NM_DDA_CAB 2000;
BA_REL_ "GenSigTimeoutTime" BU_SG_REL_ Gateway_PAG SG_ 2600468595 NM_Info_El_SNI 2000;
BA_REL_ "GenSigTimeoutTime" BU_SG_REL_ Gateway_PAG SG_ 2600468595 NM_Info_El_CBV_AWB 2000;
BA_REL_ "GenSigTimeoutTime" BU_SG_REL_ Gateway_PAG SG_ 2600468595 NM_Info_El_CBV_CRI 2000;
BA_REL_ "GenSigTimeoutTime" BU_SG_REL_ Gateway_PAG SG_ 2600468595 NM_Info_El_Car_Wakeup 2000;
BA_REL_ "GenSigTimeoutTime" BU_SG_REL_ Gateway_PAG SG_ 2600468595 NM_Info_El_CAB 2000;
BA_REL_ "GenSigTimeoutTime" BU_SG_REL_ Gateway_PAG SG_ 2600468482 NM_Sekundaer_02_SNI 2000;
BA_REL_ "GenSigTimeoutTime" BU_SG_REL_ Gateway_PAG SG_ 2600468482 NM_Sekundaer_02_CBV_AWB 2000;
BA_REL_ "GenSigTimeoutTime" BU_SG_REL_ Gateway_PAG SG_ 2600468482 NM_Sekundaer_02_CBV_CRI 2000;
BA_REL_ "GenSigTimeoutTime" BU_SG_REL_ Gateway_PAG SG_ 2600468482 NM_Sekundaer_02_Car_Wakeup 2000;
BA_REL_ "GenSigTimeoutTime" BU_SG_REL_ Gateway_PAG SG_ 2600468482 NM_Sekundaer_02_CAB 2000;
BA_REL_ "GenSigTimeoutTime" BU_SG_REL_ OTA_FC SG_ 1635 BEM_02_Abschaltstufen 1000;
BA_REL_ "GenSigTimeoutTime" BU_SG_REL_ OTA_FC SG_ 1635 BEM_Ladezustand 1000;
BA_REL_ "GenSigTimeoutTime" BU_SG_REL_ OTA_FC SG_ 1635 NVEM_Freigabe_ORU4 1000;
BA_REL_ "GenSigTimeoutTime" BU_SG_REL_ OTA_FC SG_ 283 MO_Fahrbereitschaft 5000;
BA_REL_ "GenSigTimeoutTime" BU_SG_REL_ OTA_FC SG_ 706 MO_Rekuperationsstufe 4000;
BA_REL_ "GenSigTimeoutTime" BU_SG_REL_ OTA_FC SG_ 305 MO_Zust_Antrieb 1000;
BA_REL_ "GenSigTimeoutTime" BU_SG_REL_ OTA_FC SG_ 1156 ND_HDOP 2000;
BA_REL_ "GenSigTimeoutTime" BU_SG_REL_ OTA_FC SG_ 1156 ND_Heading 2000;
BA_REL_ "GenSigTimeoutTime" BU_SG_REL_ OTA_FC SG_ 1156 ND_Init 2000;
BA_REL_ "GenSigTimeoutTime" BU_SG_REL_ OTA_FC SG_ 1157 NP_Altitude 2000;
BA_REL_ "GenSigTimeoutTime" BU_SG_REL_ OTA_FC SG_ 1158 NP_LatDegree 2000;
BA_REL_ "GenSigTimeoutTime" BU_SG_REL_ OTA_FC SG_ 1158 NP_LongDegree 2000;
BA_REL_ "GenSigTimeoutTime" BU_SG_REL_ OTA_FC SG_ 1158 NP_LatDirection 2000;
BA_REL_ "GenSigTimeoutTime" BU_SG_REL_ OTA_FC SG_ 1158 NP_LongDirection 2000;
BA_REL_ "GenSigTimeoutTime" BU_SG_REL_ OTA_FC SG_ 1158 NP_Sat 2000;
BA_REL_ "GenSigTimeoutTime" BU_SG_REL_ OTA_FC SG_ 1158 NP_Fix 2000;
BA_REL_ "GenSigTimeoutTime" BU_SG_REL_ OTA_FC SG_ 2589283496 POS_MUX 5000;
BA_REL_ "GenSigTimeoutTime" BU_SG_REL_ OTA_FC SG_ 2589283496 POS_ODD_EVEN 5000;
BA_REL_ "GenSigTimeoutTime" BU_SG_REL_ OTA_FC SG_ 2589283496 POS_PosStati 5000;
BA_REL_ "GenSigTimeoutTime" BU_SG_REL_ OTA_FC SG_ 2589283496 POS_Heading 5000;
BA_REL_ "GenSigTimeoutTime" BU_SG_REL_ OTA_FC SG_ 2589283496 POS_LatDirection 5000;
BA_REL_ "GenSigTimeoutTime" BU_SG_REL_ OTA_FC SG_ 2589283496 POS_LatDegree 5000;
BA_REL_ "GenSigTimeoutTime" BU_SG_REL_ OTA_FC SG_ 2589283496 POS_Last_GPS_Sync 5000;
BA_REL_ "GenSigTimeoutTime" BU_SG_REL_ OTA_FC SG_ 2589283496 POS_Heading_Trust 5000;
BA_REL_ "GenSigTimeoutTime" BU_SG_REL_ OTA_FC SG_ 2589283496 POS_UTC_REF 5000;
BA_REL_ "GenSigTimeoutTime" BU_SG_REL_ OTA_FC SG_ 2589283496 POS_LongDirection 5000;
BA_REL_ "GenSigTimeoutTime" BU_SG_REL_ OTA_FC SG_ 2589283496 POS_LongDegree 5000;
BA_REL_ "GenSigTimeoutTime" BU_SG_REL_ OTA_FC SG_ 2600468622 NM_BedienDisp_vo_SNI 2000;
BA_REL_ "GenSigTimeoutTime" BU_SG_REL_ OTA_FC SG_ 2600468622 NM_BedienDisp_vo_CBV_CRI 2000;
BA_REL_ "GenSigTimeoutTime" BU_SG_REL_ OTA_FC SG_ 2600468622 NM_BedienDisp_vo_CAB 2000;
BA_REL_ "GenSigTimeoutTime" BU_SG_REL_ OTA_FC SG_ 2600468627 NM_BedienSG_hi_SNI 2000;
BA_REL_ "GenSigTimeoutTime" BU_SG_REL_ OTA_FC SG_ 2600468627 NM_BedienSG_hi_CBV_CRI 2000;
BA_REL_ "GenSigTimeoutTime" BU_SG_REL_ OTA_FC SG_ 2600468627 NM_BedienSG_hi_CAB 2000;
BA_REL_ "GenSigTimeoutTime" BU_SG_REL_ OTA_FC SG_ 2600468666 NM_DDA_SNI 2000;
BA_REL_ "GenSigTimeoutTime" BU_SG_REL_ OTA_FC SG_ 2600468666 NM_DDA_CBV_CRI 2000;
BA_REL_ "GenSigTimeoutTime" BU_SG_REL_ OTA_FC SG_ 2600468666 NM_DDA_CAB 2000;
BA_REL_ "GenSigTimeoutTime" BU_SG_REL_ OTA_FC SG_ 2600468496 NM_Gateway_SNI 2000;
BA_REL_ "GenSigTimeoutTime" BU_SG_REL_ OTA_FC SG_ 2600468496 NM_Gateway_CBV_CRI 2000;
BA_REL_ "GenSigTimeoutTime" BU_SG_REL_ OTA_FC SG_ 2600468496 NM_Gateway_CAB 2000;
BA_REL_ "GenSigTimeoutTime" BU_SG_REL_ OTA_FC SG_ 2600468595 NM_Info_El_SNI 2000;
BA_REL_ "GenSigTimeoutTime" BU_SG_REL_ OTA_FC SG_ 2600468595 NM_Info_El_CBV_CRI 2000;
BA_REL_ "GenSigTimeoutTime" BU_SG_REL_ OTA_FC SG_ 2600468595 NM_Info_El_CAB 2000;
BA_REL_ "GenSigTimeoutTime" BU_SG_REL_ ZR_High SG_ 1635 BEM_02_Abschaltstufen 1000;
BA_REL_ "GenSigTimeoutTime" BU_SG_REL_ ZR_High SG_ 1635 BEM_MMI_Vorwarnung 1000;
BA_REL_ "GenSigTimeoutTime" BU_SG_REL_ ZR_High SG_ 1635 BEM_Ladezustand 1000;
BA_REL_ "GenSigTimeoutTime" BU_SG_REL_ ZR_High SG_ 1635 BEM_Batteriediagnose 1000;
BA_REL_ "GenSigTimeoutTime" BU_SG_REL_ ZR_High SG_ 1635 BEM_UBDM 1000;
BA_REL_ "GenSigTimeoutTime" BU_SG_REL_ ZR_High SG_ 1635 NVEM_Batterie_Service 1000;
BA_REL_ "GenSigTimeoutTime" BU_SG_REL_ ZR_High SG_ 1635 NVEM_Freigabe_OnlineUpdate 1000;
BA_REL_ "GenSigTimeoutTime" BU_SG_REL_ ZR_High SG_ 283 MO_Krit_Heckobjekt 5000;
BA_REL_ "GenSigTimeoutTime" BU_SG_REL_ ZR_High SG_ 2589283475 SCR_Zustand 5000;
BA_REL_ "GenSigTimeoutTime" BU_SG_REL_ ZR_High SG_ 2589283475 SCR_Retriggersignal 5000;
BA_REL_ "GenSigTimeoutTime" BU_SG_REL_ ZR_High SG_ 2589283475 SCR_Nachfuellmenge_min 5000;
BA_REL_ "GenSigTimeoutTime" BU_SG_REL_ ZR_High SG_ 2589283475 SCR_Nachfuellmenge_max 5000;
BA_REL_ "GenSigTimeoutTime" BU_SG_REL_ ZR_High SG_ 2589283475 SCR_Nachfuellmenge_Einheit 5000;
BA_REL_ "GenSigTimeoutTime" BU_SG_REL_ ZR_High SG_ 2589283475 SCR_Tankvolumen 5000;
BA_REL_ "GenSigTimeoutTime" BU_SG_REL_ ZR_High SG_ 2589283475 SCR_Einheit 5000;
BA_REL_ "GenSigTimeoutTime" BU_SG_REL_ ZR_High SG_ 2589283475 SCR_Fuellstand 5000;
BA_REL_ "GenSigTimeoutTime" BU_SG_REL_ ZR_High SG_ 2589283475 SCR_Restreichweite 5000;
BA_REL_ "GenSigTimeoutTime" BU_SG_REL_ ZR_High SG_ 706 MO_ADR_Status 4000;
BA_REL_ "GenSigTimeoutTime" BU_SG_REL_ ZR_High SG_ 1601 MO_Faktor_Momente_02 5000;
BA_REL_ "GenSigTimeoutTime" BU_SG_REL_ ZR_High SG_ 1601 MO_Hybridfahrzeug 5000;
BA_REL_ "GenSigTimeoutTime" BU_SG_REL_ ZR_High SG_ 1601 MO_Getriebe_Code 5000;
BA_REL_ "GenSigTimeoutTime" BU_SG_REL_ ZR_High SG_ 1601 MO_StartStopp_Codiert 5000;
BA_REL_ "GenSigTimeoutTime" BU_SG_REL_ ZR_High SG_ 1601 MO_Anzahl_Zyl 5000;
BA_REL_ "GenSigTimeoutTime" BU_SG_REL_ ZR_High SG_ 1601 MO_Kraftstoffart 5000;
BA_REL_ "GenSigTimeoutTime" BU_SG_REL_ ZR_High SG_ 1601 MO_Hubraum 5000;
BA_REL_ "GenSigTimeoutTime" BU_SG_REL_ ZR_High SG_ 1601 MO_Ansaugsystem 5000;
BA_REL_ "GenSigTimeoutTime" BU_SG_REL_ ZR_High SG_ 1601 MO_Leistung 5000;
BA_REL_ "GenSigTimeoutTime" BU_SG_REL_ ZR_High SG_ 1601 MO_OBD_Typ 5000;
BA_REL_ "GenSigTimeoutTime" BU_SG_REL_ ZR_High SG_ 1601 MO_DPF_verbaut 5000;
BA_REL_ "GenSigTimeoutTime" BU_SG_REL_ ZR_High SG_ 305 Ladezustand_02 1000;
BA_REL_ "GenSigTimeoutTime" BU_SG_REL_ ZR_High SG_ 305 MO_Powermeter 1000;
BA_REL_ "GenSigTimeoutTime" BU_SG_REL_ ZR_High SG_ 1376 MO_Tankbereitschaft_Status 1600;
BA_REL_ "GenSigTimeoutTime" BU_SG_REL_ ZR_High SG_ 1155 Mo_Powermeter_Grenze 3200;
BA_REL_ "GenSigTimeoutTime" BU_SG_REL_ ZR_High SG_ 2527679647 ZV_auf_NFC 2000;
BA_REL_ "GenSigTimeoutTime" BU_SG_REL_ ZR_High SG_ 2527679647 ZV_zu_NFC 2000;
BA_REL_ "GenSigTimeoutTime" BU_SG_REL_ ZR_High SG_ 2527679647 NFC_Front_Verr_Authorisiert 2000;
BA_REL_ "GenSigTimeoutTime" BU_SG_REL_ ZR_High SG_ 2527679647 NFC_Front_Entr_Authorisiert 2000;
BA_REL_ "GenSigTimeoutTime" BU_SG_REL_ ZR_High SG_ 2527679647 NFC_HD_Verriegelung_Authorisiert 2000;
BA_REL_ "GenSigTimeoutTime" BU_SG_REL_ ZR_High SG_ 2527679647 NFC_HD_Entriegelung_Authorisiert 2000;
BA_REL_ "GenSigTimeoutTime" BU_SG_REL_ ZR_High SG_ 2527679647 NFC_aktiv 2000;
BA_REL_ "GenSigTimeoutTime" BU_SG_REL_ ZR_High SG_ 2527679647 NFC_Laden_unterbrechen 2000;
BA_REL_ "GenSigTimeoutTime" BU_SG_REL_ ZR_High SG_ 2527679647 NFC_FT_Entriegelung_Authorisiert 2000;
BA_REL_ "GenSigTimeoutTime" BU_SG_REL_ ZR_High SG_ 2527679647 NFC_FT_Verriegelung_Authorisiert 2000;
BA_REL_ "GenSigTimeoutTime" BU_SG_REL_ ZR_High SG_ 1696 NV_aktiv 2000;
BA_REL_ "GenSigTimeoutTime" BU_SG_REL_ ZR_High SG_ 1696 NV_Texte 2000;
BA_REL_ "GenSigTimeoutTime" BU_SG_REL_ ZR_High SG_ 1696 NV_Gong 2000;
BA_REL_ "GenSigTimeoutTime" BU_SG_REL_ ZR_High SG_ 1696 NV_Symbol 2000;
BA_REL_ "GenSigTimeoutTime" BU_SG_REL_ ZR_High SG_ 1696 NV_Hinweise 2000;
BA_REL_ "GenSigTimeoutTime" BU_SG_REL_ ZR_High SG_ 1696 NV_Piktogramm_aktiv 2000;
BA_REL_ "GenSigTimeoutTime" BU_SG_REL_ ZR_High SG_ 1696 NV_Akustik_deaktiviert_Icon 2000;
BA_REL_ "GenSigTimeoutTime" BU_SG_REL_ ZR_High SG_ 1696 NV_FGM_deaktiviert_Icon 2000;
BA_REL_ "GenSigTimeoutTime" BU_SG_REL_ ZR_High SG_ 1696 NV_Markierungslicht_links 2000;
BA_REL_ "GenSigTimeoutTime" BU_SG_REL_ ZR_High SG_ 1696 NV_Markierungslicht_rechts 2000;
BA_REL_ "GenSigTimeoutTime" BU_SG_REL_ ZR_High SG_ 1696 NV_Symbol_Tierwarnung 2000;
BA_REL_ "GenSigTimeoutTime" BU_SG_REL_ ZR_High SG_ 1696 NV_Anf_Prefill 2000;
BA_REL_ "GenSigTimeoutTime" BU_SG_REL_ ZR_High SG_ 1696 NV_LED_Leiste 2000;
BA_REL_ "GenSigTimeoutTime" BU_SG_REL_ ZR_High SG_ 2600468622 NM_BedienDisp_vo_SNI 2000;
BA_REL_ "GenSigTimeoutTime" BU_SG_REL_ ZR_High SG_ 2600468622 NM_BedienDisp_vo_CBV_CRI 2000;
BA_REL_ "GenSigTimeoutTime" BU_SG_REL_ ZR_High SG_ 2600468622 NM_BedienDisp_vo_CAB 2000;
BA_REL_ "GenSigTimeoutTime" BU_SG_REL_ ZR_High SG_ 2600468627 NM_BedienSG_hi_SNI 2000;
BA_REL_ "GenSigTimeoutTime" BU_SG_REL_ ZR_High SG_ 2600468627 NM_BedienSG_hi_CBV_CRI 2000;
BA_REL_ "GenSigTimeoutTime" BU_SG_REL_ ZR_High SG_ 2600468627 NM_BedienSG_hi_CAB 2000;
BA_REL_ "GenSigTimeoutTime" BU_SG_REL_ ZR_High SG_ 2600468666 NM_DDA_SNI 2000;
BA_REL_ "GenSigTimeoutTime" BU_SG_REL_ ZR_High SG_ 2600468666 NM_DDA_CBV_CRI 2000;
BA_REL_ "GenSigTimeoutTime" BU_SG_REL_ ZR_High SG_ 2600468666 NM_DDA_CAB 2000;
BA_REL_ "GenSigTimeoutTime" BU_SG_REL_ ZR_High SG_ 2600468496 NM_Gateway_SNI 2000;
BA_REL_ "GenSigTimeoutTime" BU_SG_REL_ ZR_High SG_ 2600468496 NM_Gateway_CBV_CRI 2000;
BA_REL_ "GenSigTimeoutTime" BU_SG_REL_ ZR_High SG_ 2600468496 NM_Gateway_CAB 2000;
BA_REL_ "GenSigTimeoutTime" BU_SG_REL_ ZR_High SG_ 2600468595 NM_Info_El_SNI 2000;
BA_REL_ "GenSigTimeoutTime" BU_SG_REL_ ZR_High SG_ 2600468595 NM_Info_El_CBV_CRI 2000;
BA_REL_ "GenSigTimeoutTime" BU_SG_REL_ ZR_High SG_ 2600468595 NM_Info_El_CAB 2000;
BA_REL_ "GenSigTimeoutTime" BU_SG_REL_ ZR_High SG_ 1377 NV_Obj_Warnung_Fussgaenger 2000;
BA_REL_ "GenSigTimeoutTime" BU_SG_REL_ ZR_High SG_ 913 OBD_Eng_Cool_Temp 5000;
BA_REL_ "GenSigTimeoutTime" BU_SG_REL_ ZR_High SG_ 913 OBD_Abs_Throttle_Pos 5000;
BA_REL_ "GenSigTimeoutTime" BU_SG_REL_ ZR_High SG_ 913 OBD_Abs_Pedal_Pos 5000;
BA_REL_ "GenSigTimeoutTime" BU_SG_REL_ ZR_High SG_ 913 MO_QBit_Aussen_Temp 5000;
BA_REL_ "GenSigTimeoutTime" BU_SG_REL_ ZR_High SG_ 2589283656 ORU_Status 5000;
BA_REL_ "GenSigTimeoutTime" BU_SG_REL_ ZR_LIMU SG_ 1635 BEM_02_Abschaltstufen 1000;
BA_REL_ "GenSigTimeoutTime" BU_SG_REL_ ZR_LIMU SG_ 1635 BEM_STH_Zielzeit 1000;
BA_REL_ "GenSigTimeoutTime" BU_SG_REL_ ZR_LIMU SG_ 1635 BEM_MMI_Vorwarnung 1000;
BA_REL_ "GenSigTimeoutTime" BU_SG_REL_ ZR_LIMU SG_ 1635 NVEM_Anf_SD_schalten 1000;
BA_REL_ "GenSigTimeoutTime" BU_SG_REL_ ZR_LIMU SG_ 1635 BEM_Generatordiagnose 1000;
BA_REL_ "GenSigTimeoutTime" BU_SG_REL_ ZR_LIMU SG_ 1635 BEM_Red_Innengeblaese 1000;
BA_REL_ "GenSigTimeoutTime" BU_SG_REL_ ZR_LIMU SG_ 1635 BEM_STH_Einschaltverbot 1000;
BA_REL_ "GenSigTimeoutTime" BU_SG_REL_ ZR_LIMU SG_ 1635 BEM_HL_Regelung_Status 1000;
BA_REL_ "GenSigTimeoutTime" BU_SG_REL_ ZR_LIMU SG_ 1635 BEM_Ladezustand 1000;
BA_REL_ "GenSigTimeoutTime" BU_SG_REL_ ZR_LIMU SG_ 1635 BEM_Batteriediagnose 1000;
BA_REL_ "GenSigTimeoutTime" BU_SG_REL_ ZR_LIMU SG_ 1635 MIB_Stromsparmodus 1000;
BA_REL_ "GenSigTimeoutTime" BU_SG_REL_ ZR_LIMU SG_ 1635 BEM_REK_aktiv 1000;
BA_REL_ "GenSigTimeoutTime" BU_SG_REL_ ZR_LIMU SG_ 1635 NVEM_Last_Anf 1000;
BA_REL_ "GenSigTimeoutTime" BU_SG_REL_ ZR_LIMU SG_ 1635 BEM_UBDM 1000;
BA_REL_ "GenSigTimeoutTime" BU_SG_REL_ ZR_LIMU SG_ 1635 BEM_UGenSoll 1000;
BA_REL_ "GenSigTimeoutTime" BU_SG_REL_ ZR_LIMU SG_ 1635 BEM_Anf_KL15_schalten 1000;
BA_REL_ "GenSigTimeoutTime" BU_SG_REL_ ZR_LIMU SG_ 1635 NVEM_Batterie_Service 1000;
BA_REL_ "GenSigTimeoutTime" BU_SG_REL_ ZR_LIMU SG_ 1635 NVEM_Freigabe_OnlineUpdate 1000;
BA_REL_ "GenSigTimeoutTime" BU_SG_REL_ ZR_LIMU SG_ 1635 NVEM_Freigabe_ORU4 1000;
BA_REL_ "GenSigTimeoutTime" BU_SG_REL_ ZR_LIMU SG_ 283 MO_Krit_Heckobjekt 5000;
BA_REL_ "GenSigTimeoutTime" BU_SG_REL_ ZR_LIMU SG_ 2589283599 MO_Kilometerstand_Wakeup 5000;
BA_REL_ "GenSigTimeoutTime" BU_SG_REL_ ZR_LIMU SG_ 1601 MO_Faktor_Momente_02 5000;
BA_REL_ "GenSigTimeoutTime" BU_SG_REL_ ZR_LIMU SG_ 305 MO_Powermeter 1000;
BA_REL_ "GenSigTimeoutTime" BU_SG_REL_ ZR_LIMU SG_ 1155 Mo_Powermeter_Grenze 3200;
BA_REL_ "GenSigTimeoutTime" BU_SG_REL_ ZR_LIMU SG_ 2527679647 Stellgliedtest_NFC 2000;
BA_REL_ "GenSigTimeoutTime" BU_SG_REL_ ZR_LIMU SG_ 2527679647 NFC_ESM_aktivieren 2000;
BA_REL_ "GenSigTimeoutTime" BU_SG_REL_ ZR_LIMU SG_ 2527679647 ZV_auf_NFC 2000;
BA_REL_ "GenSigTimeoutTime" BU_SG_REL_ ZR_LIMU SG_ 2527679647 ZV_zu_NFC 2000;
BA_REL_ "GenSigTimeoutTime" BU_SG_REL_ ZR_LIMU SG_ 2527679647 NFC_Front_Verr_Authorisiert 2000;
BA_REL_ "GenSigTimeoutTime" BU_SG_REL_ ZR_LIMU SG_ 2527679647 NFC_Front_Entr_Authorisiert 2000;
BA_REL_ "GenSigTimeoutTime" BU_SG_REL_ ZR_LIMU SG_ 2527679647 NFC_HD_Verriegelung_Authorisiert 2000;
BA_REL_ "GenSigTimeoutTime" BU_SG_REL_ ZR_LIMU SG_ 2527679647 NFC_HD_Entriegelung_Authorisiert 2000;
BA_REL_ "GenSigTimeoutTime" BU_SG_REL_ ZR_LIMU SG_ 2527679647 NFC_aktiv 2000;
BA_REL_ "GenSigTimeoutTime" BU_SG_REL_ ZR_LIMU SG_ 2527679647 NFC_Laden_unterbrechen 2000;
BA_REL_ "GenSigTimeoutTime" BU_SG_REL_ ZR_LIMU SG_ 2527679647 NFC_FT_Entriegelung_Authorisiert 2000;
BA_REL_ "GenSigTimeoutTime" BU_SG_REL_ ZR_LIMU SG_ 2527679647 NFC_FT_Verriegelung_Authorisiert 2000;
BA_REL_ "GenSigTimeoutTime" BU_SG_REL_ ZR_LIMU SG_ 2527679645 NFC_MiKo_Fehler 2000;
BA_REL_ "GenSigTimeoutTime" BU_SG_REL_ ZR_LIMU SG_ 2527679645 NFC_MiKo_NFC_Device_gekoppelt 2000;
BA_REL_ "GenSigTimeoutTime" BU_SG_REL_ ZR_LIMU SG_ 2527679645 NFC_MiKo_Laden_unterbrechen 2000;
BA_REL_ "GenSigTimeoutTime" BU_SG_REL_ ZR_LIMU SG_ 2527679645 NFC_MiKo_ESM_aktiv 2000;
BA_REL_ "GenSigTimeoutTime" BU_SG_REL_ ZR_LIMU SG_ 2600468622 NM_BedienDisp_vo_SNI 2000;
BA_REL_ "GenSigTimeoutTime" BU_SG_REL_ ZR_LIMU SG_ 2600468622 NM_BedienDisp_vo_CBV_CRI 2000;
BA_REL_ "GenSigTimeoutTime" BU_SG_REL_ ZR_LIMU SG_ 2600468622 NM_BedienDisp_vo_CAB 2000;
BA_REL_ "GenSigTimeoutTime" BU_SG_REL_ ZR_LIMU SG_ 2600468627 NM_BedienSG_hi_SNI 2000;
BA_REL_ "GenSigTimeoutTime" BU_SG_REL_ ZR_LIMU SG_ 2600468627 NM_BedienSG_hi_CBV_CRI 2000;
BA_REL_ "GenSigTimeoutTime" BU_SG_REL_ ZR_LIMU SG_ 2600468627 NM_BedienSG_hi_CAB 2000;
BA_REL_ "GenSigTimeoutTime" BU_SG_REL_ ZR_LIMU SG_ 2600468666 NM_DDA_SNI 2000;
BA_REL_ "GenSigTimeoutTime" BU_SG_REL_ ZR_LIMU SG_ 2600468666 NM_DDA_CBV_CRI 2000;
BA_REL_ "GenSigTimeoutTime" BU_SG_REL_ ZR_LIMU SG_ 2600468666 NM_DDA_CAB 2000;
BA_REL_ "GenSigTimeoutTime" BU_SG_REL_ ZR_LIMU SG_ 2600468496 NM_Gateway_SNI 2000;
BA_REL_ "GenSigTimeoutTime" BU_SG_REL_ ZR_LIMU SG_ 2600468496 NM_Gateway_CBV_CRI 2000;
BA_REL_ "GenSigTimeoutTime" BU_SG_REL_ ZR_LIMU SG_ 2600468496 NM_Gateway_CAB 2000;
BA_REL_ "GenSigTimeoutTime" BU_SG_REL_ ZR_LIMU SG_ 2600468595 NM_Info_El_SNI 2000;
BA_REL_ "GenSigTimeoutTime" BU_SG_REL_ ZR_LIMU SG_ 2600468595 NM_Info_El_CBV_CRI 2000;
BA_REL_ "GenSigTimeoutTime" BU_SG_REL_ ZR_LIMU SG_ 2600468595 NM_Info_El_CAB 2000;
BA_REL_ "GenSigTimeoutTime" BU_SG_REL_ ZR_LIMU SG_ 2589283656 ORU_Status 5000;
BA_REL_ "GenSigTimeoutTime" BU_SG_REL_ ZR_MIB_TOP_ab_Gen3 SG_ 1635 BEM_02_Abschaltstufen 1000;
BA_REL_ "GenSigTimeoutTime" BU_SG_REL_ ZR_MIB_TOP_ab_Gen3 SG_ 1635 BEM_MMI_Vorwarnung 1000;
BA_REL_ "GenSigTimeoutTime" BU_SG_REL_ ZR_MIB_TOP_ab_Gen3 SG_ 1635 BEM_HL_Regelung_Status 1000;
BA_REL_ "GenSigTimeoutTime" BU_SG_REL_ ZR_MIB_TOP_ab_Gen3 SG_ 1635 BEM_UBDM 1000;
BA_REL_ "GenSigTimeoutTime" BU_SG_REL_ ZR_MIB_TOP_ab_Gen3 SG_ 1635 NVEM_Freigabe_OnlineUpdate 1000;
BA_REL_ "GenSigTimeoutTime" BU_SG_REL_ ZR_MIB_TOP_ab_Gen3 SG_ 283 MO_Krit_Heckobjekt 5000;
BA_REL_ "GenSigTimeoutTime" BU_SG_REL_ ZR_MIB_TOP_ab_Gen3 SG_ 706 MO_Rekuperationsstufe 4000;
BA_REL_ "GenSigTimeoutTime" BU_SG_REL_ ZR_MIB_TOP_ab_Gen3 SG_ 1601 MO_Faktor_Momente_02 5000;
BA_REL_ "GenSigTimeoutTime" BU_SG_REL_ ZR_MIB_TOP_ab_Gen3 SG_ 305 MO_ePowermeter 1000;
BA_REL_ "GenSigTimeoutTime" BU_SG_REL_ ZR_MIB_TOP_ab_Gen3 SG_ 305 MO_Powermeter 1000;
BA_REL_ "GenSigTimeoutTime" BU_SG_REL_ ZR_MIB_TOP_ab_Gen3 SG_ 1155 Mo_Powermeter_Grenze 3200;
BA_REL_ "GenSigTimeoutTime" BU_SG_REL_ ZR_MIB_TOP_ab_Gen3 SG_ 1155 MO_Powermeter_Charge_Grenze 3200;
BA_REL_ "GenSigTimeoutTime" BU_SG_REL_ ZR_MIB_TOP_ab_Gen3 SG_ 2600468622 NM_BedienDisp_vo_SNI 2000;
BA_REL_ "GenSigTimeoutTime" BU_SG_REL_ ZR_MIB_TOP_ab_Gen3 SG_ 2600468622 NM_BedienDisp_vo_CBV_CRI 2000;
BA_REL_ "GenSigTimeoutTime" BU_SG_REL_ ZR_MIB_TOP_ab_Gen3 SG_ 2600468622 NM_BedienDisp_vo_CAB 2000;
BA_REL_ "GenSigTimeoutTime" BU_SG_REL_ ZR_MIB_TOP_ab_Gen3 SG_ 2600468627 NM_BedienSG_hi_SNI 2000;
BA_REL_ "GenSigTimeoutTime" BU_SG_REL_ ZR_MIB_TOP_ab_Gen3 SG_ 2600468627 NM_BedienSG_hi_CBV_CRI 2000;
BA_REL_ "GenSigTimeoutTime" BU_SG_REL_ ZR_MIB_TOP_ab_Gen3 SG_ 2600468627 NM_BedienSG_hi_CAB 2000;
BA_REL_ "GenSigTimeoutTime" BU_SG_REL_ ZR_MIB_TOP_ab_Gen3 SG_ 2600468666 NM_DDA_SNI 2000;
BA_REL_ "GenSigTimeoutTime" BU_SG_REL_ ZR_MIB_TOP_ab_Gen3 SG_ 2600468666 NM_DDA_CBV_CRI 2000;
BA_REL_ "GenSigTimeoutTime" BU_SG_REL_ ZR_MIB_TOP_ab_Gen3 SG_ 2600468666 NM_DDA_CAB 2000;
BA_REL_ "GenSigTimeoutTime" BU_SG_REL_ ZR_MIB_TOP_ab_Gen3 SG_ 2600468496 NM_Gateway_SNI 2000;
BA_REL_ "GenSigTimeoutTime" BU_SG_REL_ ZR_MIB_TOP_ab_Gen3 SG_ 2600468496 NM_Gateway_CBV_CRI 2000;
BA_REL_ "GenSigTimeoutTime" BU_SG_REL_ ZR_MIB_TOP_ab_Gen3 SG_ 2600468496 NM_Gateway_CAB 2000;
BA_REL_ "GenSigTimeoutTime" BU_SG_REL_ ZR_MIB_TOP_ab_Gen3 SG_ 2600468595 NM_Info_El_SNI 2000;
BA_REL_ "GenSigTimeoutTime" BU_SG_REL_ ZR_MIB_TOP_ab_Gen3 SG_ 2600468595 NM_Info_El_CBV_CRI 2000;
BA_REL_ "GenSigTimeoutTime" BU_SG_REL_ ZR_MIB_TOP_ab_Gen3 SG_ 2600468595 NM_Info_El_CAB 2000;
BA_REL_ "GenSigTimeoutTime" BU_SG_REL_ ZR_MIB_TOP_ab_Gen3 SG_ 913 OBD_Driving_Cycle 5000;
BA_REL_ "GenSigTimeoutTime" BU_SG_REL_ ZR_MIB_TOP_ab_Gen3 SG_ 2589283656 ORU_Status 5000;
BA_REL_ "GenSigTimeoutTime" BU_SG_REL_ ZR_Standard SG_ 1635 BEM_02_Abschaltstufen 1000;
BA_REL_ "GenSigTimeoutTime" BU_SG_REL_ ZR_Standard SG_ 1635 BEM_MMI_Vorwarnung 1000;
BA_REL_ "GenSigTimeoutTime" BU_SG_REL_ ZR_Standard SG_ 1635 BEM_Ladezustand 1000;
BA_REL_ "GenSigTimeoutTime" BU_SG_REL_ ZR_Standard SG_ 1635 BEM_UBDM 1000;
BA_REL_ "GenSigTimeoutTime" BU_SG_REL_ ZR_Standard SG_ 1635 NVEM_Freigabe_OnlineUpdate 1000;
BA_REL_ "GenSigTimeoutTime" BU_SG_REL_ ZR_Standard SG_ 2589283475 SCR_Zustand 5000;
BA_REL_ "GenSigTimeoutTime" BU_SG_REL_ ZR_Standard SG_ 2589283475 SCR_Retriggersignal 5000;
BA_REL_ "GenSigTimeoutTime" BU_SG_REL_ ZR_Standard SG_ 2589283475 SCR_Nachfuellmenge_min 5000;
BA_REL_ "GenSigTimeoutTime" BU_SG_REL_ ZR_Standard SG_ 2589283475 SCR_Nachfuellmenge_max 5000;
BA_REL_ "GenSigTimeoutTime" BU_SG_REL_ ZR_Standard SG_ 2589283475 SCR_Nachfuellmenge_Einheit 5000;
BA_REL_ "GenSigTimeoutTime" BU_SG_REL_ ZR_Standard SG_ 2589283475 SCR_Tankvolumen 5000;
BA_REL_ "GenSigTimeoutTime" BU_SG_REL_ ZR_Standard SG_ 2589283475 SCR_Einheit 5000;
BA_REL_ "GenSigTimeoutTime" BU_SG_REL_ ZR_Standard SG_ 2589283475 SCR_Fuellstand 5000;
BA_REL_ "GenSigTimeoutTime" BU_SG_REL_ ZR_Standard SG_ 2589283475 SCR_Restreichweite 5000;
BA_REL_ "GenSigTimeoutTime" BU_SG_REL_ ZR_Standard SG_ 1601 MO_Faktor_Momente_02 5000;
BA_REL_ "GenSigTimeoutTime" BU_SG_REL_ ZR_Standard SG_ 1601 MO_Getriebe_Code 5000;
BA_REL_ "GenSigTimeoutTime" BU_SG_REL_ ZR_Standard SG_ 1601 MO_Kraftstoffart 5000;
BA_REL_ "GenSigTimeoutTime" BU_SG_REL_ ZR_Standard SG_ 305 MO_Powermeter 1000;
BA_REL_ "GenSigTimeoutTime" BU_SG_REL_ ZR_Standard SG_ 2600468622 NM_BedienDisp_vo_SNI 2000;
BA_REL_ "GenSigTimeoutTime" BU_SG_REL_ ZR_Standard SG_ 2600468622 NM_BedienDisp_vo_CBV_CRI 2000;
BA_REL_ "GenSigTimeoutTime" BU_SG_REL_ ZR_Standard SG_ 2600468622 NM_BedienDisp_vo_CAB 2000;
BA_REL_ "GenSigTimeoutTime" BU_SG_REL_ ZR_Standard SG_ 2600468627 NM_BedienSG_hi_SNI 2000;
BA_REL_ "GenSigTimeoutTime" BU_SG_REL_ ZR_Standard SG_ 2600468627 NM_BedienSG_hi_CBV_CRI 2000;
BA_REL_ "GenSigTimeoutTime" BU_SG_REL_ ZR_Standard SG_ 2600468627 NM_BedienSG_hi_CAB 2000;
BA_REL_ "GenSigTimeoutTime" BU_SG_REL_ ZR_Standard SG_ 2600468666 NM_DDA_SNI 2000;
BA_REL_ "GenSigTimeoutTime" BU_SG_REL_ ZR_Standard SG_ 2600468666 NM_DDA_CBV_CRI 2000;
BA_REL_ "GenSigTimeoutTime" BU_SG_REL_ ZR_Standard SG_ 2600468666 NM_DDA_CAB 2000;
BA_REL_ "GenSigTimeoutTime" BU_SG_REL_ ZR_Standard SG_ 2600468496 NM_Gateway_SNI 2000;
BA_REL_ "GenSigTimeoutTime" BU_SG_REL_ ZR_Standard SG_ 2600468496 NM_Gateway_CBV_CRI 2000;
BA_REL_ "GenSigTimeoutTime" BU_SG_REL_ ZR_Standard SG_ 2600468496 NM_Gateway_CAB 2000;
BA_REL_ "GenSigTimeoutTime" BU_SG_REL_ ZR_Standard SG_ 2600468595 NM_Info_El_SNI 2000;
BA_REL_ "GenSigTimeoutTime" BU_SG_REL_ ZR_Standard SG_ 2600468595 NM_Info_El_CBV_CRI 2000;
BA_REL_ "GenSigTimeoutTime" BU_SG_REL_ ZR_Standard SG_ 2600468595 NM_Info_El_CAB 2000;
VAL_ 283 MO_Fahrbereitschaft 0 "Fahrzykl_inaktiv__kein_Antrieb" 1 "Fahrzykl_aktiv__kein_Antrieb" 2 "Fahrzykl_aktiv__Antrieb_moeglich" ;
VAL_ 283 MO_Freilauf_Info 0 "Freilauf_freigegeben" 1 "Weiches_Veto_uebertippbar" 2 "Hartes_Veto_Abbruch" 3 "Freilauf_Anforderung" ;
VAL_ 283 MO_Krit_Heckobjekt 0 "Init_kein_relevantes_Objekt" 1 "Entfernung_grosser_Abstand" 2 "Annaeherung_grosser_Abstand" 3 "Entfernung_geringer_Abstand" 4 "Annaeherung_geringer_Abstand" 7 "Fehler" ;
VAL_ 283 MO_NGS_Gangpos 0 "nicht_bedient" 1 "1_3_oder_5" 2 "2_4_6_oder_R" 3 "R" 4 "Neutralposition" 5 "Zwischenposition" 6 "Sensor_temp_nicht_verfuegbar" 7 "Fehler" ;
VAL_ 283 MO_Freilauf_Status 0 "Freilauf_inaktiv_aber_moeglich" 1 "Freilauf_aktiv" 2 "Freilauf_nicht_moegl_1Verhinderer" 3 "Freilauf_nicht_moegl_gr_1Verhinderer" 7 "Fehler" ;
VAL_ 283 MO_EBoost_verf_praed 0 "Init_oder_nicht_verfuegbar" 1 "EBoost_kurzzeit_verfuegbar" 2 "EBoost_langzeit_verfuegbar" ;
VAL_ 283 MO_Heckspoiler_Anf 0 "nicht_angefordert" 1 "angefordert" ;
VAL_ 283 MO_eLaunch_verf 0 "Init" 1 "nicht_verfuegbar" 2 "verfuegbar" ;
VAL_ 283 MO_Positionierung_aktiv 0 "keine_Positionierung_aktiv" 1 "Positionierung_aktiv" ;
VAL_ 283 MO_Parken_WFS_Status 0 "Limitierung_Inaktiv" 1 "Limitierung_Aktiv" 2 "Abbruch" ;
VAL_ 283 MO_Status_Katheizen 0 "Katheizen_nicht_aktiv" 1 "Katheizen_aktiv" ;
VAL_ 283 MO_Status_MIN_Wunschdrehzahl 0 "keine_OBD_oder_CSERS_Anforderung" 1 "CSERS_Anforderung" 2 "OBD_Anforderung_ausserhalb_CSERS" 3 "reserviert" ;
VAL_ 283 MO_Rennstart_verf 0 "nicht_verfuegbar" 1 "verfuegbar" ;
VAL_ 283 MO_AIAD_MaxLeistung 255 "Init" ;
VAL_ 2589283475 SCR_Zustand 0 "Initialisierung" 1 "Normale_Funktion" 2 "Hinweis_Fuellstand" 3 "Warnstufe_1" 4 "Warnstufe_2" 5 "Systemfehler_1" 6 "Systemfehler_2" 7 "Schraeglage" 8 "Gefrorenes_Medium" 9 "Keine_RRW_Anzeige" 10 "AdBlue_pruefen_RRW_deaktiv" 11 "AdBlue_pruefen_RRW_aktiv" 12 "reserved" 13 "reserved" 14 "reserved" 15 "reserved" ;
VAL_ 2589283475 SCR_Retriggersignal 0 "Retrigger_nicht_aktiv" 1 "Retrigger_aktiv" ;
VAL_ 2589283475 SCR_Nachfuellmenge_min 127 "Initwert" ;
VAL_ 2589283475 SCR_Nachfuellmenge_max 255 "Initwert" ;
VAL_ 2589283475 SCR_Nachfuellmenge_Einheit 0 "Liter" 1 "Gallone (US)" 2 "Gallone (UK)" 3 "reserved" ;
VAL_ 2589283475 SCR_Einheit 0 "km" 1 "miles" ;
VAL_ 2589283475 SCR_Fuellstand 127 "Initwert" ;
VAL_ 706 MO_Anzeige_StSt_Text 0 "keine_Anzeige" 1 "Systemfehler" 2 "Motor_manuell_starten" 3 "Rueckmeldung_durch_Fahrstufe_einlegen" 4 "Zuendungsabschaltwarnung_Timerstart" 5 "Zum_Motorstart_Bremse_treten" 6 "StSt_Aktivierung_nicht_moeglich_auf_Grund_Fahrprogramm" ;
VAL_ 706 MO_Anzeige_StSt_Symbol 0 "keine_Anzeige" 1 "StSt_aktiv" 2 "Motorlauf_noetig" 3 "Fahrer_temporaer_abwesend" 4 "Fahrer_vielleicht_anwesend" ;
VAL_ 706 MO_ADR_Status 0 "nicht_aktiv" 1 "ADR_angefordert" 2 "ADR_aktiv" 3 "ADR_Fehler" ;
VAL_ 706 MO_AGA_Sound_Texte 0 "keine_Anzeige" 1 "Sound_off" 2 "Sound_on" ;
VAL_ 706 MO_Anzeige_FMAus_Text 0 "keine_Anzeige" 1 "FMAus_Systemfehler" ;
VAL_ 706 MO_Fehler_MSpG 0 "i.O." 1 "Gebläse defekt oder Motorraumtemp. zu hoch" ;
VAL_ 706 PEA_Texte 0 "Keine_Anzeige" 1 "PEA_Fahreruebernahme_noetig" 2 "PEA_Reku_nicht_verfuegbar" ;
VAL_ 706 TSK_Ueberstimmt_vMax_FahrerInfo 0 "nicht_ueberstimmbar" 1 "ueberstimmbar" 2 "ueberstimmt" ;
VAL_ 706 MO_Avus_Motorschutz 0 "keine Warnung" 1 "Drehzahlwarnung Stufe 1" 2 "Drehzahlwarnung Stufe 2" 3 "Drehzahlwarnung Stufe 3" ;
VAL_ 706 MO_Rekuperationsstufe 0 "keine_Anzeige" 1 "Rekuperationsstufe_1" 2 "Rekuperationsstufe_2" 3 "Rekuperationsstufe_3" 4 "Rekuperationsstufe_4" 5 "Rekuperationsstufe_5" 6 "Rekuperationsstufe_auto" 7 "Init" ;
VAL_ 706 TSK_Einheit_vMax_FahrerInfo 0 "km_h" 1 "mph" ;
VAL_ 706 TSK_Status_vMax_FahrerInfo 0 "keine_Anzeige" 1 "Anzeige_im_Fahrzeugstatus" 2 "PopUp_ohne_Gong__Eintrag_FhzStat" 3 "PopUp_mit_Gong__Eintrag_FhzStat" ;
VAL_ 706 MO_Red_Fahrleistung 0 "keine_Anzeige" 1 "kleine_Red" 2 "mittlere_Red_temp" 3 "mittlere_Red" 4 "grosse_Red_temp" 5 "grosse_Red" ;
VAL_ 706 MO_Oel_Temp_Radsatz_Warn 0 "iO_Temperatur" 1 "Uebertemperatur_Warnung" ;
VAL_ 706 MO_Anz_Kuehlerluefter 0 "Kein_KuehlerluefterNachlauf" 1 "Text_Luefternachlauf_aktiv" 2 "Text_Luefternachlauf_DPF_aktiv" 3 "Platzhalter_weitere_Signale" 4 "Platzhalter_weitere_Signale" 5 "Platzhalter_weitere_Signale" 6 "Platzhalter_weitere_Signale" 7 "Platzhalter_weitere_Signale" ;
VAL_ 706 MO_im_Leerlauf 0 "nicht_im_Leerlauf" 1 "im_Leerlauf" ;
VAL_ 706 WIV_Enable_Oeldr_Motor 0 "Oeldruckauswertung_im_Kombi" 1 "Oeldruckauswertung_im_MSG" ;
VAL_ 706 MO_OelMessung_Dauer 15 "keine_Messung_aktiv" ;
VAL_ 706 TSK_vMax_FahrerInfo 0 "Init___kein_Wert" ;
VAL_ 2589283599 MO_Kilometerstand_Wakeup 1048574 "Init" 1048575 "Fehler" ;
VAL_ 2589283599 MO_Status_KL 0 "Kein_fehler" 1 "Fehler_KL_3" 2 "Fehler_KL_4" 3 "Fehler_KL_3_und_KL_4" ;
VAL_ 2589283599 MO_Eboost_LB_LVLavailable 0 "init" 1 "LB_eboost_level_1_available" 2 "LB_eboost_level_1_2_available" 3 "LB_eboost_level_1_2_3_available" ;
VAL_ 2589283599 MO_Eboost_LB_possible 0 "LB_eboost_not_possible" 1 "LB_eboost_possible" ;
VAL_ 2589283599 MO_Eboost_LB_active 0 "LB_eboost_not_active" 1 "LB_eboost_active" ;
VAL_ 2589283599 MO_Eboost_LB_available 0 "LB_eboost_not_available" 1 "LB_eboost_available" ;
VAL_ 2589283599 MO_Eboost_LB_driveraction 0 "init" 1 "change_DM_PS" 2 "press_accelerator" 3 "ready" ;
VAL_ 2589283599 MO_Eboost_LB_failure 0 "no_failure" 1 "failure" ;
VAL_ 2589283599 MO_Eboost_LB_LVLselected 0 "init" 1 "LB_eboost_level_1_selected" 2 "LB_eboost_level_2_selected" 3 "LB_eboost_level_3_selected" ;
VAL_ 1601 MO_Faktor_Momente_02 0 "nicht_belegt" ;
VAL_ 1601 MO_Hybridfahrzeug 0 "kein_Hybridfahrzeug" 1 "Mild_Hybrid" 2 "Full_Hybrid" 3 "PlugIn_Hybrid" ;
VAL_ 1601 MO_Getriebe_Code 0 "Init" 2 "DL501" 3 "DL800" 4 "VL381" 5 "DL382_Front" 6 "DL382_Allrad" 7 "DL702" 8 "AL552_Allrad" 9 "AL552_Front" 10 "AL651" 11 "AL551__AL951__AL1000_8A" 12 "PDK_PAG" 13 "AL551_Hybrid" 15 "Handschalter_konventionell" 16 "AQ250_160" 17 "AQ450" 18 "DQ200" 19 "DQ250" 20 "DQ500" 21 "SQ100" 22 "SQ200" 23 "DQ400E" 24 "DQ381" 25 "AL550" 26 "AQ300" 31 "DL800E" 32 "Single_Gear__ohne_GSG_WH_am_MSG" 33 "EQ550_2P" ;
VAL_ 1601 MO_StartStopp_Codiert 0 "Start_Stopp_nicht_verbaut" 1 "Start_Stopp_verbaut" ;
VAL_ 1601 MO_Anzeige_StSt_gueltig 0 "MO_Text_Motorstart_gueltig" 1 "Signale_MO_Anzeige_StSt_gueltig" ;
VAL_ 1601 MO_Anzahl_Zyl 0 "kein_Zylinder" 1 "1_Zylinder" 2 "2_Zylinder" 3 "3_Zylinder" 4 "4_Zylinder" 5 "5_Zylinder" 6 "6_Zylinder" 7 "7_Zylinder" 8 "8_Zylinder" 9 "9_Zylinder" 10 "10_Zylinder" 11 "11_Zylinder" 12 "12_Zylinder" 13 "15_Zylinder" 14 "16_Zylinder" 15 "18_Zylinder" ;
VAL_ 1601 MO_Kraftstoffart 0 "Diesel" 1 "Benzin_inkl_E25_E85" 2 "CNG" 3 "LPG" 4 "Wasserstoff" 5 "E100_Ethanol" 15 "kein_Verbrennungskraftstoff" ;
VAL_ 1601 MO_Ansaugsystem 0 "Turbo" 1 "Sauger" ;
VAL_ 1601 MO_OBD_Typ 0 "NoOBD_RdW" 1 "EOBD" 2 "US_OBD" 3 "reserviert" ;
VAL_ 1601 MO_DPF_verbaut 0 "kein_DPF_verbaut" 1 "DPF_verbaut" ;
VAL_ 1601 TSK_Codierung 0 "kein_Fahrgeschwindigkeitsregler" 1 "GRA" 2 "GRA_Plus" 3 "Basis_ACC" 4 "ACC_Follow_to_Stop" 5 "ACC_Stop_and_Go" 7 "Codierung_in_Plausibilisierungsphase" ;
VAL_ 305 MO_ePowermeter 0 "Init_keine_Anzeige" 254 "Funktion_deaktiv_Anzeige_ausgegraut" 255 "Fehler_keine_Anzeige" ;
VAL_ 305 MO_ePerformance 0 "Init" 254 "Funktion_deaktiv_Anz_ausgegraut" 255 "Fehler" ;
VAL_ 305 MO_Zust_Antrieb 0 "VM bzw. Brennstoffz. aktiv" 1 "EM aktiv" 2 "VM bzw. Brennstoffz. u. EM aktiv" 3 "Segeln oder Reku aktiv" ;
VAL_ 305 MO_Zust_Betriebsstrategie 0 "Kein Hybrid" 1 "Depleting" 2 "Soft-Depleting " 3 "Sustaining" 4 "Increasing" 5 "Fremdgesteuert" ;
VAL_ 305 Ladezustand_02 254 "Init" 255 "Fehler" ;
VAL_ 305 MO_Powermeter_Elm_02 0 "nicht_verbaut" 4094 "Init" ;
VAL_ 305 MO_Powermeter 4093 "Off" ;
VAL_ 1376 MO_HV_Spannungsfreiheit 0 "HV_System_nicht_spannungsfrei" 1 "frei" 2 "frei" 3 "HV_System_spannungsfrei" ;
VAL_ 1376 MO_Gesamtst_Spgfreiheit 0 "Init" 1 "HV_Komponente_spannungsfrei" 2 "HV_Komp_nicht_spannungsfrei" 3 "Fehler_nicht_spannungsfrei" ;
VAL_ 1376 MO_Tankbereitschaft_Status 0 "keine_Aktion_Init" 1 "Tankbereitschaft_wird_hergestellt" 2 "Tankbereitschaft_ist_hergestellt" 3 "Tankbereitschaft_kann_nicht_hergestellt_werden" 4 "Tanksystem_Systemfehler" 5 "Tankklappe_pruefen_schliessen" 6 "Tankvorgang_abgebrochen" ;
VAL_ 1376 MO_HYB_Status_Betriebsstrategie 0 "Init" 1 "Aktiv" 2 "Passiv_VKM_Ein" 3 "Passiv_VKM_Aus__HV_Verbraucher_Aus" 4 "Passiv_VKM_Aus__HV_Verbraucher_Ein" ;
VAL_ 1155 Mo_Powermeter_Grenze 4093 "OFF" ;
VAL_ 1155 MO_Text_Aktivierung_Antrieb 0 "keine_Anzeige" 1 "Ladestecker_nicht_fahrbereit" 2 "erneute_Aktivierung_erforderlich" 3 "Warten_Antrieb_wird_aktiviert" 4 "zum_Fahren_Bremse_und_Fahrstufe" 5 "h2_Tankklappe_nicht_fahrbereit" 6 "zum_Starten_Bremse_treten" 7 "zum_Starten_Kupplung_treten" 15 "Init" ;
VAL_ 1155 MO_Powermeter_Inszenierung_aktiv 0 "keine_Anzeige" 1 "Inszenierung_aktiv" ;
VAL_ 1155 MO_Powermeter_Charge_Grenze 1022 "Init" 1023 "Fehler" ;
VAL_ 1155 MO_Powermeter_Grenze_strategisch 4094 "Init" 4095 "Fehler" ;
VAL_ 1155 MO_Powermeter_untere_E_Grenze 4094 "Init" 4095 "Fehler" ;
VAL_ 1155 MO_Powermeter_obere_E_Grenze 4094 "Init" 4095 "Fehler" ;
VAL_ 1156 ND_VDOP 1022 "Init" 1023 "Fehler" ;
VAL_ 1156 ND_TDOP 1022 "Init" 1023 "Fehler" ;
VAL_ 1156 ND_HDOP 1022 "Init" 1023 "Fehler" ;
VAL_ 1156 ND_GDOP 1022 "Init" 1023 "Fehler" ;
VAL_ 1156 ND_PDOP 1022 "Init" 1023 "Fehler" ;
VAL_ 1156 ND_Heading 4094 "Init" 4095 "Fehler" ;
VAL_ 1156 ND_Init 0 "nicht_Initialisiert" 1 "Initialisiert" ;
VAL_ 1157 ND_SatInUse 30 "Init" 31 "Fehler" ;
VAL_ 1157 POS_Guete_horizontal_verfuegbar 0 "nicht_verfuegbar" 1 "verfuegbar" ;
VAL_ 1157 ND_SatInView 30 "Init" 31 "Fehler" ;
VAL_ 1157 POS_Guete_horizontal 124 "von_248m_bis_400m" 125 "mehr_als_400m" 126 "Init" 127 "Fehler" ;
VAL_ 1157 NP_Altitude 4094 "Init" 4095 "Fehler" ;
VAL_ 2527679512 ND_Timezone_Offset 14 "Init" 15 "Fehler" ;
VAL_ 2527679512 ND_Timezone_SignBit 0 "PLUS_Vorzeichen" 1 "MINUS_Vorzeichen" ;
VAL_ 2527679512 ND_Timezone_Validity 0 "invalid" 1 "valid" ;
VAL_ 2527679512 ND_TimeToDestination 510 "Fehler" 511 "Init" ;
VAL_ 2527679512 ND_RouteType 0 "keine_Zielfuehrung_oder_MPR_aktiv" 1 "MPR_aktiv" 2 "Zielfuehrung_aktiv" 3 "reserviert" ;
VAL_ 2527679512 ND_TimeOffset 0 "Ziel_in_gleicher_Zeitzone" 1 "Ziel_in_Zeitzone_plus_1" 2 "Ziel_in_Zeitzone_minus_1" 3 "Zielzeitzone_groesser_plus_minus_1" ;
VAL_ 2527679512 ND_Fuelstation_detected 0 "nicht_verbaut" 1 "Tankstelle_nicht_erkannt" 2 "Tankstelle_erkannt" 3 "Init" ;
VAL_ 2527679512 ND_Velocity 1022 "Init" 1023 "Fehler" ;
VAL_ 2527679512 ND_RecDelay 4094 "Init" 4095 "Fehler" ;
VAL_ 2527679512 ND_SendDelay 4094 "Init" 4095 "Fehler" ;
VAL_ 2527679665 ND_Avrg_Speed_RangeData 254 "Init" 255 "Fehler" ;
VAL_ 1158 NP_LatDegree 134217726 "Init" 134217727 "Fehler" ;
VAL_ 1158 NP_LongDegree 268435454 "Init" 268435455 "Fehler" ;
VAL_ 1158 NP_LatDirection 0 "Nord" 1 "Sued" ;
VAL_ 1158 NP_LongDirection 0 "Ost" 1 "West" ;
VAL_ 1158 NP_Sat 30 "Init" 31 "Fehler" ;
VAL_ 1158 NP_Fix 0 "Init" 1 "No_Fix" 2 "2D_Fix" 3 "3D_Fix" ;
VAL_ 2589283496 POS_MUX 0 "MUX_0" 1 "MUX_1" 2 "reserved" 3 "Init" ;
VAL_ 2589283496 POS_ODD_EVEN 0 "ODD" 1 "EVEN" ;
VAL_ 2589283496 POS_PosStati 0 "Init" 1 "NoNavAvailable" 2 "NoMapAvailable" 3 "NavBooting" 4 "NavError" 5 "NavCalibrating" 6 "NavNoGpsResyncSince1h" 7 "NavOffroadParkgarageRampOffset2" 8 "DeadReckoningWithoutGps" 9 "DeadReckoningWithGps" 10 "MapMatchedLowConfidence" 11 "MapMatchedLimitedConfidence" 12 "OffroadHighConfidence" 13 "MapMatchedHighConfidence" 14 "PosInSyncWithGpsAndMAP" ;
VAL_ 2589283496 POS_LatDirection 0 "North" 1 "South" ;
VAL_ 2589283496 POS_LatDegree 134217726 "Init" 134217727 "Fehler" ;
VAL_ 2589283496 POS_Heading_Trust 0 "Init" 1 "TrustLevel01" 2 "TrustLevel02" 3 "Fehler" ;
VAL_ 2589283496 POS_LongDirection 0 "East" 1 "West" ;
VAL_ 2589283496 POS_LongDegree 268435454 "Init" 268435455 "Fehler" ;
VAL_ 2527679647 Stellgliedtest_NFC 0 "Init_kein_Stellgliedtest" 1 "Stellgliedtest_angefordert" ;
VAL_ 2527679647 NFC_ESM_aktivieren 0 "Init_kein_ESM" 1 "ESM_aktivieren" ;
VAL_ 2527679647 ZV_auf_NFC 0 "Init_keine_Meldung" 1 "ZV_auf_NFC" ;
VAL_ 2527679647 ZV_zu_NFC 0 "Init_keine_Meldung" 1 "ZV_zu_NFC" ;
VAL_ 2527679647 NFC_Front_Verr_Authorisiert 0 "kein_NFC_Handy_erkannt" 1 "NFC_Handy_erkannt_und_authorisiert" ;
VAL_ 2527679647 NFC_Front_Entr_Authorisiert 0 "kein_NFC_Handy_erkannt" 1 "NFC_Handy_erkannt_und_authorisiert" ;
VAL_ 2527679647 NFC_HD_Verriegelung_Authorisiert 0 "kein_NFC_Handy_erkannt" 1 "NFC_Handy_erkannt_und_authorisiert" ;
VAL_ 2527679647 NFC_HD_Entriegelung_Authorisiert 0 "kein_NFC_Handy_erkannt" 1 "NFC_Handy_erkannt_und_authorisiert" ;
VAL_ 2527679647 NFC_aktiv 0 "NFC_nicht_aktiv" 1 "NFC_Kommunikation_aktiv" ;
VAL_ 2527679647 NFC_Laden_unterbrechen 0 "Laden_nicht_unterbrechen" 1 "Laden_unterbrechen" ;
VAL_ 2527679647 NFC_FT_Entriegelung_Authorisiert 0 "kein_NFC_Handy_erkannt" 1 "NFC_Handy_erkannt_und_authorisie" ;
VAL_ 2527679647 NFC_FT_Verriegelung_Authorisiert 0 "kein_NFC_Handy_erkannt" 1 "NFC_Handy_erkannt_und_authorisiert" ;
VAL_ 2527679645 NFC_MiKo_Fehler 0 "SG_iO" 1 "SG_defekt" 2 "Antenne_defekt" 4 "Unterspannung" 8 "Ueberspannung" 16 "Ueberhitzung" ;
VAL_ 2527679645 NFC_MiKo_NFC_Device_gekoppelt 0 "Init_kein_NFC_Device_gekoppelt" 1 "NFC_Device_gekoppelt" ;
VAL_ 2527679645 NFC_MiKo_Laden_unterbrechen 0 "Init_keine_Unterbrechung" 1 "Laden_unterbrechen" ;
VAL_ 2527679645 NFC_MiKo_ESM_aktiv 0 "Init_kein_ESM" 1 "ESM_aktiv" ;
VAL_ 1696 NV_aktiv 0 "NV nicht aktiv" 1 "NV aktiv" ;
VAL_ 1696 NV_Texte 0 "Init" 1 "Abblendlicht_einschalten" 2 "Fussgaengermarkierung_n_v" 3 "zur_Zeit_nicht_verfuegbar" 4 "Systemfehler" 5 "Fussgaengermarkierung_deakt" 6 "Blindheit_erkannt" 7 "kein_Text" ;
VAL_ 1696 NV_Gong 0 "kein_Gong" 1 "Gong_leise" 2 "Gong_mittel" 3 "Gong_laut" ;
VAL_ 1696 NV_Symbol 0 "kein_Symbol_anzeigen" 1 "Symbol_fuer_erkanntes_Objekt_anzeigen" ;
VAL_ 1696 NV_Hinweise 0 "keine_Anzeige" 1 "Disclaimer" 2 "Fussgaenger_Markierung_nicht_verfuegbar" 3 "Nachtsichtsystem_wird_initialisiert" ;
VAL_ 1696 NV_Piktogramm_aktiv 0 "keine_Anzeigenprioritaet" 1 "Anzeigenprioritaet" ;
VAL_ 1696 NV_Akustik_deaktiviert_Icon 0 "aus" 1 "ein" ;
VAL_ 1696 NV_FGM_deaktiviert_Icon 0 "aus" 1 "ein" ;
VAL_ 1696 NV_Markierungslicht_links 0 "Aus" 1 "Ein" ;
VAL_ 1696 NV_Markierungslicht_rechts 0 "Aus" 1 "Ein" ;
VAL_ 1696 NV_Symbol_Tierwarnung 0 "Aus" 1 "Ein" ;
VAL_ 1696 NV_Anf_Prefill 0 "nicht_angefordert" 1 "angefordert" ;
VAL_ 1696 NV_HBA_Parameter 0 "Defaultparametersatz" 1 "Parametersatz_mit_leicht_erhoehter_Empfindlichkeit" 2 "Parametersatz_mit_erhoehter_Empfindlichkeit" 3 "Parametersatz_mit_hoechster_Empfindlichkeit" ;
VAL_ 1696 NV_LED_Leiste 0 "AUS_keine_Anzeige" 1 "Stufe_1_glimmen" 2 "Stufe_2_leuchten" 3 "Stufe_3_blinken" ;
VAL_ 1696 NV_PreSense_Status 0 "Init" 1 "verfuegbar" 2 "nicht_verfuegbar" ;
VAL_ 1696 NV_PreSense_Modus_System 0 "deaktiviert" 1 "aktiviert" ;
VAL_ 1696 NV_PreSense_Modus_Warnung 0 "Aus" 1 "Setting_2" 2 "Setting_3" 3 "Setting_4" 4 "Setting_5" 5 "Ein" ;
VAL_ 1696 NV_FAS_Fkt_Status 0 "Init" 1 "Funktion_Ist_Ein" 2 "Funktion_Ist_Aus" 3 "Fehler" ;
VAL_ 1696 NV_Akt_Status_MMI 0 "deaktiviert" 1 "aktiviert" 3 "Init" ;
VAL_ 1696 NV_AnforderungBildaufschaltung 0 "KeineBildaufschaltung" 1 "Bildaufschaltung" ;
VAL_ 2600468622 NM_BedienDisp_vo_SNI 142 "BedienDisp_vo" ;
VAL_ 2600468622 NM_BedienDisp_vo_CBV_AWB 0 "Passiver_WakeUp" 1 "Aktiver_WakeUp" ;
VAL_ 2600468622 NM_BedienDisp_vo_CBV_CRI 0 "Standard_Layout" 1 "TNB_Layout" ;
VAL_ 2600468622 NM_BedienDisp_vo_NM_State 0 "Init" 1 "NM_RM_aus_BSM" 2 "NM_RM_aus_PBSM" 4 "NM_NO_aus_RM" 8 "NM_NO_aus_RS" 16 "reserved" 32 "reserved" ;
VAL_ 2600468622 NM_BedienDisp_vo_Car_Wakeup 0 "Inaktiv" 1 "Car_Wakeup" ;
VAL_ 2600468622 NM_BedienDisp_vo_UDS_CC 0 "Init" 1 "CC_aktiv" ;
VAL_ 2600468622 NM_BedienDisp_vo_NM_aktiv_KL15 0 "Inaktiv" 1 "KL15_EIN" ;
VAL_ 2600468622 NM_BedienDisp_vo_NM_aktiv_Diag 0 "Inaktiv" 1 "Diagnose_aktiv" ;
VAL_ 2600468622 NM_BedienDisp_vo_NM_aktiv_Tmin 0 "Inaktiv" 1 "Mindestaktivzeit" ;
VAL_ 2600468622 NM_BedienDisp_vo_NM_aktiv_Restwa 0 "Inaktiv" 1 "Anforderung_Restwaerme" ;
VAL_ 2600468622 NM_BedienDisp_vo_CAB 0 "inaktiv" 1 "CAB_01__Tueren" 2 "CAB_02__Anhaenger_KCAN" 4 "CAB_03__Nightvision" 8 "CAB_04__Sitzverstellung" 16 "CAB_05__Klappen" 32 "CAB_06__Infotainment" 64 "CAB_07__Sub_Infotainment" 128 "CAB_08__Anzeige" 256 "CAB_09__Laden_HCAN" 512 "CAB_10__Klima" 1024 "CAB_11__FlexRay" 262144 "CAB_19__VLAN_RemoteFC" 524288 "CAB_20__VLAN_Komfort" 1048576 "CAB_21__VLAN_Internet" 2097152 "CAB_22__VLAN_Connect" 4194304 "CAB_23__VLAN_Infotainment" 8388608 "CAB_24__VLAN_FAS" ;
VAL_ 2600468627 NM_BedienSG_hi_SNI 147 "BedienSG_hi" ;
VAL_ 2600468627 NM_BedienSG_hi_CBV_AWB 0 "Passiver_WakeUp" 1 "Aktiver_WakeUp" ;
VAL_ 2600468627 NM_BedienSG_hi_CBV_CRI 0 "Standard_Layout" 1 "TNB_Layout" ;
VAL_ 2600468627 NM_BedienSG_hi_NM_State 0 "Init" 1 "NM_RM_aus_BSM" 2 "NM_RM_aus_PBSM" 4 "NM_NO_aus_RM" 8 "NM_NO_aus_RS" 16 "reserved" 32 "reserved" ;
VAL_ 2600468627 NM_BedienSG_hi_Car_Wakeup 0 "Inaktiv" 1 "Car_Wakeup" ;
VAL_ 2600468627 NM_BedienSG_hi_UDS_CC 0 "Init" 1 "CC_aktiv" ;
VAL_ 2600468627 NM_BedienSG_hi_NM_aktiv_KL15 0 "Inaktiv" 1 "KL15_EIN" ;
VAL_ 2600468627 NM_BedienSG_hi_NM_aktiv_Diagnose 0 "Inaktiv" 1 "Diagnose_aktiv" ;
VAL_ 2600468627 NM_BedienSG_hi_NM_aktiv_Tmin 0 "Inaktiv" 1 "Mindestaktivzeit" ;
VAL_ 2600468627 NM_BedienSG_hi_CAB 0 "inaktiv" 1 "CAB_01__Tueren" 2 "CAB_02__Anhaenger_KCAN" 4 "CAB_03__Nightvision" 8 "CAB_04__Sitzverstellung" 16 "CAB_05__Klappen" 32 "CAB_06__Infotainment" 64 "CAB_07__Sub_Infotainment" 128 "CAB_08__Anzeige" 256 "CAB_09__Laden_HCAN" 512 "CAB_10__Klima" 1024 "CAB_11__FlexRay" 262144 "CAB_19__VLAN_RemoteFC" 524288 "CAB_20__VLAN_Komfort" 1048576 "CAB_21__VLAN_Internet" 2097152 "CAB_22__VLAN_Connect" 4194304 "CAB_23__VLAN_Infotainment" 8388608 "CAB_24__VLAN_FAS" ;
VAL_ 2600468666 NM_DDA_SNI 186 "DDA" ;
VAL_ 2600468666 NM_DDA_CBV_AWB 0 "Passiver_WakeUp" 1 "Aktiver_WakeUp" ;
VAL_ 2600468666 NM_DDA_CBV_CRI 0 "Standard_Layout" 1 "TNB_Layout" ;
VAL_ 2600468666 NM_DDA_NM_State 0 "Init" 1 "NM_RM_aus_BSM" 2 "NM_RM_aus_PBSM" 4 "NM_NO_aus_RM" 8 "NM_NO_aus_RS" 16 "reserved" 32 "reserved" ;
VAL_ 2600468666 NM_DDA_Car_Wakeup 0 "Inaktiv" 1 "Car_Wakeup" ;
VAL_ 2600468666 NM_DDA_UDS_CC 0 "Init" 1 "CC_aktiv" ;
VAL_ 2600468666 NM_DDA_NM_aktiv_KL15 0 "Inaktiv" 1 "KL15_EIN" ;
VAL_ 2600468666 NM_DDA_NM_aktiv_Diagnose 0 "Init" 1 "Diagnose_aktiv" ;
VAL_ 2600468666 NM_DDA_NM_aktiv_Tmin 0 "Inaktiv" 1 "Mindestaktivzeit" ;
VAL_ 2600468666 NM_DDA_NM_aktiv_BT_Verbindung 0 "Inaktiv" 1 "BT_Verbindung_aktiv" ;
VAL_ 2600468666 NM_DDA_CAB 0 "inaktiv" 1 "CAB_01__Tueren" 2 "CAB_02__Anhaenger_KCAN" 4 "CAB_03__Nightvision" 8 "CAB_04__Sitzverstellung" 16 "CAB_05__Klappen" 32 "CAB_06__Infotainment" 64 "CAB_07__Sub_Infotainment" 128 "CAB_08__Anzeige" 256 "CAB_09__Laden_HCAN" 512 "CAB_10__Klima" 1024 "CAB_11__FlexRay" 262144 "CAB_19__VLAN_RemoteFC" 524288 "CAB_20__VLAN_Komfort" 1048576 "CAB_21__VLAN_Internet" 2097152 "CAB_22__VLAN_Connect" 4194304 "CAB_23__VLAN_Infotainment" 8388608 "CAB_24__VLAN_FAS" ;
VAL_ 2600468496 NM_Gateway_SNI 16 "Gateway" ;
VAL_ 2600468496 NM_Gateway_CBV_AWB 0 "Passiver_WakeUp" 1 "Aktiver_WakeUp" ;
VAL_ 2600468496 NM_Gateway_CBV_CRI 0 "NM_ohne_Clusteranforderungen" 1 "NM_mit_Clusteranforderungen" ;
VAL_ 2600468496 NM_Gateway_NM_State 0 "Init" 1 "NM_RM_aus_BSM" 2 "NM_RM_aus_PBSM" 4 "NM_NO_aus_RM" 8 "NM_NO_aus_RS" 16 "reserved" 32 "reserved" ;
VAL_ 2600468496 NM_Gateway_Car_Wakeup 0 "Inaktiv" 1 "Car_Wakeup" ;
VAL_ 2600468496 NM_Gateway_UDS_CC 0 "Inaktiv" 1 "CC_aktiv" ;
VAL_ 2600468496 NM_Gateway_NM_aktiv_KL15 0 "Inaktiv" 1 "KL15_EIN" ;
VAL_ 2600468496 NM_Gateway_NM_aktiv_Diagnose 0 "Init" 1 "Diagnose_aktiv" ;
VAL_ 2600468496 NM_Gateway_NM_aktiv_Tmin 0 "Inaktiv" 1 "Mindestaktivzeit" ;
VAL_ 2600468496 NM_Gateway_NM_aktiv_CWU 0 "kein_CWU_gesetzt" 1 "CWU_gesetzt" ;
VAL_ 2600468496 NM_Gateway_NM_aktiv_FC 0 "kein_FC_gesetzt" 1 "FC_gesetzt" ;
VAL_ 2600468496 NM_Gateway_NM_aktiv_Connect 0 "inaktiv" 1 "Nachlauf_aufgrund_Connect" ;
VAL_ 2600468496 NM_Gateway_NM_aktiv_EM 0 "inaktiv" 1 "Nachlauf_aufgrund_Energiemanagement" ;
VAL_ 2600468496 NM_Gateway_NM_aktiv_OBDC 0 "kein_Nachlauf" 1 "Nachlauf_aufgrund_OBDC" ;
VAL_ 2600468496 NM_Gateway_NM_aktiv_Buskopplung 0 "inaktiv" 1 "Nachlauf_aufgrund_Buskopplung" ;
VAL_ 2600468496 NM_Gateway_NM_aktiv_LIN2 0 "Inaktiv" 1 "LIN2_aktiv" ;
VAL_ 2600468496 NM_Gateway_CAB 0 "inaktiv" 1 "CAB_01__Tueren" 2 "CAB_02__Anhaenger_KCAN" 4 "CAB_03__Nightvision" 8 "CAB_04__Sitzverstellung" 16 "CAB_05__Klappen" 32 "CAB_06__Infotainment" 64 "CAB_07__Sub_Infotainment" 128 "CAB_08__Anzeige" 256 "CAB_09__Laden_HCAN" 512 "CAB_10__Klima" 1024 "CAB_11__FlexRay" 262144 "CAB_19__VLAN_RemoteFC" 524288 "CAB_20__VLAN_Komfort" 1048576 "CAB_21__VLAN_Internet" 2097152 "CAB_22__VLAN_Connect" 4194304 "CAB_23__VLAN_Infotainment" 8388608 "CAB_24__VLAN_FAS" ;
VAL_ 2600468595 NM_Info_El_SNI 115 "Info_El" ;
VAL_ 2600468595 NM_Info_El_CBV_AWB 0 "Passiver_WakeUp" 1 "Aktiver_WakeUp" ;
VAL_ 2600468595 NM_Info_El_CBV_CRI 0 "NM_ohne_Clusteranforderungen" 1 "NM_mit_Clusteranforderungen" ;
VAL_ 2600468595 NM_Info_El_NM_State 0 "Init" 1 "NM_RM_aus_BSM" 2 "NM_RM_aus_PBSM" 4 "NM_NO_aus_RM" 8 "NM_NO_aus_RS" 16 "reserved" 32 "reserved" ;
VAL_ 2600468595 NM_Info_El_Car_Wakeup 0 "Inaktiv" 1 "Car_Wakeup" ;
VAL_ 2600468595 NM_Info_El_UDS_CC 0 "Inaktiv" 1 "CC_aktiv" ;
VAL_ 2600468595 NM_Info_El_NM_aktiv_KL15 0 "Inaktiv" 1 "KL15_EIN" ;
VAL_ 2600468595 NM_Info_El_NM_aktiv_Diagnose 0 "Init" 1 "Diagnose_aktiv" ;
VAL_ 2600468595 NM_Info_El_NM_aktiv_Tmin 0 "Inaktiv" 1 "Mindestaktivzeit" ;
VAL_ 2600468595 NM_Info_El_NM_aktiv_MIBCAN 0 "Init" 1 "MIB_CAN_aktiv" ;
VAL_ 2600468595 NM_Info_El_CAB 0 "inaktiv" 1 "CAB_01__Tueren" 2 "CAB_02__Anhaenger_KCAN" 4 "CAB_03__Nightvision" 8 "CAB_04__Sitzverstellung" 16 "CAB_05__Klappen" 32 "CAB_06__Infotainment" 64 "CAB_07__Sub_Infotainment" 128 "CAB_08__Anzeige" 256 "CAB_09__Laden_HCAN" 512 "CAB_10__Klima" 1024 "CAB_11__FlexRay" 262144 "CAB_19__VLAN_RemoteFC" 524288 "CAB_20__VLAN_Komfort" 1048576 "CAB_21__VLAN_Internet" 2097152 "CAB_22__VLAN_Connect" 4194304 "CAB_23__VLAN_Infotainment" 8388608 "CAB_24__VLAN_FAS" ;
VAL_ 2600468482 NM_Sekundaer_02_SNI 2 "Sekundaer_02" ;
VAL_ 2600468482 NM_Sekundaer_02_CBV_AWB 0 "Passiver_WakeUp" 1 "Aktiver_WakeUp" ;
VAL_ 2600468482 NM_Sekundaer_02_CBV_CRI 0 "Standard_Layout" 1 "TNB_Layout" ;
VAL_ 2600468482 NM_Sekundaer_02_NM_State 0 "Init" 1 "NM_RM_aus_BSM" 2 "NM_RM_aus_PBSM" 4 "NM_NO_aus_RM" 8 "NM_NO_aus_RS" ;
VAL_ 2600468482 NM_Sekundaer_02_Car_Wakeup 0 "Inaktiv" 1 "Car_Wakeup" ;
VAL_ 2600468482 NM_Sekundaer_02_UDS_CC 0 "Init" 1 "CC_aktiv" ;
VAL_ 2600468482 NM_Sekundaer_02_NM_aktiv_KL15 0 "Inaktiv" 1 "KL15_EIN" ;
VAL_ 2600468482 NM_Sekundaer_02_NM_aktiv_Diag 0 "Init" 1 "Diagnose_aktiv" ;
VAL_ 2600468482 NM_Sekundaer_02_NM_aktiv_Tmin 0 "Inaktiv" 1 "Mindestaktivzeit" ;
VAL_ 2600468482 NM_Sekundaer_02_CAB 0 "inaktiv" 1 "CAB_01__Tueren" 2 "CAB_02__Anhaenger_KCAN" 4 "CAB_03__Nightvision" 8 "CAB_04__Sitzverstellung" 16 "CAB_05__Klappen" 32 "CAB_06__Infotainment" 64 "CAB_07__Sub_Infotainment" 128 "CAB_08__Anzeige" 256 "CAB_09__Laden_HCAN" 512 "CAB_10__Klima" 1024 "CAB_11__FlexRay" 262144 "CAB_19__VLAN_RemoteFC" 524288 "CAB_20__VLAN_Komfort" 1048576 "CAB_21__VLAN_Internet" 2097152 "CAB_22__VLAN_Connect" 4194304 "CAB_23__VLAN_Infotainment" 8388608 "CAB_24__VLAN_FAS" ;
VAL_ 1377 NV_Obj_01_InvTTCBildebStdA 127 "Init" ;
VAL_ 1377 NV_Obj_Warnung_Fussgaenger 0 "inaktiv" 1 "aktiv" ;
VAL_ 1377 NV_Obj_Rechts 0 "nicht_erkannt" 1 "erkannt" ;
VAL_ 1377 NV_Obj_Links 0 "nicht_erkannt" 1 "erkannt" ;
VAL_ 1377 NV_Obj_01_Klasse 0 "unbekannt" 1 "ueberfahrbar" 2 "unterfahrbar" 3 "Fussgaenger" 4 "Fussgaengergruppe" 5 "Fahrrad" 6 "Motorrad" 7 "PKW" 8 "Van" 9 "LKW" 10 "Randbebauung" 11 "Tier" 12 "Retroreflektor" 15 "Init" ;
VAL_ 1377 NV_MessZeitpunkt 8191 "Init" ;
VAL_ 1377 NV_Sensor_PositionY 2047 "Init" ;
VAL_ 1377 NV_Sensor_PositionX 4095 "Init" ;
VAL_ 1377 NV_Sensor_PositionZ 2047 "Init" ;
VAL_ 1377 NV_NichtVerfuegbar 0 "NV_verfuegbar" 1 "NV_nicht_verfuegbar" ;
VAL_ 1635 BEM_02_Abschaltstufen 0 "Stufe 0 (keine Einschraenkungen)" 1 "Stufe 1" 2 "Stufe 2" 3 "Stufe 3" 4 "Transportmodus" 7 "Ruhestrommessmodus" ;
VAL_ 1635 BEM_STH_Zielzeit 14 "Init" 15 "Fehler" ;
VAL_ 1635 BEM_MMI_Vorwarnung 0 "keine Anzeige" 1 "Anzeige MMI-Vorwarnung" ;
VAL_ 1635 NVEM_Anf_SD_schalten 0 "Anf_SD_Nachlauf_nicht_aktiv" 1 "Anf_SD_Nachlauf_aktiv" ;
VAL_ 1635 BEM_Generatordiagnose 0 "keine Anzeige" 1 "Ladekontrollanzeige ein (Vorhalt)" 2 "rotes Batteriesymbol und Text (Generator defekt)" 3 "Hybrid_DCDC_Wandler_defekt" ;
VAL_ 1635 BEM_Red_Innengeblaese 0 "keine Reduzierung" 1 "Reduzierung Stufe 1" 2 "Reduzierung Stufe 2" 3 "Reduzierung Stufe 2 und Abschaltung Kompressor" ;
VAL_ 1635 BEM_STH_Einschaltverbot 0 "volle Verfuegbarkeit Standheizung/-lueftung" 1 "Standheizung/-lueftung nicht aktivierbar" ;
VAL_ 1635 BEM_HL_Regelung_Status 0 "HL_Regelung_inaktiv_(vor_und_waehrend_Motorstart)" 1 "HL_Regelung_Stufe_1" 2 "HL_Regelung_Stufe_2" 3 "HL_Regelung_Stufe_3" 4 "Verbrauchernotabschaltung_(VNA)" 5 "HL_Regelung_Stufe_5" 7 "Default" ;
VAL_ 1635 BEM_Ladezustand 14 "Init" 15 "Fehler" ;
VAL_ 1635 BEM_Batteriediagnose 0 "keine_Anzeige" 1 "nicht_belegt" 2 "Anzeige_aberkannte_Batterie" 3 "Anzeige_schwache_Batterie" 4 "Anzeige_Batterie_OK" 5 "Anzeige_Batterie_Laden" 6 "Anzeige_Batterie_Pruefen" 7 "Fehler" ;
VAL_ 1635 MIB_Stromsparmodus 0 "inaktiv" 1 "aktiv" ;
VAL_ 1635 BEM_REK_aktiv 0 "keine_Rekuperationsfreigabe" 1 "Rekuperationsfreigabe" ;
VAL_ 1635 NVEM_Last_Anf 0 "keine Anforderung" 1 "Verbraucher_Anforderung_Stufe_1" 2 "Verbraucher_Anforderung_Stufe_2" 3 "Verbraucher_Anforderung_Stufe_3" ;
VAL_ 1635 BEM_UBDM 0 "Init" 255 "Fehler" ;
VAL_ 1635 BEM_Anf_KL15_schalten 0 "Keine_Einschraenkung_Kl15" 1 "Empfehlung_auto_Abschaltung_Kl15" 2 "Veto_auto_Abschaltung_Kl15" 3 "Veto_auto_Abschaltung_Fahrtbetrieb" ;
VAL_ 1635 NVEM_Batterie_Service 0 "kein_Service" 1 "Service_Information1" 2 "Service_Information2" 3 "Service_Information3" ;
VAL_ 1635 NVEM_Freigabe_OnlineUpdate 0 "keine_Freigabe" 1 "Freigabe" ;
VAL_ 1635 NVEM_Freigabe_ORU4 0 "Init" 1 "keine_Freigabe" 2 "Freigabe_erteilt" 3 "Veto_Freigabe" ;
VAL_ 913 MO_Servicemodus 0 "nicht_aktiv" 1 "Service_Mode_1" 2 "Service_Mode_2" 3 "Service_Mode_3" 4 "Service_Mode_4" 5 "Service_Mode_5" 6 "Service_Mode_6" 7 "Service_Mode_7" 8 "Service_Mode_8" 9 "Service_Mode_9" 10 "Service_Mode_10" 11 "Service_Mode_11" 12 "Service_Mode_12" 13 "Service_Mode_13" 14 "Service_Mode_14" 15 "Service_Mode_15" ;
VAL_ 913 OBD_ClearMem_Inhibit 0 "FSP_Loeschen_zulaessig" 1 "FSP_Loeschen_nicht_zulaessig" ;
VAL_ 913 OBD_Sperrung_Kaltstart_Denom 0 "EVAP_Berechnung_freigegeben" 1 "EVAP_Berechnung_gesperrt" ;
VAL_ 913 MO_QBit_Aussen_Temp 0 "gueltiger_Wert" 1 "Ersatz_Init_oder_Fehlerwert" ;
VAL_ 913 OBD_Sperrung_IUMPR 0 "IUMPR_Berechnung_freigegeben" 1 "IUMPR_Berechnung_gesperrt" ;
VAL_ 913 OBD_Kaltstart_Denominator 0 "Denominator_nicht_hochzaehlen" 1 "Bedingungen_zum_Inkr_des_Kaltstart_Denom_erf" ;
VAL_ 913 OBD_Minimum_Trip 0 "kein_Min_Normed_Trip" 1 "Min_Normed_Trip" ;
VAL_ 913 OBD_Driving_Cycle 0 "kein Driving Cycle erkannt" 1 "DC erkannt" ;
VAL_ 913 OBD_Warm_Up_Cycle 0 "kein Warm Up Cycle erkannt" 1 "Warm Up Cycle erkannt" ;
VAL_ 913 OBD_Normed_Trip 0 "kein_Normed_Trip" 1 "Normed_Trip" ;
VAL_ 2589283656 ORU_Warnung 0 "keine_Anzeige" 1 "Update_unvollstaendig_Prio1" 2 "Update_fehlgeschlagen_Prio1" 3 "reserviert" ;
VAL_ 2589283656 ORU_Status 0 "IDLE" 1 "PENDING" 2 "PREPARATION" 3 "PREPARATION_HV" 4 "RUNNING" 5 "RUNNING_HV" 6 "PENDING_NOTREADY" 7 "FAILURE_POWERTRAIN_DISABLED" ;
